VERSION ""

NS_ :

BS_:

BU_: External_Tool CADM LRRF MRRRL MRRRR

BO_ 75 LRRF1_Detection_008_014: 64 LRRF
 SG_ LRRF1_CAN_DET_Near_TARGET_14 : 454|1@0+ (1,0) [0|1] ""  CADM
 SG_ LRRF1_CAN_DET_Near_TARGET_13 : 453|1@0+ (1,0) [0|1] ""  CADM
 SG_ LRRF1_CAN_DET_Near_TARGET_12 : 452|1@0+ (1,0) [0|1] ""  CADM
 SG_ LRRF1_CAN_DET_Near_TARGET_11 : 451|1@0+ (1,0) [0|1] ""  CADM
 SG_ LRRF1_CAN_DET_Near_TARGET_10 : 450|1@0+ (1,0) [0|1] ""  CADM
 SG_ LRRF1_CAN_DET_Near_TARGET_09 : 449|1@0+ (1,0) [0|1] ""  CADM
 SG_ LRRF1_CAN_DET_Near_TARGET_08 : 448|1@0+ (1,0) [0|1] ""  CADM
 SG_ LRRF1_CAN_DET_ELEVATION_08 : 63|7@0+ (0.002748,-0.1745) [-0.1745|0.174496] "rad"  CADM
 SG_ LRRF1_CAN_DET_CONFID_AZIMUTH_08 : 33|2@0+ (1,0) [0|3] ""  CADM
 SG_ LRRF1_CAN_DET_SUPER_RES_TARGET_0 : 56|1@0+ (1,0) [0|1] ""  CADM
 SG_ LRRF1_CAN_DET_CONFID_ELEVATION_0 : 48|1@0+ (1,0) [0|1] ""  CADM
 SG_ LRRF1_CAN_DET_HOST_VEH_CLUTTER_0 : 49|1@0+ (1,0) [0|1] ""  CADM
 SG_ LRRF1_CAN_DET_VALID_LEVEL_08 : 0|1@0+ (1,0) [0|1] ""  CADM
 SG_ LRRF1_CAN_DET_AZIMUTH_08 : 47|14@0+ (0.0003834,-3.1416) [-3.1416|3.1396422] "rad"  CADM
 SG_ LRRF1_CAN_DET_RANGE_08 : 31|14@0+ (0.015625,0) [0|255.984375] "m"  CADM
 SG_ LRRF1_CAN_DET_RANGE_RATE_08 : 15|14@0+ (0.015625,-128) [-128|127.984375] "m/s"  CADM
 SG_ LRRF1_CAN_DET_AMPLITUDE_08 : 7|7@0+ (1,-64) [-64|63] "dBsm"  CADM
 SG_ LRRF1_CAN_SCAN_INDEX_2LSB_08 : 17|2@0+ (1,0) [0|3] ""  CADM
 SG_ LRRF1_Det_CRC_02 : 503|16@0+ (1,0) [0|65535] ""  CADM
 SG_ LRRF1_Det_MC_02 : 491|4@0+ (1,0) [0|15] ""  CADM
 SG_ LRRF1_CAN_SCAN_INDEX_2LSB_14 : 401|2@0+ (1,0) [0|3] ""  CADM
 SG_ LRRF1_CAN_SCAN_INDEX_2LSB_13 : 337|2@0+ (1,0) [0|3] ""  CADM
 SG_ LRRF1_CAN_SCAN_INDEX_2LSB_12 : 273|2@0+ (1,0) [0|3] ""  CADM
 SG_ LRRF1_CAN_SCAN_INDEX_2LSB_11 : 209|2@0+ (1,0) [0|3] ""  CADM
 SG_ LRRF1_CAN_SCAN_INDEX_2LSB_10 : 145|2@0+ (1,0) [0|3] ""  CADM
 SG_ LRRF1_CAN_SCAN_INDEX_2LSB_09 : 81|2@0+ (1,0) [0|3] ""  CADM
 SG_ LRRF1_CAN_DET_RANGE_RATE_14 : 399|14@0+ (0.015625,-128) [-128|127.984375] "m/s"  CADM
 SG_ LRRF1_CAN_DET_RANGE_RATE_13 : 335|14@0+ (0.015625,-128) [-128|127.984375] "m/s"  CADM
 SG_ LRRF1_CAN_DET_RANGE_RATE_12 : 271|14@0+ (0.015625,-128) [-128|127.984375] "m/s"  CADM
 SG_ LRRF1_CAN_DET_RANGE_RATE_11 : 207|14@0+ (0.015625,-128) [-128|127.984375] "m/s"  CADM
 SG_ LRRF1_CAN_DET_RANGE_RATE_10 : 143|14@0+ (0.015625,-128) [-128|127.984375] "m/s"  CADM
 SG_ LRRF1_CAN_DET_RANGE_RATE_09 : 79|14@0+ (0.015625,-128) [-128|127.984375] "m/s"  CADM
 SG_ LRRF1_CAN_DET_RANGE_14 : 415|14@0+ (0.015625,0) [0|255.984375] "m"  CADM
 SG_ LRRF1_CAN_DET_RANGE_13 : 351|14@0+ (0.015625,0) [0|255.984375] "m"  CADM
 SG_ LRRF1_CAN_DET_RANGE_12 : 287|14@0+ (0.015625,0) [0|255.984375] "m"  CADM
 SG_ LRRF1_CAN_DET_RANGE_11 : 223|14@0+ (0.015625,0) [0|255.984375] "m"  CADM
 SG_ LRRF1_CAN_DET_RANGE_10 : 159|14@0+ (0.015625,0) [0|255.984375] "m"  CADM
 SG_ LRRF1_CAN_DET_RANGE_09 : 95|14@0+ (0.015625,0) [0|255.984375] "m"  CADM
 SG_ LRRF1_CAN_DET_SUPER_RES_TAR_0105 : 432|1@0+ (1,0) [0|1] ""  CADM
 SG_ LRRF1_CAN_DET_SUPER_RES_TAR_0106 : 368|1@0+ (1,0) [0|1] ""  CADM
 SG_ LRRF1_CAN_DET_SUPER_RES_TAR_0107 : 304|1@0+ (1,0) [0|1] ""  CADM
 SG_ LRRF1_CAN_DET_SUPER_RES_TAR_0108 : 240|1@0+ (1,0) [0|1] ""  CADM
 SG_ LRRF1_CAN_DET_SUPER_RES_TAR_0109 : 176|1@0+ (1,0) [0|1] ""  CADM
 SG_ LRRF1_CAN_DET_SUPER_RES_TAR_0110 : 112|1@0+ (1,0) [0|1] ""  CADM
 SG_ LRRF1_CAN_DET_HOST_VEH_CLUT_0105 : 433|1@0+ (1,0) [0|1] ""  CADM
 SG_ LRRF1_CAN_DET_HOST_VEH_CLUT_0106 : 369|1@0+ (1,0) [0|1] ""  CADM
 SG_ LRRF1_CAN_DET_HOST_VEH_CLUT_0107 : 305|1@0+ (1,0) [0|1] ""  CADM
 SG_ LRRF1_CAN_DET_HOST_VEH_CLUT_0108 : 241|1@0+ (1,0) [0|1] ""  CADM
 SG_ LRRF1_CAN_DET_HOST_VEH_CLUT_0109 : 177|1@0+ (1,0) [0|1] ""  CADM
 SG_ LRRF1_CAN_DET_HOST_VEH_CLUT_0110 : 113|1@0+ (1,0) [0|1] ""  CADM
 SG_ LRRF1_CAN_DET_ELEVATION_14 : 447|7@0+ (0.002748,-0.1745) [-0.1745|0.174496] "rad"  CADM
 SG_ LRRF1_CAN_DET_ELEVATION_13 : 383|7@0+ (0.002748,-0.1745) [-0.1745|0.174496] "rad"  CADM
 SG_ LRRF1_CAN_DET_ELEVATION_12 : 319|7@0+ (0.002748,-0.1745) [-0.1745|0.174496] "rad"  CADM
 SG_ LRRF1_CAN_DET_ELEVATION_11 : 255|7@0+ (0.002748,-0.1745) [-0.1745|0.174496] "rad"  CADM
 SG_ LRRF1_CAN_DET_ELEVATION_10 : 191|7@0+ (0.002748,-0.1745) [-0.1745|0.174496] "rad"  CADM
 SG_ LRRF1_CAN_DET_ELEVATION_09 : 127|7@0+ (0.002748,-0.1745) [-0.1745|0.174496] "rad"  CADM
 SG_ LRRF1_CAN_DET_CONFID_ELEVAT_0105 : 440|1@0+ (1,0) [0|1] ""  CADM
 SG_ LRRF1_CAN_DET_CONFID_ELEVAT_0106 : 376|1@0+ (1,0) [0|1] ""  CADM
 SG_ LRRF1_CAN_DET_CONFID_ELEVAT_0107 : 312|1@0+ (1,0) [0|1] ""  CADM
 SG_ LRRF1_CAN_DET_CONFID_ELEVAT_0108 : 248|1@0+ (1,0) [0|1] ""  CADM
 SG_ LRRF1_CAN_DET_CONFID_ELEVAT_0109 : 184|1@0+ (1,0) [0|1] ""  CADM
 SG_ LRRF1_CAN_DET_CONFID_ELEVAT_0110 : 120|1@0+ (1,0) [0|1] ""  CADM
 SG_ LRRF1_CAN_DET_CONFID_AZIMUTH_14 : 417|2@0+ (1,0) [0|3] ""  CADM
 SG_ LRRF1_CAN_DET_CONFID_AZIMUTH_13 : 353|2@0+ (1,0) [0|3] ""  CADM
 SG_ LRRF1_CAN_DET_CONFID_AZIMUTH_12 : 289|2@0+ (1,0) [0|3] ""  CADM
 SG_ LRRF1_CAN_DET_CONFID_AZIMUTH_11 : 225|2@0+ (1,0) [0|3] ""  CADM
 SG_ LRRF1_CAN_DET_CONFID_AZIMUTH_10 : 161|2@0+ (1,0) [0|3] ""  CADM
 SG_ LRRF1_CAN_DET_CONFID_AZIMUTH_09 : 97|2@0+ (1,0) [0|3] ""  CADM
 SG_ LRRF1_CAN_DET_AZIMUTH_14 : 431|14@0+ (0.0003834,-3.1416) [-3.1416|3.1396422] "rad"  CADM
 SG_ LRRF1_CAN_DET_AZIMUTH_13 : 367|14@0+ (0.0003834,-3.1416) [-3.1416|3.1396422] "rad"  CADM
 SG_ LRRF1_CAN_DET_AZIMUTH_12 : 303|14@0+ (0.0003834,-3.1416) [-3.1416|3.1396422] "rad"  CADM
 SG_ LRRF1_CAN_DET_AZIMUTH_11 : 239|14@0+ (0.0003834,-3.1416) [-3.1416|3.1396422] "rad"  CADM
 SG_ LRRF1_CAN_DET_AZIMUTH_10 : 175|14@0+ (0.0003834,-3.1416) [-3.1416|3.1396422] "rad"  CADM
 SG_ LRRF1_CAN_DET_AZIMUTH_09 : 111|14@0+ (0.0003834,-3.1416) [-3.1416|3.1396422] "rad"  CADM
 SG_ LRRF1_CAN_DET_AMPLITUDE_14 : 391|7@0+ (1,-64) [-64|63] "dBsm"  CADM
 SG_ LRRF1_CAN_DET_AMPLITUDE_13 : 327|7@0+ (1,-64) [-64|63] "dBsm"  CADM
 SG_ LRRF1_CAN_DET_AMPLITUDE_12 : 263|7@0+ (1,-64) [-64|63] "dBsm"  CADM
 SG_ LRRF1_CAN_DET_AMPLITUDE_11 : 199|7@0+ (1,-64) [-64|63] "dBsm"  CADM
 SG_ LRRF1_CAN_DET_AMPLITUDE_10 : 135|7@0+ (1,-64) [-64|63] "dBsm"  CADM
 SG_ LRRF1_CAN_DET_AMPLITUDE_09 : 71|7@0+ (1,-64) [-64|63] "dBsm"  CADM
 SG_ LRRF1_CAN_DET_VALID_LEVEL_14 : 384|1@0+ (1,0) [0|1] ""  CADM
 SG_ LRRF1_CAN_DET_VALID_LEVEL_13 : 320|1@0+ (1,0) [0|1] ""  CADM
 SG_ LRRF1_CAN_DET_VALID_LEVEL_12 : 256|1@0+ (1,0) [0|1] ""  CADM
 SG_ LRRF1_CAN_DET_VALID_LEVEL_11 : 192|1@0+ (1,0) [0|1] ""  CADM
 SG_ LRRF1_CAN_DET_VALID_LEVEL_10 : 128|1@0+ (1,0) [0|1] ""  CADM
 SG_ LRRF1_CAN_DET_VALID_LEVEL_09 : 64|1@0+ (1,0) [0|1] ""  CADM

BO_ 74 LRRF1_Detection_001_007: 64 LRRF
 SG_ LRRF1_CAN_DET_Near_TARGET_07 : 454|1@0+ (1,0) [0|1] ""  CADM
 SG_ LRRF1_CAN_DET_Near_TARGET_06 : 453|1@0+ (1,0) [0|1] ""  CADM
 SG_ LRRF1_CAN_DET_Near_TARGET_05 : 452|1@0+ (1,0) [0|1] ""  CADM
 SG_ LRRF1_CAN_DET_Near_TARGET_04 : 451|1@0+ (1,0) [0|1] ""  CADM
 SG_ LRRF1_CAN_DET_Near_TARGET_03 : 450|1@0+ (1,0) [0|1] ""  CADM
 SG_ LRRF1_CAN_DET_Near_TARGET_02 : 449|1@0+ (1,0) [0|1] ""  CADM
 SG_ LRRF1_CAN_DET_Near_TARGET_01 : 448|1@0+ (1,0) [0|1] ""  CADM
 SG_ LRRF1_CAN_DET_ELEVATION_01 : 63|7@0+ (0.002748,-0.1745) [-0.1745|0.174496] "rad"  CADM
 SG_ LRRF1_CAN_DET_CONFID_AZIMUTH_01 : 33|2@0+ (1,0) [0|3] ""  CADM
 SG_ LRRF1_CAN_DET_SUPER_RES_TAR_0111 : 48|1@0+ (1,0) [0|1] ""  CADM
 SG_ LRRF1_CAN_DET_CONFID_ELEVAT_0111 : 56|1@0+ (1,0) [0|1] ""  CADM
 SG_ LRRF1_CAN_DET_HOST_VEH_CLUT_0111 : 49|1@0+ (1,0) [0|1] ""  CADM
 SG_ LRRF1_CAN_DET_VALID_LEVEL_01 : 0|1@0+ (1,0) [0|1] ""  CADM
 SG_ LRRF1_CAN_DET_AZIMUTH_01 : 47|14@0+ (0.0003834,-3.1416) [-3.1416|3.1396422] "rad"  CADM
 SG_ LRRF1_CAN_DET_RANGE_01 : 31|14@0+ (0.015625,0) [0|255.984375] "m"  CADM
 SG_ LRRF1_CAN_DET_RANGE_RATE_01 : 15|14@0+ (0.015625,-128) [-128|127.984375] "m/s"  CADM
 SG_ LRRF1_CAN_DET_AMPLITUDE_01 : 7|7@0+ (1,-64) [-64|63] "dBsm"  CADM
 SG_ LRRF1_CAN_SCAN_INDEX_2LSB_01 : 17|2@0+ (1,0) [0|3] ""  CADM
 SG_ LRRF1_Det_CRC_01 : 503|16@0+ (1,0) [0|65535] ""  CADM
 SG_ LRRF1_Det_MC_01 : 491|4@0+ (1,0) [0|15] ""  CADM
 SG_ LRRF1_CAN_SCAN_INDEX_2LSB_07 : 401|2@0+ (1,0) [0|3] ""  CADM
 SG_ LRRF1_CAN_SCAN_INDEX_2LSB_06 : 337|2@0+ (1,0) [0|3] ""  CADM
 SG_ LRRF1_CAN_SCAN_INDEX_2LSB_05 : 273|2@0+ (1,0) [0|3] ""  CADM
 SG_ LRRF1_CAN_SCAN_INDEX_2LSB_04 : 209|2@0+ (1,0) [0|3] ""  CADM
 SG_ LRRF1_CAN_SCAN_INDEX_2LSB_03 : 145|2@0+ (1,0) [0|3] ""  CADM
 SG_ LRRF1_CAN_SCAN_INDEX_2LSB_02 : 81|2@0+ (1,0) [0|3] ""  CADM
 SG_ LRRF1_CAN_DET_RANGE_RATE_07 : 399|14@0+ (0.015625,-128) [-128|127.984375] "m/s"  CADM
 SG_ LRRF1_CAN_DET_RANGE_RATE_06 : 335|14@0+ (0.015625,-128) [-128|127.984375] "m/s"  CADM
 SG_ LRRF1_CAN_DET_RANGE_RATE_05 : 271|14@0+ (0.015625,-128) [-128|127.984375] "m/s"  CADM
 SG_ LRRF1_CAN_DET_RANGE_RATE_04 : 207|14@0+ (0.015625,-128) [-128|127.984375] "m/s"  CADM
 SG_ LRRF1_CAN_DET_RANGE_RATE_03 : 143|14@0+ (0.015625,-128) [-128|127.984375] "m/s"  CADM
 SG_ LRRF1_CAN_DET_RANGE_RATE_02 : 79|14@0+ (0.015625,-128) [-128|127.984375] "m/s"  CADM
 SG_ LRRF1_CAN_DET_RANGE_07 : 415|14@0+ (0.015625,0) [0|255.984375] "m"  CADM
 SG_ LRRF1_CAN_DET_RANGE_06 : 351|14@0+ (0.015625,0) [0|255.984375] "m"  CADM
 SG_ LRRF1_CAN_DET_RANGE_05 : 287|14@0+ (0.015625,0) [0|255.984375] "m"  CADM
 SG_ LRRF1_CAN_DET_RANGE_04 : 223|14@0+ (0.015625,0) [0|255.984375] "m"  CADM
 SG_ LRRF1_CAN_DET_RANGE_03 : 159|14@0+ (0.015625,0) [0|255.984375] "m"  CADM
 SG_ LRRF1_CAN_DET_RANGE_02 : 95|14@0+ (0.015625,0) [0|255.984375] "m"  CADM
 SG_ LRRF1_CAN_DET_SUPER_RES_TAR_0112 : 432|1@0+ (1,0) [0|1] ""  CADM
 SG_ LRRF1_CAN_DET_SUPER_RES_TAR_0113 : 368|1@0+ (1,0) [0|1] ""  CADM
 SG_ LRRF1_CAN_DET_SUPER_RES_TAR_0114 : 304|1@0+ (1,0) [0|1] ""  CADM
 SG_ LRRF1_CAN_DET_SUPER_RES_TAR_0115 : 240|1@0+ (1,0) [0|1] ""  CADM
 SG_ LRRF1_CAN_DET_SUPER_RES_TAR_0116 : 176|1@0+ (1,0) [0|1] ""  CADM
 SG_ LRRF1_CAN_DET_SUPER_RES_TAR_0117 : 112|1@0+ (1,0) [0|1] ""  CADM
 SG_ LRRF1_CAN_DET_HOST_VEH_CLUT_0112 : 433|1@0+ (1,0) [0|1] ""  CADM
 SG_ LRRF1_CAN_DET_HOST_VEH_CLUT_0113 : 369|1@0+ (1,0) [0|1] ""  CADM
 SG_ LRRF1_CAN_DET_HOST_VEH_CLUT_0114 : 305|1@0+ (1,0) [0|1] ""  CADM
 SG_ LRRF1_CAN_DET_HOST_VEH_CLUT_0115 : 241|1@0+ (1,0) [0|1] ""  CADM
 SG_ LRRF1_CAN_DET_HOST_VEH_CLUT_0116 : 177|1@0+ (1,0) [0|1] ""  CADM
 SG_ LRRF1_CAN_DET_HOST_VEH_CLUT_0117 : 113|1@0+ (1,0) [0|1] ""  CADM
 SG_ LRRF1_CAN_DET_ELEVATION_07 : 447|7@0+ (0.002748,-0.1745) [-0.1745|0.174496] "rad"  CADM
 SG_ LRRF1_CAN_DET_ELEVATION_06 : 383|7@0+ (0.002748,-0.1745) [-0.1745|0.174496] "rad"  CADM
 SG_ LRRF1_CAN_DET_ELEVATION_05 : 319|7@0+ (0.002748,-0.1745) [-0.1745|0.174496] "rad"  CADM
 SG_ LRRF1_CAN_DET_ELEVATION_04 : 255|7@0+ (0.002748,-0.1745) [-0.1745|0.174496] "rad"  CADM
 SG_ LRRF1_CAN_DET_ELEVATION_03 : 191|7@0+ (0.002748,-0.1745) [-0.1745|0.174496] "rad"  CADM
 SG_ LRRF1_CAN_DET_ELEVATION_02 : 127|7@0+ (0.002748,-0.1745) [-0.1745|0.174496] "rad"  CADM
 SG_ LRRF1_CAN_DET_CONFID_ELEVAT_0112 : 440|1@0+ (1,0) [0|1] ""  CADM
 SG_ LRRF1_CAN_DET_CONFID_ELEVAT_0113 : 376|1@0+ (1,0) [0|1] ""  CADM
 SG_ LRRF1_CAN_DET_CONFID_ELEVAT_0114 : 312|1@0+ (1,0) [0|1] ""  CADM
 SG_ LRRF1_CAN_DET_CONFID_ELEVAT_0115 : 248|1@0+ (1,0) [0|1] ""  CADM
 SG_ LRRF1_CAN_DET_CONFID_ELEVAT_0116 : 184|1@0+ (1,0) [0|1] ""  CADM
 SG_ LRRF1_CAN_DET_CONFID_ELEVAT_0117 : 120|1@0+ (1,0) [0|1] ""  CADM
 SG_ LRRF1_CAN_DET_CONFID_AZIMUTH_07 : 417|2@0+ (1,0) [0|3] ""  CADM
 SG_ LRRF1_CAN_DET_CONFID_AZIMUTH_06 : 353|2@0+ (1,0) [0|3] ""  CADM
 SG_ LRRF1_CAN_DET_CONFID_AZIMUTH_05 : 289|2@0+ (1,0) [0|3] ""  CADM
 SG_ LRRF1_CAN_DET_CONFID_AZIMUTH_04 : 225|2@0+ (1,0) [0|3] ""  CADM
 SG_ LRRF1_CAN_DET_CONFID_AZIMUTH_03 : 161|2@0+ (1,0) [0|3] ""  CADM
 SG_ LRRF1_CAN_DET_CONFID_AZIMUTH_02 : 97|2@0+ (1,0) [0|3] ""  CADM
 SG_ LRRF1_CAN_DET_AZIMUTH_07 : 431|14@0+ (0.0003834,-3.1416) [-3.1416|3.1396422] "rad"  CADM
 SG_ LRRF1_CAN_DET_AZIMUTH_06 : 367|14@0+ (0.0003834,-3.1416) [-3.1416|3.1396422] "rad"  CADM
 SG_ LRRF1_CAN_DET_AZIMUTH_05 : 303|14@0+ (0.0003834,-3.1416) [-3.1416|3.1396422] "rad"  CADM
 SG_ LRRF1_CAN_DET_AZIMUTH_04 : 239|14@0+ (0.0003834,-3.1416) [-3.1416|3.1396422] "rad"  CADM
 SG_ LRRF1_CAN_DET_AZIMUTH_03 : 175|14@0+ (0.0003834,-3.1416) [-3.1416|3.1396422] "rad"  CADM
 SG_ LRRF1_CAN_DET_AZIMUTH_02 : 111|14@0+ (0.0003834,-3.1416) [-3.1416|3.1396422] "rad"  CADM
 SG_ LRRF1_CAN_DET_AMPLITUDE_07 : 391|7@0+ (1,-64) [-64|63] "dBsm"  CADM
 SG_ LRRF1_CAN_DET_AMPLITUDE_06 : 327|7@0+ (1,-64) [-64|63] "dBsm"  CADM
 SG_ LRRF1_CAN_DET_AMPLITUDE_05 : 263|7@0+ (1,-64) [-64|63] "dBsm"  CADM
 SG_ LRRF1_CAN_DET_AMPLITUDE_04 : 199|7@0+ (1,-64) [-64|63] "dBsm"  CADM
 SG_ LRRF1_CAN_DET_AMPLITUDE_03 : 135|7@0+ (1,-64) [-64|63] "dBsm"  CADM
 SG_ LRRF1_CAN_DET_AMPLITUDE_02 : 71|7@0+ (1,-64) [-64|63] "dBsm"  CADM
 SG_ LRRF1_CAN_DET_VALID_LEVEL_07 : 384|1@0+ (1,0) [0|1] ""  CADM
 SG_ LRRF1_CAN_DET_VALID_LEVEL_06 : 320|1@0+ (1,0) [0|1] ""  CADM
 SG_ LRRF1_CAN_DET_VALID_LEVEL_05 : 256|1@0+ (1,0) [0|1] ""  CADM
 SG_ LRRF1_CAN_DET_VALID_LEVEL_04 : 192|1@0+ (1,0) [0|1] ""  CADM
 SG_ LRRF1_CAN_DET_VALID_LEVEL_03 : 128|1@0+ (1,0) [0|1] ""  CADM
 SG_ LRRF1_CAN_DET_VALID_LEVEL_02 : 64|1@0+ (1,0) [0|1] ""  CADM

BO_ 65 LRRF1_Status_Radar: 16 LRRF
 SG_ LRRF1_System_Operation_Mode_Stat : 87|2@0+ (1,0) [0|3] ""  CADM
 SG_ LRRF1_Status_Radar_CRC : 119|16@0+ (1,0) [0|65535] ""  CADM
 SG_ LRRF1_Status_Radar_MC : 107|4@0+ (1,0) [0|15] ""  CADM
 SG_ LRRF1_CAN_Core2_Cpu_Load : 79|8@0+ (0.5,0) [0|100] "%"  CADM
 SG_ LRRF1_CAN_Core1_Cpu_Load : 71|8@0+ (0.5,0) [0|100] "%"  CADM
 SG_ LRRF1_CAN_Core0_Cpu_Load : 63|8@0+ (0.5,0) [0|100] "%"  CADM
 SG_ LRRF1_CAN_RADAR_CommonModeFailur : 22|2@0+ (1,0) [0|3] "NA"  CADM
 SG_ LRRF1_CAN_BLOCKAGE_COMPLETE : 23|1@0+ (1,0) [0|1] ""  CADM
 SG_ LRRF1_CAN_INTERFERENCE_TYPE : 11|2@0+ (1,0) [0|3] ""  CADM
 SG_ LRRF1_CAN_RECOMMEND_UNCONVERGE : 9|1@0+ (1,0) [0|1] ""  CADM
 SG_ LRRF1_CAN_BLKG_SIDELOBE_FILTER_V : 15|4@0+ (1,0) [0|15] ""  CADM
 SG_ RadarAlignment_FA_SER_Incomplete : 8|1@0+ (1,0) [0|1] ""  CADM
 SG_ RadarBlockageSidelobe_LRRF : 4|1@0+ (1,0) [0|1] ""  CADM
 SG_ LRRF1_CAN_BLOCKAGE_MNR : 5|1@0+ (1,0) [0|1] ""  CADM
 SG_ RadarExternalConditionsNotOK_LRR : 1|1@0+ (1,0) [0|1] ""  CADM
 SG_ RadarAlignment_FA_SER_OutOfRange : 2|1@0+ (1,0) [0|1] ""  CADM
 SG_ RadarAlignment_FA_SER_NotStarted : 0|1@0+ (1,0) [0|1] ""  CADM
 SG_ LRRF1_CAN_RADAR_OVERHEAT_ERROR : 3|1@0+ (1,0) [0|1] ""  CADM
 SG_ RadarSensorNotOperational_LRRF : 6|1@0+ (1,0) [0|1] ""  CADM
 SG_ LRRF1_CAN_XCVR_OPERATIONAL : 7|1@0+ (1,0) [0|1] ""  CADM

BO_ 673 MRR_CADM_TracksChange: 1 CADM
 SG_ MRR_f_Radar_Unreasonable : 7|1@0+ (1,0) [0|1] ""  MRRRL,MRRRR

BO_ 267 MRR_RR_Header_AlignmentState: 16 MRRRR
 SG_ MRR_RR_CAN_VRTCL_ALIGN_UPDATES_N : 87|16@0+ (1,0) [0|65535] ""  CADM,External_Tool
 SG_ MRR_RR_CAN_HRZNTL_ALIGN_UPDATES_ : 71|16@0+ (1,0) [0|65535] ""  CADM,External_Tool
 SG_ MRR_RR_Header_AlignmentState_CRC : 119|16@0+ (1,0) [0|65535] ""  CADM,External_Tool
 SG_ MRR_RR_Header_AlignmentState_MC : 107|4@0+ (1,0) [0|15] ""  CADM,External_Tool
 SG_ MRR_RR_Horizontal_Alignment_Stat : 27|4@0+ (1,0) [0|15] ""  CADM,External_Tool
 SG_ MRR_RR_Vertical_Alignment_Status : 59|4@0+ (1,0) [0|15] ""  CADM,External_Tool
 SG_ MRR_RR_Vertical_Alignment_State : 44|3@0+ (1,0) [0|7] ""  CADM,External_Tool
 SG_ MRR_RR_Horizontal_Alignment_0000 : 12|3@0+ (1,0) [0|7] ""  CADM,External_Tool
 SG_ MRR_RR_Align_Vertical_Ref : 55|10@0+ (0.000170608920038546,-0.0872664625997165) [-0.0872664625997165|0.0872664625997165] "Rad"  CADM,External_Tool
 SG_ MRR_RR_Align_Vertical_QF : 41|2@0+ (1,0) [0|3] ""  CADM,External_Tool
 SG_ MRR_RR_Align_Vertical_Angle : 39|10@0+ (0.000170608920038546,-0.0872664625997165) [-0.0872664625997165|0.0872664625997165] "Rad"  CADM,External_Tool
 SG_ MRR_RR_Align_Horizontal_Angle : 7|10@0+ (0.000341217840077093,-0.174532925199433) [-0.174532925199433|0.174532925199433] "Rad"  CADM,External_Tool
 SG_ MRR_RR_Align_Horizontal_Ref : 23|10@0+ (0.000341217840077093,-0.174532925199433) [-0.174532925199433|0.174532925199433] "Rad"  CADM,External_Tool
 SG_ MRR_RR_Align_Horizontal_QF : 9|2@0+ (1,0) [0|3] ""  CADM,External_Tool

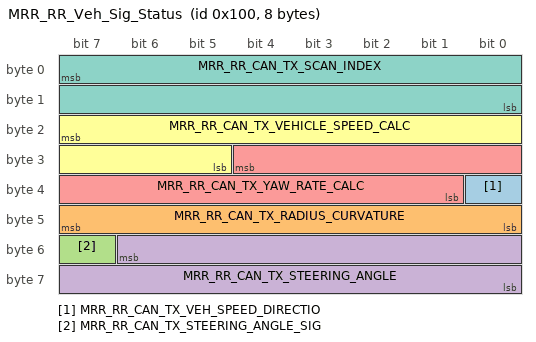
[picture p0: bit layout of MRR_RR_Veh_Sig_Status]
BO_ 256 MRR_RR_Veh_Sig_Status: 8 MRRRR
 SG_ MRR_RR_CAN_TX_VEH_SPEED_DIRECTIO : 32|1@0+ (1,0) [0|1] ""  CADM
 SG_ MRR_RR_CAN_TX_RADIUS_CURVATURE : 47|8@0- (25,0) [-3200|3175] "m"  CADM
 SG_ MRR_RR_CAN_TX_STEERING_ANGLE_SIG : 55|1@0+ (1,0) [0|1] ""  CADM
 SG_ MRR_RR_CAN_TX_STEERING_ANGLE : 54|15@0+ (1,0) [0|32767] "deg"  CADM
 SG_ MRR_RR_CAN_TX_YAW_RATE_CALC : 28|12@0- (0.0625,0) [-128|127.9375] "deg/s"  CADM
 SG_ MRR_RR_CAN_TX_VEHICLE_SPEED_CALC : 23|11@0+ (0.0625,0) [0|127.9375] "m/s"  CADM
 SG_ MRR_RR_CAN_TX_SCAN_INDEX : 7|16@0+ (1,0) [0|65535] ""  CADM

BO_ 260 MRR_RR_Active_Fault_Status: 20 MRRRR
 SG_ MRR_RR_TO_SystemTDBlockage_Flt : 87|1@0+ (1,0) [0|1] ""  CADM
 SG_ MRR_RR_TO_CADMSWVersion_Flt : 95|1@0+ (1,0) [0|1] ""  CADM
 SG_ MRR_RR_TO_RADARCfgParameter_Flt : 94|1@0+ (1,0) [0|1] ""  CADM
 SG_ MRR_RR_TO_SATCADMVIN_Flt : 93|1@0+ (1,0) [0|1] ""  CADM
 SG_ MRR_RR_TO_CADMTracksChange_Flt : 92|1@0+ (1,0) [0|1] ""  CADM
 SG_ MRR_RR_Active_Fault_Status_CRC : 151|16@0+ (1,0) [0|65535] ""  CADM
 SG_ MRR_RR_Active_Fault_Status_MC : 139|4@0+ (1,0) [0|15] ""  CADM
 SG_ MRR_RR_Dolphin_Flt : 71|1@0+ (1,0) [0|1] ""  CADM
 SG_ MRR_RR_RRUCore_Flt : 70|1@0+ (1,0) [0|1] ""  CADM
 SG_ MRR_RR_RRUBIST_Flt : 72|1@0+ (1,0) [0|1] ""  CADM
 SG_ MRR_RR_PINPosition_Flt : 69|1@0+ (1,0) [0|1] ""  CADM
 SG_ MRR_RR_PCANDataRangeChk_Flt : 68|1@0+ (1,0) [0|1] ""  CADM
 SG_ MRR_RR_TO_AngleAdjustmentTable_F : 88|1@0+ (1,0) [0|1] ""  CADM
 SG_ MRR_RR_TO_CADMSgnlActlVal_Flt : 86|1@0+ (1,0) [0|1] ""  CADM
 SG_ MRR_RR_TO_TrigControl_Flt : 85|1@0+ (1,0) [0|1] ""  CADM
 SG_ MRR_RR_TO_VehicleState_Flt : 84|1@0+ (1,0) [0|1] ""  CADM
 SG_ MRR_RR_MC_AngleAdjTable_Flt : 83|1@0+ (1,0) [0|1] ""  CADM
 SG_ MRR_RR_CRC_AngleAdjTable_Flt : 82|1@0+ (1,0) [0|1] ""  CADM
 SG_ MRR_RR_MC_VehicleState_Flt : 81|1@0+ (1,0) [0|1] ""  CADM
 SG_ MRR_RR_CRC_VehicleState_Flt : 80|1@0+ (1,0) [0|1] ""  CADM
 SG_ MRR_RR_MC_TrigControl_Flt : 79|1@0+ (1,0) [0|1] ""  CADM
 SG_ MRR_RR_CRC_TrigControl_Flt : 78|1@0+ (1,0) [0|1] ""  CADM
 SG_ MRR_RR_CRC_RadarCfgParameter_Flt : 75|1@0+ (1,0) [0|1] ""  CADM
 SG_ MRR_RR_MC_CADMSgnlActlVal_Flt : 74|1@0+ (1,0) [0|1] ""  CADM
 SG_ MRR_RR_CRC_CADMSgnlActlVal_Flt : 73|1@0+ (1,0) [0|1] ""  CADM
 SG_ MRR_RR_VINSignalCompare_Flt : 66|1@0+ (1,0) [0|1] ""  CADM
 SG_ MRR_RR_BatteryLow_Flt : 63|1@0+ (1,0) [0|1] ""  CADM
 SG_ MRR_RR_BatteryHigh_Flt : 62|1@0+ (1,0) [0|1] ""  CADM
 SG_ MRR_RR_Core0_To_Core1_IPC_Flt : 60|1@0+ (1,0) [0|1] ""  CADM
 SG_ MRR_RR_Core1_To_Core0_IPC_Flt : 61|1@0+ (1,0) [0|1] ""  CADM
 SG_ MRR_RR_Core1_To_Core2_IPC_Flt : 59|1@0+ (1,0) [0|1] ""  CADM
 SG_ MRR_RR_Core2_To_Core1_IPC_Flt : 58|1@0+ (1,0) [0|1] ""  CADM
 SG_ MRR_RR_Core2_To_Core0_IPC_Flt : 57|1@0+ (1,0) [0|1] ""  CADM
 SG_ MRR_RR_Core2Halted_Flt : 19|1@0+ (1,0) [0|1] ""  CADM
 SG_ MRR_RR_Core1Halted_Flt : 18|1@0+ (1,0) [0|1] ""  CADM
 SG_ MRR_RR_LocalOscPower_Flt : 50|1@0+ (1,0) [0|1] ""  CADM
 SG_ MRR_RR_DSPLoopOverrun_Flt : 54|1@0+ (1,0) [0|1] ""  CADM
 SG_ MRR_RR_TransmitterPower_Flt : 49|1@0+ (1,0) [0|1] ""  CADM
 SG_ MRR_RR_Core0_To_Core2_IPC_Flt : 56|1@0+ (1,0) [0|1] ""  CADM
 SG_ MRR_RR_XCVRDeviceSPI_Flt : 45|1@0+ (1,0) [0|1] ""  CADM
 SG_ MRR_RR_MNRBlockage_Flt : 40|1@0+ (1,0) [0|1] ""  CADM
 SG_ MRR_RR_TransmitterTempHigh_Flt : 38|1@0+ (1,0) [0|1] ""  CADM
 SG_ MRR_RR_AlignRoutineFailed_Flt : 37|1@0+ (1,0) [0|1] ""  CADM
 SG_ MRR_RR_MicroTempHigh_Flt : 35|1@0+ (1,0) [0|1] ""  CADM
 SG_ MRR_RR_HAlignOutofRange_Flt : 33|1@0+ (1,0) [0|1] ""  CADM
 SG_ MRR_RR_v1p1_SupplyOutOfRange_Flt : 30|1@0+ (1,0) [0|1] ""  CADM
 SG_ MRR_RR_v1p25_SupplyOutOfRange_Fl : 29|1@0+ (1,0) [0|1] ""  CADM
 SG_ MRR_RR_v1p8_SupplyOutOfRange_Flt : 28|1@0+ (1,0) [0|1] ""  CADM
 SG_ MRR_RR_v2p3_SupplyOutOfRange_Flt : 27|1@0+ (1,0) [0|1] ""  CADM
 SG_ MRR_RR_v_5_SupplyOutOfRange_Flt : 24|1@0+ (1,0) [0|1] ""  CADM
 SG_ MRR_RR_TransmitterID_Flt : 23|1@0+ (1,0) [0|1] ""  CADM
 SG_ MRR_RR_PCANBusOff_Flt : 16|1@0+ (1,0) [0|1] ""  CADM
 SG_ MRR_RR_InstructionSetCheck_Flt : 13|1@0+ (1,0) [0|1] ""  CADM
 SG_ MRR_RR_StackOverflow_Flt : 12|1@0+ (1,0) [0|1] ""  CADM
 SG_ MRR_RR_Watchdog_Flt : 11|1@0+ (1,0) [0|1] ""  CADM
 SG_ MRR_RR_PLLLock_Flt : 10|1@0+ (1,0) [0|1] ""  CADM
 SG_ MRR_RR_RAMMemoryTest_Flt : 8|1@0+ (1,0) [0|1] ""  CADM
 SG_ MRR_RR_USCValidation_Flt : 7|1@0+ (1,0) [0|1] ""  CADM
 SG_ MRR_RR_SMCChecksum_Flt : 4|1@0+ (1,0) [0|1] ""  CADM
 SG_ MRR_RR_KeepAliveChecksum_Flt : 2|1@0+ (1,0) [0|1] ""  CADM
 SG_ MRR_RR_ApplicationFlashChksum_Fl : 0|1@0+ (1,0) [0|1] ""  CADM

BO_ 259 MRR_RR_Alignment_Status: 12 MRRRR
 SG_ MRR_RR_Alignment_Status_CRC : 87|16@0+ (1,0) [0|65535] ""  CADM
 SG_ MRR_RR_Alignment_Status_MC : 75|4@0+ (1,0) [0|15] ""  CADM
 SG_ MRR_RR_CAN_TX_DRIVING_ENVIRONMEN : 41|2@0+ (1,0) [0|3] ""  CADM
 SG_ MRR_RR_CAN_TX_ROLLING_COUNT_1 : 33|2@0+ (1,0) [0|3] ""  CADM
 SG_ MRR_RR_CAN_TX_Temperature : 63|8@0+ (1,-50) [-50|205] "degC"  CADM
 SG_ MRR_RR_CAN_TX_YAW_RATE_BIAS : 55|8@0- (0.125,0) [-16|15.875] ""  CADM
 SG_ MRR_RR_CAN_TX_VEH_SPD_COMP_FACTO : 47|6@0- (0.001953125,1) [0.9375|1.060546875] ""  CADM
 SG_ MRR_RR_CAN_TX_AUTO_ALIGN_QUA_FAC : 35|2@0+ (1,0) [0|3] ""  CADM
 SG_ MRR_RR_CAN_TX_Alignment_MODE : 39|4@0+ (1,0) [0|15] ""  CADM
 SG_ MRR_RR_CAN_TX_CURRENT_MISALIGN_A : 23|16@0- (0.0009765625,0) [-32|31.9990234375] "Deg"  CADM
 SG_ MRR_RR_CAN_TX_SAVED_MISALIGN_ANG : 7|16@0- (0.0009765625,0) [-32|31.9990234375] "Deg"  CADM

BO_ 257 MRR_RR_HW_Version_Status: 64 MRRRR
 SG_ MRR_RR_Dolphin_Chip_ID_Part2 : 327|64@0+ (1,0) [0|1.84467440737096E+019] ""  CADM,External_Tool
 SG_ MRR_RR_Dolphin_Chip_ID_Part1 : 263|64@0+ (1,0) [0|1.84467440737096E+019] ""  CADM,External_Tool
 SG_ MRR_RR_RRU_Chip_ID_Part4 : 199|64@0+ (1,0) [0|1.84467440737096E+019] ""  CADM,External_Tool
 SG_ MRR_RR_RRU_Chip_ID_Part3 : 135|64@0+ (1,0) [0|1.84467440737096E+019] ""  CADM,External_Tool
 SG_ MRR_RR_RRU_Chip_ID_Part2 : 71|64@0+ (1,0) [0|1.84467440737096E+019] ""  CADM,External_Tool
 SG_ MRR_RR_RRU_Chip_ID_Part1 : 7|64@0+ (1,0) [0|1.84467440737096E+019] ""  CADM,External_Tool
 SG_ MRR_RR_CAN_TX_HW_VERSION : 391|4@0+ (1,0) [0|15] ""  CADM,External_Tool

BO_ 258 MRR_RR_SW_Version_Status: 48 MRRRR
 SG_ MRR_RR_CAN_PCAN_PROTOCOL_PROMOTE : 263|8@0+ (1,0) [0|255] ""  CADM,External_Tool
 SG_ MRR_RR_CAN_TX_SW_VERSION_DSP : 295|24@0+ (1,0) [0|16777215] ""  External_Tool,CADM
 SG_ MRR_RR_CAN_TX_SW_VERSION_ARM : 271|24@0+ (1,0) [0|16777215] ""  External_Tool,CADM
 SG_ MRR_RR_CAN_TX_PCAN_PROTOCOL_MINO : 243|8@0+ (1,0) [0|255] ""  External_Tool,CADM
 SG_ MRR_RR_CAN_TX_PCAN_PROTOCOL_MAJO : 247|4@0+ (1,0) [0|15] ""  External_Tool,CADM
 SG_ MRR_RR_CAN_Dyn_Align_Algorithm_V : 223|8@0+ (1,0) [0|255] ""  External_Tool,CADM
 SG_ MRR_RR_CAN_Dyn_Align_Algori_0000 : 231|8@0+ (1,0) [0|255] ""  External_Tool,CADM
 SG_ MRR_RR_CAN_Dyn_Align_Algori_0001 : 239|8@0+ (1,0) [0|255] ""  External_Tool,CADM
 SG_ MRR_RR_Core_Radar_BB_Version_Fie : 215|8@0+ (1,0) [0|255] ""  CADM
 SG_ MRR_RR_Core_Radar_BB_Version_Pro : 207|8@0+ (1,0) [0|255] ""  CADM
 SG_ MRR_RR_Core_Radar_BB_Version_Min : 199|8@0+ (1,0) [0|255] ""  CADM
 SG_ MRR_RR_Core_Radar_BB_Version_Maj : 191|8@0+ (1,0) [0|255] ""  CADM
 SG_ MRR_RR_CAN_USC_Field : 183|8@0+ (1,0) [0|255] ""  CADM
 SG_ MRR_RR_CAN_USC_Promote : 175|8@0+ (1,0) [0|255] ""  CADM
 SG_ MRR_RR_CAN_USC_Minor : 167|8@0+ (1,0) [0|255] ""  CADM
 SG_ MRR_RR_CAN_USC_Major : 159|8@0+ (1,0) [0|255] ""  CADM
 SG_ MRR_RR_CAN_SMC_Field : 151|8@0+ (1,0) [0|255] ""  CADM
 SG_ MRR_RR_CAN_SMC_Promote : 143|8@0+ (1,0) [0|255] ""  CADM
 SG_ MRR_RR_CAN_SMC_Minor : 135|8@0+ (1,0) [0|255] ""  CADM
 SG_ MRR_RR_CAN_SMC_Major : 127|8@0+ (1,0) [0|255] ""  CADM
 SG_ MRR_RR_CAN_TX_Field : 23|8@0+ (1,0) [0|255] ""  CADM
 SG_ MRR_RR_CAN_TX_Promote : 13|6@0+ (1,0) [0|63] ""  CADM
 SG_ MRR_RR_CAN_TX_Major : 3|6@0+ (1,0) [0|63] ""  CADM
 SG_ MRR_RR_CAN_TX_Hardware : 7|4@0+ (1,0) [0|15] ""  CADM
 SG_ MRR_RR_CAN_TX_SERIAL_NUMBER_SEQU : 35|12@0+ (1,0) [0|4095] ""  CADM
 SG_ MRR_RR_CAN_TX_SERIAL_NUM_JULIAN_ : 38|3@0+ (1,2014) [2014|2021] ""  CADM
 SG_ MRR_RR_CAN_TX_SERIAL_NUM_JU_0000 : 31|9@0+ (1,0) [0|511] ""  CADM
 SG_ MRR_RR_CAN_TX_ARM_THROUGHPUT : 63|5@0+ (3.2258,0) [0|99.9998] ""  CADM
 SG_ MRR_RR_CAN_TX_SYSTEM_STATUS : 58|3@0+ (1,0) [0|7] ""  CADM
 SG_ MRR_RR_CAN_TX_LOOK_TYPE_1 : 50|1@0+ (1,0) [0|1] ""  CADM
 SG_ MRR_RR_CAN_TX_OVERHEAT_ERROR : 51|1@0+ (1,0) [0|1] ""  CADM
 SG_ MRR_RR_CAN_TX_RANGE_PERF_ERROR : 52|1@0+ (1,0) [0|1] ""  CADM
 SG_ MRR_RR_CAN_TX_COMM_ERROR : 53|1@0+ (1,0) [0|1] ""  CADM
 SG_ MRR_RR_CAN_TX_INTERNAL_ERROR : 54|1@0+ (1,0) [0|1] ""  CADM
 SG_ MRR_RR_CAN_TX_XCVR_OPERATIONAL : 55|1@0+ (1,0) [0|1] ""  CADM
 SG_ MRR_RR_CAN_PBL_Field_Revision : 119|8@0+ (1,0) [0|255] ""  CADM
 SG_ MRR_RR_CAN_PBL_Promote_Revision : 111|8@0+ (1,0) [0|255] ""  CADM
 SG_ MRR_RR_CAN_SW_Field_Revision : 87|8@0+ (1,0) [0|255] ""  CADM
 SG_ MRR_RR_CAN_SW_Promote_Revision : 79|8@0+ (1,0) [0|255] ""  CADM
 SG_ MRR_RR_CAN_SW_Field : 95|8@0+ (1,0) [0|255] ""  CADM
 SG_ MRR_RR_CAN_SW_Release_Revision : 71|8@0+ (1,0) [0|255] ""  CADM
 SG_ MRR_RR_CAN_PBL_Release_Revision : 103|8@0+ (1,0) [0|255] ""  CADM

BO_ 261 MRR_RR_Error_Status: 32 MRRRR
 SG_ MRR_RR_RRU_Self_Test_Faults_reas : 239|8@0+ (1,0) [0|255] ""  External_Tool
 SG_ MRR_RR_RRU_Core_Faults_reason3 : 231|8@0+ (1,0) [0|255] ""  External_Tool
 SG_ MRR_RR_RRU_Core_Faults_reason2 : 167|64@0+ (1,0) [0|1.84467440737096E+019] ""  External_Tool
 SG_ MRR_RR_RRU_Core_Faults_reason1 : 103|64@0+ (1,0) [0|1.84467440737096E+019] ""  External_Tool
 SG_ MRR_RR_XBAR_cfg_failure : 255|1@0+ (1,0) [0|1] ""  External_Tool
 SG_ MRR_RR_Stack_OVF_fault_reason : 247|3@0+ (1,0) [0|7] ""  External_Tool
 SG_ MRR_RR_App_flash_checksum_reason : 244|3@0+ (1,0) [0|7] ""  External_Tool
 SG_ MRR_RR_KAM_fault_reason : 241|2@0+ (1,0) [0|3] ""  External_Tool
 SG_ MRR_RR_Rx_Radar_Mount_Msg_Fault : 88|1@0+ (1,0) [0|1] ""  External_Tool
 SG_ MRR_RR_Dolphin_Fault_Detection : 87|8@0+ (1,0) [0|63] ""  External_Tool
 SG_ MRR_RR_RRU_Self_Test_Faults_0000 : 79|8@0+ (1,0) [0|255] ""  External_Tool
 SG_ MRR_RR_RRU_Core_Faults_reason0 : 71|8@0+ (1,0) [0|255] ""  External_Tool
 SG_ MRR_RR_USC_Load_Error : 59|1@0+ (1,0) [0|1] ""  External_Tool
 SG_ MRR_RR_SMC_Load_Error : 58|1@0+ (1,0) [0|1] ""  External_Tool
 SG_ MRR_RR_TX_Temperature_Flt : 57|1@0+ (1,0) [0|1] ""  External_Tool
 SG_ MRR_RR_Dsp_Unit_Cal_Blk_Chcksm_E : 56|1@0+ (1,0) [0|1] ""  External_Tool
 SG_ MRR_RR_Dsp_Unit_Cal_Checksum_Err : 55|1@0+ (1,0) [0|1] ""  External_Tool
 SG_ MRR_RR_Vertical_Misalignment_err : 54|1@0+ (1,0) [0|1] ""  External_Tool
 SG_ MRR_RR_RTN_SPI_Transfer_Error : 53|1@0+ (1,0) [0|1] ""  External_Tool
 SG_ MRR_RR_RRN_SPI_Transfer_Error : 52|1@0+ (1,0) [0|1] ""  External_Tool
 SG_ MRR_RR_Linearizer_SPI_Transfer_E : 51|1@0+ (1,0) [0|1] ""  External_Tool
 SG_ MRR_RR_ADC_SPI_Transfer_Error : 50|1@0+ (1,0) [0|1] ""  External_Tool
 SG_ MRR_RR_Transmitter_ID_Error : 49|1@0+ (1,0) [0|1] ""  External_Tool
 SG_ MRR_RR_Dsp_Loop_Overrun_Error : 48|1@0+ (1,0) [0|1] ""  External_Tool
 SG_ MRR_RR_Saturated_Tuning_Freq_Err : 47|1@0+ (1,0) [0|1] ""  External_Tool
 SG_ MRR_RR_Radar_Data_sync_error : 46|1@0+ (1,0) [0|1] ""  External_Tool
 SG_ MRR_RR_Dsp_Tuning_Sensitivity_Er : 45|1@0+ (1,0) [0|1] ""  External_Tool
 SG_ MRR_RR_Radar_LO_Power_Error : 44|1@0+ (1,0) [0|1] ""  External_Tool
 SG_ MRR_RR_Radar_TX_Power_Error : 43|1@0+ (1,0) [0|1] ""  External_Tool
 SG_ MRR_RR_Timer_Create_Error : 6|1@0+ (1,0) [0|1] ""  External_Tool
 SG_ MRR_RR_Thread_Create_Error : 2|1@0+ (1,0) [0|1] ""  External_Tool
 SG_ MRR_RR_ARM_Calibration_Error : 9|1@0+ (1,0) [0|1] ""  External_Tool
 SG_ MRR_RR_SPI_FEE_Error : 14|1@0+ (1,0) [0|1] ""  External_Tool
 SG_ MRR_RR_SPI_Comm_Error : 13|1@0+ (1,0) [0|1] ""  External_Tool
 SG_ MRR_RR_Socket_Write_Error : 39|1@0+ (1,0) [0|1] ""  External_Tool
 SG_ MRR_RR_Socket_Read_error : 38|1@0+ (1,0) [0|1] ""  External_Tool
 SG_ MRR_RR_Socket_Init_Error : 37|1@0+ (1,0) [0|1] ""  External_Tool
 SG_ MRR_RR_Signal_Wait_Error : 4|1@0+ (1,0) [0|1] ""  External_Tool
 SG_ MRR_RR_Signal_Send_Error : 5|1@0+ (1,0) [0|1] ""  External_Tool
 SG_ MRR_RR_Signal_Create_Error : 3|1@0+ (1,0) [0|1] ""  External_Tool
 SG_ MRR_RR_Shared_Mem_Write_Error : 21|1@0+ (1,0) [0|1] ""  External_Tool
 SG_ MRR_RR_Shared_Mem_Read_Error : 20|1@0+ (1,0) [0|1] ""  External_Tool
 SG_ MRR_RR_Shared_Mem_Config_Error : 19|1@0+ (1,0) [0|1] ""  External_Tool
 SG_ MRR_RR_Share_Mem_Init_Error : 18|1@0+ (1,0) [0|1] ""  External_Tool
 SG_ MRR_RR_RAM_Test_Error : 1|1@0+ (1,0) [0|1] ""  External_Tool
 SG_ MRR_RR_Num_Errors : 63|1@0+ (1,0) [0|1] ""  External_Tool
 SG_ MRR_RR_MMAP_Memory_Error : 40|1@0+ (1,0) [0|1] ""  External_Tool
 SG_ MRR_RR_ISR_Attach_Error : 36|1@0+ (1,0) [0|1] ""  External_Tool
 SG_ MRR_RR_IPC_DRV_Write_Error : 29|1@0+ (1,0) [0|1] ""  External_Tool
 SG_ MRR_RR_IPC_DRV_Trigger_Error : 31|1@0+ (1,0) [0|1] ""  External_Tool
 SG_ MRR_RR_IPC_DRV_Sync_Error : 30|1@0+ (1,0) [0|1] ""  External_Tool
 SG_ MRR_RR_IPC_DRV_Read_Error : 28|1@0+ (1,0) [0|1] ""  External_Tool
 SG_ MRR_RR_IPC_DRV_Init_Error : 27|1@0+ (1,0) [0|1] ""  External_Tool
 SG_ MRR_RR_Interrupt_Enable_Error : 42|1@0+ (1,0) [0|1] ""  External_Tool
 SG_ MRR_RR_HIL_Format_Error : 41|1@0+ (1,0) [0|1] ""  External_Tool
 SG_ MRR_RR_Flash_Filesystem_Error : 7|1@0+ (1,0) [0|1] ""  External_Tool
 SG_ MRR_RR_Error_none : 0|1@0+ (1,0) [0|1] ""  External_Tool
 SG_ MRR_RR_Dsp_Load_Read_Error : 34|1@0+ (1,0) [0|1] ""  External_Tool
 SG_ MRR_RR_Dsp_Load_Open_Error : 33|1@0+ (1,0) [0|1] ""  External_Tool
 SG_ MRR_RR_Dsp_Load_Address_Error : 35|1@0+ (1,0) [0|1] ""  External_Tool
 SG_ MRR_RR_Dsp_ISP_Write_Error : 17|1@0+ (1,0) [0|1] ""  External_Tool
 SG_ MRR_RR_Dsp_IPC_Read_Error : 16|1@0+ (1,0) [0|1] ""  External_Tool
 SG_ MRR_RR_Dsp_IPC_Init : 15|1@0+ (1,0) [0|1] ""  External_Tool
 SG_ MRR_RR_Dsp_Init_Error : 32|1@0+ (1,0) [0|1] ""  External_Tool
 SG_ MRR_RR_Dsp_DRV_Start_Error : 26|1@0+ (1,0) [0|1] ""  External_Tool
 SG_ MRR_RR_Dsp_DRV_Load_Error : 25|1@0+ (1,0) [0|1] ""  External_Tool
 SG_ MRR_RR_Dsp_DRV_Init_Error : 22|1@0+ (1,0) [0|1] ""  External_Tool
 SG_ MRR_RR_Dsp_DRV_Init2_error : 24|1@0+ (1,0) [0|1] ""  External_Tool
 SG_ MRR_RR_Dsp_DRV_Init1_error : 23|1@0+ (1,0) [0|1] ""  External_Tool
 SG_ MRR_RR_CAN_XMT_Error : 10|1@0+ (1,0) [0|1] ""  External_Tool
 SG_ MRR_RR_CAN_RCV_Error : 11|1@0+ (1,0) [0|1] ""  External_Tool
 SG_ MRR_RR_CAN_Hardware_Error : 12|1@0+ (1,0) [0|1] ""  External_Tool
 SG_ MRR_RR_Always_True : 62|1@0+ (1,0) [0|1] ""  External_Tool

BO_ 264 MRR_RR_Header_SensorCoverage: 12 MRRRR
 SG_ MRR_RR_Radar_Spec_Status_CRC : 87|16@0+ (1,0) [0|65535] ""  CADM,External_Tool
 SG_ MRR_RR_Radar_Spec_Status_MC : 75|4@0+ (1,0) [0|15] ""  CADM,External_Tool
 SG_ MRR_CAN_RadarWaveform_RR : 79|3@0+ (1,0) [0|7] ""  External_Tool,CADM
 SG_ MRR_RR_CAN_RANGE_COVERAGE : 7|14@0+ (0.015625,0) [0|255.984375] "m"  External_Tool,CADM
 SG_ MRR_RR_CAN_DOPPLER_COVERAGE : 23|14@0+ (0.015625,0) [0|255.984375] "m/s"  External_Tool,CADM
 SG_ MRR_RR_CAN_FOV_HOR : 39|8@0+ (1,0) [0|255] "deg"  External_Tool,CADM
 SG_ MRR_RR_CAN_FOV_VER : 47|8@0+ (1,0) [0|255] "deg"  External_Tool,CADM

BO_ 269 MRR_RR_Status_Temp_Volt: 12 MRRRR
 SG_ MRR_RR_CAN_Dolphin_AFC : 95|8@0+ (1,-50) [-50|205] "C"  CADM,External_Tool
 SG_ MRR_RR_CAN_Dolphin_Tx3 : 87|8@0+ (1,-50) [-50|205] "C"  CADM,External_Tool
 SG_ MRR_RR_CAN_Dolphin_Tx2 : 79|8@0+ (1,-50) [-50|205] "C"  CADM,External_Tool
 SG_ MRR_RR_CAN_1_8_V : 71|8@0+ (0.08,0) [0|20.4] "V"  External_Tool
 SG_ MRR_RR_CAN_BATT_VOLTS : 63|8@0+ (0.08,0) [0|20.4] "V"  External_Tool
 SG_ MRR_RR_CAN_1_25_V : 55|8@0+ (0.08,0) [0|20.4] "V"  External_Tool
 SG_ MRR_RR_CAN_5_V : 47|8@0+ (0.08,0) [0|20.4] "V"  External_Tool
 SG_ MRR_RR_CAN_1_1_V : 31|8@0+ (0.08,0) [0|20.4] "V"  External_Tool
 SG_ MRR_RR_CAN_2_3_V : 15|8@0+ (0.08,0) [0|20.4] "V"  External_Tool
 SG_ MRR_RR_CAN_Dolphin_Tx1 : 39|8@0+ (1,-50) [-50|205] "C"  CADM,External_Tool
 SG_ MRR_RR_CAN_RRU_Temp1 : 7|8@0+ (1,-50) [-50|205] "C"  CADM,External_Tool

BO_ 1536 MRR_RR_Detection_001_007: 64 MRRRR
 SG_ MRR_RR_CAN_DET_MID_TARGET_007 : 462|1@0+ (1,0) [0|1] ""  CADM
 SG_ MRR_RR_CAN_DET_MID_TARGET_006 : 461|1@0+ (1,0) [0|1] ""  CADM
 SG_ MRR_RR_CAN_DET_MID_TARGET_005 : 460|1@0+ (1,0) [0|1] ""  CADM
 SG_ MRR_RR_CAN_DET_MID_TARGET_004 : 459|1@0+ (1,0) [0|1] ""  CADM
 SG_ MRR_RR_CAN_DET_MID_TARGET_003 : 458|1@0+ (1,0) [0|1] ""  CADM
 SG_ MRR_RR_CAN_DET_MID_TARGET_002 : 457|1@0+ (1,0) [0|1] ""  CADM
 SG_ MRR_RR_CAN_DET_MID_TARGET_001 : 456|1@0+ (1,0) [0|1] ""  CADM
 SG_ MRR_RR_CAN_DET_Near_TARGET_007 : 454|1@0+ (1,0) [0|1] ""  CADM
 SG_ MRR_RR_CAN_DET_Near_TARGET_006 : 453|1@0+ (1,0) [0|1] ""  CADM
 SG_ MRR_RR_CAN_DET_Near_TARGET_005 : 452|1@0+ (1,0) [0|1] ""  CADM
 SG_ MRR_RR_CAN_DET_Near_TARGET_004 : 451|1@0+ (1,0) [0|1] ""  CADM
 SG_ MRR_RR_CAN_DET_Near_TARGET_003 : 450|1@0+ (1,0) [0|1] ""  CADM
 SG_ MRR_RR_CAN_DET_Near_TARGET_002 : 449|1@0+ (1,0) [0|1] ""  CADM
 SG_ MRR_RR_CAN_DET_Near_TARGET_001 : 448|1@0+ (1,0) [0|1] ""  CADM
 SG_ MRR_RR_DET_MC_001 : 491|4@0+ (1,0) [0|15] ""  CADM
 SG_ MRR_RR_DET_CRC_001 : 503|16@0+ (1,0) [0|65535] ""  CADM
 SG_ MRR_RR_CAN_DET_ELEVATION_007 : 447|7@0+ (0.002748,-0.1745) [-0.1745|0.174496] "rad"  CADM
 SG_ MRR_RR_CAN_DET_SUPER_RES_TARGET_ : 440|1@0+ (1,0) [0|1] ""  CADM
 SG_ MRR_RR_CAN_DET_AZIMUTH_007 : 431|14@0+ (0.0003834,-3.1416) [-3.1416|3.1396422] "rad"  CADM
 SG_ MRR_RR_CAN_DET_CONFID_ELEVATION_ : 433|1@0+ (1,0) [0|1] ""  CADM
 SG_ MRR_RR_CAN_DET_HOST_VEH_CLUTTER_ : 432|1@0+ (1,0) [0|1] ""  CADM
 SG_ MRR_RR_CAN_DET_RANGE_007 : 415|14@0+ (0.015625,0) [0|255.984375] "m"  CADM
 SG_ MRR_RR_CAN_DET_CONFID_AZIMUTH_00 : 417|2@0+ (1,0) [0|3] ""  CADM
 SG_ MRR_RR_CAN_DET_RANGE_RATE_007 : 399|14@0+ (0.015625,-128) [-128|127.984375] "m/s"  CADM
 SG_ MRR_RR_CAN_SCAN_INDEX_2LSB_007 : 401|2@0+ (1,0) [0|3] ""  CADM
 SG_ MRR_RR_CAN_DET_AMPLITUDE_007 : 391|7@0+ (1,-64) [-64|63] "dBsm"  CADM
 SG_ MRR_RR_CAN_DET_VALID_LEVEL_007 : 384|1@0+ (1,0) [0|1] ""  CADM
 SG_ MRR_RR_CAN_DET_ELEVATION_006 : 383|7@0+ (0.002748,-0.1745) [-0.1745|0.174496] "rad"  CADM
 SG_ MRR_RR_CAN_DET_SUPER_RES_TA_0000 : 376|1@0+ (1,0) [0|1] ""  CADM
 SG_ MRR_RR_CAN_DET_AZIMUTH_006 : 367|14@0+ (0.0003834,-3.1416) [-3.1416|3.1396422] "rad"  CADM
 SG_ MRR_RR_CAN_DET_CONFID_ELEVA_0000 : 369|1@0+ (1,0) [0|1] ""  CADM
 SG_ MRR_RR_CAN_DET_HOST_VEH_CLU_0000 : 368|1@0+ (1,0) [0|1] ""  CADM
 SG_ MRR_RR_CAN_DET_RANGE_006 : 351|14@0+ (0.015625,0) [0|255.984375] "m"  CADM
 SG_ MRR_RR_CAN_DET_CONFID_AZIMU_0000 : 353|2@0+ (1,0) [0|3] ""  CADM
 SG_ MRR_RR_CAN_DET_RANGE_RATE_006 : 335|14@0+ (0.015625,-128) [-128|127.984375] "m/s"  CADM
 SG_ MRR_RR_CAN_SCAN_INDEX_2LSB_006 : 337|2@0+ (1,0) [0|3] ""  CADM
 SG_ MRR_RR_CAN_DET_AMPLITUDE_006 : 327|7@0+ (1,-64) [-64|63] "dBsm"  CADM
 SG_ MRR_RR_CAN_DET_VALID_LEVEL_006 : 320|1@0+ (1,0) [0|1] ""  CADM
 SG_ MRR_RR_CAN_DET_ELEVATION_005 : 319|7@0+ (0.002748,-0.1745) [-0.1745|0.174496] "rad"  CADM
 SG_ MRR_RR_CAN_DET_SUPER_RES_TA_0001 : 312|1@0+ (1,0) [0|1] ""  CADM
 SG_ MRR_RR_CAN_DET_AZIMUTH_005 : 303|14@0+ (0.0003834,-3.1416) [-3.1416|3.1396422] "rad"  CADM
 SG_ MRR_RR_CAN_DET_CONFID_ELEVA_0001 : 305|1@0+ (1,0) [0|1] ""  CADM
 SG_ MRR_RR_CAN_DET_HOST_VEH_CLU_0001 : 304|1@0+ (1,0) [0|1] ""  CADM
 SG_ MRR_RR_CAN_DET_RANGE_005 : 287|14@0+ (0.015625,0) [0|255.984375] "m"  CADM
 SG_ MRR_RR_CAN_DET_CONFID_AZIMU_0001 : 289|2@0+ (1,0) [0|3] ""  CADM
 SG_ MRR_RR_CAN_DET_RANGE_RATE_005 : 271|14@0+ (0.015625,-128) [-128|127.984375] "m/s"  CADM
 SG_ MRR_RR_CAN_SCAN_INDEX_2LSB_005 : 273|2@0+ (1,0) [0|3] ""  CADM
 SG_ MRR_RR_CAN_DET_AMPLITUDE_005 : 263|7@0+ (1,-64) [-64|63] "dBsm"  CADM
 SG_ MRR_RR_CAN_DET_VALID_LEVEL_005 : 256|1@0+ (1,0) [0|1] ""  CADM
 SG_ MRR_RR_CAN_DET_ELEVATION_004 : 255|7@0+ (0.002748,-0.1745) [-0.1745|0.174496] "rad"  CADM
 SG_ MRR_RR_CAN_DET_SUPER_RES_TA_0002 : 248|1@0+ (1,0) [0|1] ""  CADM
 SG_ MRR_RR_CAN_DET_AZIMUTH_004 : 239|14@0+ (0.0003834,-3.1416) [-3.1416|3.1396422] "rad"  CADM
 SG_ MRR_RR_CAN_DET_CONFID_ELEVA_0002 : 241|1@0+ (1,0) [0|1] ""  CADM
 SG_ MRR_RR_CAN_DET_HOST_VEH_CLU_0002 : 240|1@0+ (1,0) [0|1] ""  CADM
 SG_ MRR_RR_CAN_DET_RANGE_004 : 223|14@0+ (0.015625,0) [0|255.984375] "m"  CADM
 SG_ MRR_RR_CAN_DET_CONFID_AZIMU_0002 : 225|2@0+ (1,0) [0|3] ""  CADM
 SG_ MRR_RR_CAN_DET_RANGE_RATE_004 : 207|14@0+ (0.015625,-128) [-128|127.984375] "m/s"  CADM
 SG_ MRR_RR_CAN_SCAN_INDEX_2LSB_004 : 209|2@0+ (1,0) [0|3] ""  CADM
 SG_ MRR_RR_CAN_DET_AMPLITUDE_004 : 199|7@0+ (1,-64) [-64|63] "dBsm"  CADM
 SG_ MRR_RR_CAN_DET_VALID_LEVEL_004 : 192|1@0+ (1,0) [0|1] ""  CADM
 SG_ MRR_RR_CAN_DET_ELEVATION_003 : 191|7@0+ (0.002748,-0.1745) [-0.1745|0.174496] "rad"  CADM
 SG_ MRR_RR_CAN_DET_SUPER_RES_TA_0003 : 184|1@0+ (1,0) [0|1] ""  CADM
 SG_ MRR_RR_CAN_DET_AZIMUTH_003 : 175|14@0+ (0.0003834,-3.1416) [-3.1416|3.1396422] "rad"  CADM
 SG_ MRR_RR_CAN_DET_CONFID_ELEVA_0003 : 177|1@0+ (1,0) [0|1] ""  CADM
 SG_ MRR_RR_CAN_DET_HOST_VEH_CLU_0003 : 176|1@0+ (1,0) [0|1] ""  CADM
 SG_ MRR_RR_CAN_DET_RANGE_003 : 159|14@0+ (0.015625,0) [0|255.984375] "m"  CADM
 SG_ MRR_RR_CAN_DET_CONFID_AZIMU_0003 : 161|2@0+ (1,0) [0|3] ""  CADM
 SG_ MRR_RR_CAN_DET_RANGE_RATE_003 : 143|14@0+ (0.015625,-128) [-128|127.984375] "m/s"  CADM
 SG_ MRR_RR_CAN_SCAN_INDEX_2LSB_003 : 145|2@0+ (1,0) [0|3] ""  CADM
 SG_ MRR_RR_CAN_DET_AMPLITUDE_003 : 135|7@0+ (1,-64) [-64|63] "dBsm"  CADM
 SG_ MRR_RR_CAN_DET_VALID_LEVEL_003 : 128|1@0+ (1,0) [0|1] ""  CADM
 SG_ MRR_RR_CAN_DET_ELEVATION_002 : 127|7@0+ (0.002748,-0.1745) [-0.1745|0.174496] "rad"  CADM
 SG_ MRR_RR_CAN_DET_SUPER_RES_TA_0004 : 120|1@0+ (1,0) [0|1] ""  CADM
 SG_ MRR_RR_CAN_DET_AZIMUTH_002 : 111|14@0+ (0.0003834,-3.1416) [-3.1416|3.1396422] "rad"  CADM
 SG_ MRR_RR_CAN_DET_CONFID_ELEVA_0004 : 113|1@0+ (1,0) [0|1] ""  CADM
 SG_ MRR_RR_CAN_DET_HOST_VEH_CLU_0004 : 112|1@0+ (1,0) [0|1] ""  CADM
 SG_ MRR_RR_CAN_DET_RANGE_002 : 95|14@0+ (0.015625,0) [0|255.984375] "m"  CADM
 SG_ MRR_RR_CAN_DET_CONFID_AZIMU_0004 : 97|2@0+ (1,0) [0|3] ""  CADM
 SG_ MRR_RR_CAN_DET_RANGE_RATE_002 : 79|14@0+ (0.015625,-128) [-128|127.984375] "m/s"  CADM
 SG_ MRR_RR_CAN_SCAN_INDEX_2LSB_002 : 81|2@0+ (1,0) [0|3] ""  CADM
 SG_ MRR_RR_CAN_DET_AMPLITUDE_002 : 71|7@0+ (1,-64) [-64|63] "dBsm"  CADM
 SG_ MRR_RR_CAN_DET_VALID_LEVEL_002 : 64|1@0+ (1,0) [0|1] ""  CADM
 SG_ MRR_RR_CAN_DET_ELEVATION_001 : 63|7@0+ (0.002748,-0.1745) [-0.1745|0.174496] "rad"  CADM
 SG_ MRR_RR_CAN_DET_CONFID_AZIMU_0005 : 33|2@0+ (1,0) [0|3] ""  CADM
 SG_ MRR_RR_CAN_DET_SUPER_RES_TA_0005 : 56|1@0+ (1,0) [0|1] ""  CADM
 SG_ MRR_RR_CAN_DET_CONFID_ELEVA_0005 : 49|1@0+ (1,0) [0|1] ""  CADM
 SG_ MRR_RR_CAN_DET_HOST_VEH_CLU_0005 : 48|1@0+ (1,0) [0|1] ""  CADM
 SG_ MRR_RR_CAN_DET_VALID_LEVEL_001 : 0|1@0+ (1,0) [0|1] ""  CADM
 SG_ MRR_RR_CAN_DET_AZIMUTH_001 : 47|14@0+ (0.0003834,-3.1416) [-3.1416|3.1396422] "rad"  CADM
 SG_ MRR_RR_CAN_DET_RANGE_001 : 31|14@0+ (0.015625,0) [0|255.984375] "m"  CADM
 SG_ MRR_RR_CAN_DET_RANGE_RATE_001 : 15|14@0+ (0.015625,-128) [-128|127.984375] "m/s"  CADM
 SG_ MRR_RR_CAN_DET_AMPLITUDE_001 : 7|7@0+ (1,-64) [-64|63] "dBsm"  CADM
 SG_ MRR_RR_CAN_SCAN_INDEX_2LSB_001 : 17|2@0+ (1,0) [0|3] ""  CADM

BO_ 1537 MRR_RR_Detection_008_014: 64 MRRRR
 SG_ MRR_RR_CAN_DET_MID_TARGET_014 : 462|1@0+ (1,0) [0|1] ""  CADM
 SG_ MRR_RR_CAN_DET_MID_TARGET_013 : 461|1@0+ (1,0) [0|1] ""  CADM
 SG_ MRR_RR_CAN_DET_MID_TARGET_012 : 460|1@0+ (1,0) [0|1] ""  CADM
 SG_ MRR_RR_CAN_DET_MID_TARGET_011 : 459|1@0+ (1,0) [0|1] ""  CADM
 SG_ MRR_RR_CAN_DET_MID_TARGET_010 : 458|1@0+ (1,0) [0|1] ""  CADM
 SG_ MRR_RR_CAN_DET_MID_TARGET_009 : 457|1@0+ (1,0) [0|1] ""  CADM
 SG_ MRR_RR_CAN_DET_MID_TARGET_008 : 456|1@0+ (1,0) [0|1] ""  CADM
 SG_ MRR_RR_CAN_DET_Near_TARGET_008 : 448|1@0+ (1,0) [0|1] ""  CADM
 SG_ MRR_RR_CAN_DET_Near_TARGET_009 : 449|1@0+ (1,0) [0|1] ""  CADM
 SG_ MRR_RR_CAN_DET_Near_TARGET_010 : 450|1@0+ (1,0) [0|1] ""  CADM
 SG_ MRR_RR_CAN_DET_Near_TARGET_011 : 451|1@0+ (1,0) [0|1] ""  CADM
 SG_ MRR_RR_CAN_DET_Near_TARGET_012 : 452|1@0+ (1,0) [0|1] ""  CADM
 SG_ MRR_RR_CAN_DET_Near_TARGET_013 : 453|1@0+ (1,0) [0|1] ""  CADM
 SG_ MRR_RR_CAN_DET_Near_TARGET_014 : 454|1@0+ (1,0) [0|1] ""  CADM
 SG_ MRR_RR_CAN_DET_ELEVATION_008 : 63|7@0+ (0.002748,-0.1745) [-0.1745|0.174496] "rad"  CADM
 SG_ MRR_RR_CAN_DET_CONFID_AZIMU_0006 : 33|2@0+ (1,0) [0|3] ""  CADM
 SG_ MRR_RR_CAN_DET_SUPER_RES_TA_0006 : 56|1@0+ (1,0) [0|1] ""  CADM
 SG_ MRR_RR_CAN_DET_CONFID_ELEVA_0006 : 49|1@0+ (1,0) [0|1] ""  CADM
 SG_ MRR_RR_CAN_DET_HOST_VEH_CLU_0006 : 48|1@0+ (1,0) [0|1] ""  CADM
 SG_ MRR_RR_CAN_DET_VALID_LEVEL_008 : 0|1@0+ (1,0) [0|1] ""  CADM
 SG_ MRR_RR_CAN_DET_AZIMUTH_008 : 47|14@0+ (0.0003834,-3.1416) [-3.1416|3.1396422] "rad"  CADM
 SG_ MRR_RR_CAN_DET_RANGE_008 : 31|14@0+ (0.015625,0) [0|255.984375] "m"  CADM
 SG_ MRR_RR_CAN_DET_RANGE_RATE_008 : 15|14@0+ (0.015625,-128) [-128|127.984375] "m/s"  CADM
 SG_ MRR_RR_CAN_DET_AMPLITUDE_008 : 7|7@0+ (1,-64) [-64|63] "dBsm"  CADM
 SG_ MRR_RR_CAN_SCAN_INDEX_2LSB_008 : 17|2@0+ (1,0) [0|3] ""  CADM
 SG_ MRR_RR_DET_MC_002 : 491|4@0+ (1,0) [0|15] ""  CADM
 SG_ MRR_RR_DET_CRC_002 : 503|16@0+ (1,0) [0|65535] ""  CADM
 SG_ MRR_RR_CAN_DET_ELEVATION_014 : 447|7@0+ (0.002748,-0.1745) [-0.1745|0.174496] "rad"  CADM
 SG_ MRR_RR_CAN_DET_SUPER_RES_TA_0007 : 440|1@0+ (1,0) [0|1] ""  CADM
 SG_ MRR_RR_CAN_DET_AZIMUTH_014 : 431|14@0+ (0.0003834,-3.1416) [-3.1416|3.1396422] "rad"  CADM
 SG_ MRR_RR_CAN_DET_CONFID_ELEVA_0007 : 433|1@0+ (1,0) [0|1] ""  CADM
 SG_ MRR_RR_CAN_DET_HOST_VEH_CLU_0007 : 432|1@0+ (1,0) [0|1] ""  CADM
 SG_ MRR_RR_CAN_DET_RANGE_014 : 415|14@0+ (0.015625,0) [0|255.984375] "m"  CADM
 SG_ MRR_RR_CAN_DET_CONFID_AZIMUTH_01 : 417|2@0+ (1,0) [0|3] ""  CADM
 SG_ MRR_RR_CAN_DET_RANGE_RATE_014 : 399|14@0+ (0.015625,-128) [-128|127.984375] "m/s"  CADM
 SG_ MRR_RR_CAN_SCAN_INDEX_2LSB_014 : 401|2@0+ (1,0) [0|3] ""  CADM
 SG_ MRR_RR_CAN_DET_AMPLITUDE_014 : 391|7@0+ (1,-64) [-64|63] "dBsm"  CADM
 SG_ MRR_RR_CAN_DET_VALID_LEVEL_014 : 384|1@0+ (1,0) [0|1] ""  CADM
 SG_ MRR_RR_CAN_DET_ELEVATION_013 : 383|7@0+ (0.002748,-0.1745) [-0.1745|0.174496] "rad"  CADM
 SG_ MRR_RR_CAN_DET_SUPER_RES_TA_0008 : 376|1@0+ (1,0) [0|1] ""  CADM
 SG_ MRR_RR_CAN_DET_AZIMUTH_013 : 367|14@0+ (0.0003834,-3.1416) [-3.1416|3.1396422] "rad"  CADM
 SG_ MRR_RR_CAN_DET_CONFID_ELEVA_0008 : 369|1@0+ (1,0) [0|1] ""  CADM
 SG_ MRR_RR_CAN_DET_HOST_VEH_CLU_0008 : 368|1@0+ (1,0) [0|1] ""  CADM
 SG_ MRR_RR_CAN_DET_RANGE_013 : 351|14@0+ (0.015625,0) [0|255.984375] "m"  CADM
 SG_ MRR_RR_CAN_DET_CONFID_AZIMU_0007 : 353|2@0+ (1,0) [0|3] ""  CADM
 SG_ MRR_RR_CAN_DET_RANGE_RATE_013 : 335|14@0+ (0.015625,-128) [-128|127.984375] "m/s"  CADM
 SG_ MRR_RR_CAN_SCAN_INDEX_2LSB_013 : 337|2@0+ (1,0) [0|3] ""  CADM
 SG_ MRR_RR_CAN_DET_AMPLITUDE_013 : 327|7@0+ (1,-64) [-64|63] "dBsm"  CADM
 SG_ MRR_RR_CAN_DET_VALID_LEVEL_013 : 320|1@0+ (1,0) [0|1] ""  CADM
 SG_ MRR_RR_CAN_DET_ELEVATION_012 : 319|7@0+ (0.002748,-0.1745) [-0.1745|0.174496] "rad"  CADM
 SG_ MRR_RR_CAN_DET_SUPER_RES_TA_0009 : 312|1@0+ (1,0) [0|1] ""  CADM
 SG_ MRR_RR_CAN_DET_AZIMUTH_012 : 303|14@0+ (0.0003834,-3.1416) [-3.1416|3.1396422] "rad"  CADM
 SG_ MRR_RR_CAN_DET_CONFID_ELEVA_0009 : 305|1@0+ (1,0) [0|1] ""  CADM
 SG_ MRR_RR_CAN_DET_HOST_VEH_CLU_0009 : 304|1@0+ (1,0) [0|1] ""  CADM
 SG_ MRR_RR_CAN_DET_RANGE_012 : 287|14@0+ (0.015625,0) [0|255.984375] "m"  CADM
 SG_ MRR_RR_CAN_DET_CONFID_AZIMU_0008 : 289|2@0+ (1,0) [0|3] ""  CADM
 SG_ MRR_RR_CAN_DET_RANGE_RATE_012 : 271|14@0+ (0.015625,-128) [-128|127.984375] "m/s"  CADM
 SG_ MRR_RR_CAN_SCAN_INDEX_2LSB_012 : 273|2@0+ (1,0) [0|3] ""  CADM
 SG_ MRR_RR_CAN_DET_AMPLITUDE_012 : 263|7@0+ (1,-64) [-64|63] "dBsm"  CADM
 SG_ MRR_RR_CAN_DET_VALID_LEVEL_012 : 256|1@0+ (1,0) [0|1] ""  CADM
 SG_ MRR_RR_CAN_DET_ELEVATION_011 : 255|7@0+ (0.002748,-0.1745) [-0.1745|0.174496] "rad"  CADM
 SG_ MRR_RR_CAN_DET_SUPER_RES_TA_0010 : 248|1@0+ (1,0) [0|1] ""  CADM
 SG_ MRR_RR_CAN_DET_AZIMUTH_011 : 239|14@0+ (0.0003834,-3.1416) [-3.1416|3.1396422] "rad"  CADM
 SG_ MRR_RR_CAN_DET_CONFID_ELEVA_0010 : 241|1@0+ (1,0) [0|1] ""  CADM
 SG_ MRR_RR_CAN_DET_HOST_VEH_CLU_0010 : 240|1@0+ (1,0) [0|1] ""  CADM
 SG_ MRR_RR_CAN_DET_RANGE_011 : 223|14@0+ (0.015625,0) [0|255.984375] "m"  CADM
 SG_ MRR_RR_CAN_DET_CONFID_AZIMU_0009 : 225|2@0+ (1,0) [0|3] ""  CADM
 SG_ MRR_RR_CAN_DET_RANGE_RATE_011 : 207|14@0+ (0.015625,-128) [-128|127.984375] "m/s"  CADM
 SG_ MRR_RR_CAN_SCAN_INDEX_2LSB_011 : 209|2@0+ (1,0) [0|3] ""  CADM
 SG_ MRR_RR_CAN_DET_AMPLITUDE_011 : 199|7@0+ (1,-64) [-64|63] "dBsm"  CADM
 SG_ MRR_RR_CAN_DET_VALID_LEVEL_011 : 192|1@0+ (1,0) [0|1] ""  CADM
 SG_ MRR_RR_CAN_DET_ELEVATION_010 : 191|7@0+ (0.002748,-0.1745) [-0.1745|0.174496] "rad"  CADM
 SG_ MRR_RR_CAN_DET_SUPER_RES_TA_0011 : 184|1@0+ (1,0) [0|1] ""  CADM
 SG_ MRR_RR_CAN_DET_AZIMUTH_010 : 175|14@0+ (0.0003834,-3.1416) [-3.1416|3.1396422] "rad"  CADM
 SG_ MRR_RR_CAN_DET_CONFID_ELEVA_0011 : 177|1@0+ (1,0) [0|1] ""  CADM
 SG_ MRR_RR_CAN_DET_HOST_VEH_CLU_0011 : 176|1@0+ (1,0) [0|1] ""  CADM
 SG_ MRR_RR_CAN_DET_RANGE_010 : 159|14@0+ (0.015625,0) [0|255.984375] "m"  CADM
 SG_ MRR_RR_CAN_DET_CONFID_AZIMU_0010 : 161|2@0+ (1,0) [0|3] ""  CADM
 SG_ MRR_RR_CAN_DET_RANGE_RATE_010 : 143|14@0+ (0.015625,-128) [-128|127.984375] "m/s"  CADM
 SG_ MRR_RR_CAN_SCAN_INDEX_2LSB_010 : 145|2@0+ (1,0) [0|3] ""  CADM
 SG_ MRR_RR_CAN_DET_AMPLITUDE_010 : 135|7@0+ (1,-64) [-64|63] "dBsm"  CADM
 SG_ MRR_RR_CAN_DET_VALID_LEVEL_010 : 128|1@0+ (1,0) [0|1] ""  CADM
 SG_ MRR_RR_CAN_DET_ELEVATION_009 : 127|7@0+ (0.002748,-0.1745) [-0.1745|0.174496] "rad"  CADM
 SG_ MRR_RR_CAN_DET_SUPER_RES_TA_0012 : 120|1@0+ (1,0) [0|1] ""  CADM
 SG_ MRR_RR_CAN_DET_AZIMUTH_009 : 111|14@0+ (0.0003834,-3.1416) [-3.1416|3.1396422] "rad"  CADM
 SG_ MRR_RR_CAN_DET_CONFID_ELEVA_0012 : 113|1@0+ (1,0) [0|1] ""  CADM
 SG_ MRR_RR_CAN_DET_HOST_VEH_CLU_0012 : 112|1@0+ (1,0) [0|1] ""  CADM
 SG_ MRR_RR_CAN_DET_RANGE_009 : 95|14@0+ (0.015625,0) [0|255.984375] "m"  CADM
 SG_ MRR_RR_CAN_DET_CONFID_AZIMU_0011 : 97|2@0+ (1,0) [0|3] ""  CADM
 SG_ MRR_RR_CAN_DET_RANGE_RATE_009 : 79|14@0+ (0.015625,-128) [-128|127.984375] "m/s"  CADM
 SG_ MRR_RR_CAN_SCAN_INDEX_2LSB_009 : 81|2@0+ (1,0) [0|3] ""  CADM
 SG_ MRR_RR_CAN_DET_AMPLITUDE_009 : 71|7@0+ (1,-64) [-64|63] "dBsm"  CADM
 SG_ MRR_RR_CAN_DET_VALID_LEVEL_009 : 64|1@0+ (1,0) [0|1] ""  CADM

BO_ 1538 MRR_RR_Detection_015_021: 64 MRRRR
 SG_ MRR_RR_CAN_DET_MID_TARGET_021 : 462|1@0+ (1,0) [0|1] ""  CADM
 SG_ MRR_RR_CAN_DET_MID_TARGET_020 : 461|1@0+ (1,0) [0|1] ""  CADM
 SG_ MRR_RR_CAN_DET_MID_TARGET_019 : 460|1@0+ (1,0) [0|1] ""  CADM
 SG_ MRR_RR_CAN_DET_MID_TARGET_018 : 459|1@0+ (1,0) [0|1] ""  CADM
 SG_ MRR_RR_CAN_DET_MID_TARGET_017 : 458|1@0+ (1,0) [0|1] ""  CADM
 SG_ MRR_RR_CAN_DET_MID_TARGET_016 : 457|1@0+ (1,0) [0|1] ""  CADM
 SG_ MRR_RR_CAN_DET_MID_TARGET_015 : 456|1@0+ (1,0) [0|1] ""  CADM
 SG_ MRR_RR_CAN_DET_Near_TARGET_015 : 448|1@0+ (1,0) [0|1] ""  CADM
 SG_ MRR_RR_CAN_DET_Near_TARGET_016 : 449|1@0+ (1,0) [0|1] ""  CADM
 SG_ MRR_RR_CAN_DET_Near_TARGET_017 : 450|1@0+ (1,0) [0|1] ""  CADM
 SG_ MRR_RR_CAN_DET_Near_TARGET_018 : 451|1@0+ (1,0) [0|1] ""  CADM
 SG_ MRR_RR_CAN_DET_Near_TARGET_019 : 452|1@0+ (1,0) [0|1] ""  CADM
 SG_ MRR_RR_CAN_DET_Near_TARGET_020 : 453|1@0+ (1,0) [0|1] ""  CADM
 SG_ MRR_RR_CAN_DET_Near_TARGET_021 : 454|1@0+ (1,0) [0|1] ""  CADM
 SG_ MRR_RR_CAN_DET_ELEVATION_015 : 63|7@0+ (0.002748,-0.1745) [-0.1745|0.174496] "rad"  CADM
 SG_ MRR_RR_CAN_DET_CONFID_AZIMU_0012 : 33|2@0+ (1,0) [0|3] ""  CADM
 SG_ MRR_RR_CAN_DET_SUPER_RES_TA_0013 : 56|1@0+ (1,0) [0|1] ""  CADM
 SG_ MRR_RR_CAN_DET_CONFID_ELEVA_0013 : 49|1@0+ (1,0) [0|1] ""  CADM
 SG_ MRR_RR_CAN_DET_HOST_VEH_CLU_0013 : 48|1@0+ (1,0) [0|1] ""  CADM
 SG_ MRR_RR_CAN_DET_VALID_LEVEL_015 : 0|1@0+ (1,0) [0|1] ""  CADM
 SG_ MRR_RR_CAN_DET_AZIMUTH_015 : 47|14@0+ (0.0003834,-3.1416) [-3.1416|3.1396422] "rad"  CADM
 SG_ MRR_RR_CAN_DET_RANGE_015 : 31|14@0+ (0.015625,0) [0|255.984375] "m"  CADM
 SG_ MRR_RR_CAN_DET_RANGE_RATE_015 : 15|14@0+ (0.015625,-128) [-128|127.984375] "m/s"  CADM
 SG_ MRR_RR_CAN_DET_AMPLITUDE_015 : 7|7@0+ (1,-64) [-64|63] "dBsm"  CADM
 SG_ MRR_RR_CAN_SCAN_INDEX_2LSB_015 : 17|2@0+ (1,0) [0|3] ""  CADM
 SG_ MRR_RR_DET_MC_003 : 491|4@0+ (1,0) [0|15] ""  CADM
 SG_ MRR_RR_DET_CRC_003 : 503|16@0+ (1,0) [0|65535] ""  CADM
 SG_ MRR_RR_CAN_DET_ELEVATION_021 : 447|7@0+ (0.002748,-0.1745) [-0.1745|0.174496] "rad"  CADM
 SG_ MRR_RR_CAN_DET_SUPER_RES_TA_0014 : 440|1@0+ (1,0) [0|1] ""  CADM
 SG_ MRR_RR_CAN_DET_AZIMUTH_021 : 431|14@0+ (0.0003834,-3.1416) [-3.1416|3.1396422] "rad"  CADM
 SG_ MRR_RR_CAN_DET_CONFID_ELEVA_0014 : 433|1@0+ (1,0) [0|1] ""  CADM
 SG_ MRR_RR_CAN_DET_HOST_VEH_CLU_0014 : 432|1@0+ (1,0) [0|1] ""  CADM
 SG_ MRR_RR_CAN_DET_RANGE_021 : 415|14@0+ (0.015625,0) [0|255.984375] "m"  CADM
 SG_ MRR_RR_CAN_DET_CONFID_AZIMUTH_02 : 417|2@0+ (1,0) [0|3] ""  CADM
 SG_ MRR_RR_CAN_DET_RANGE_RATE_021 : 399|14@0+ (0.015625,-128) [-128|127.984375] "m/s"  CADM
 SG_ MRR_RR_CAN_SCAN_INDEX_2LSB_021 : 401|2@0+ (1,0) [0|3] ""  CADM
 SG_ MRR_RR_CAN_DET_AMPLITUDE_021 : 391|7@0+ (1,-64) [-64|63] "dBsm"  CADM
 SG_ MRR_RR_CAN_DET_VALID_LEVEL_021 : 384|1@0+ (1,0) [0|1] ""  CADM
 SG_ MRR_RR_CAN_DET_ELEVATION_020 : 383|7@0+ (0.002748,-0.1745) [-0.1745|0.174496] "rad"  CADM
 SG_ MRR_RR_CAN_DET_SUPER_RES_TA_0015 : 376|1@0+ (1,0) [0|1] ""  CADM
 SG_ MRR_RR_CAN_DET_AZIMUTH_020 : 367|14@0+ (0.0003834,-3.1416) [-3.1416|3.1396422] "rad"  CADM
 SG_ MRR_RR_CAN_DET_CONFID_ELEVA_0015 : 369|1@0+ (1,0) [0|1] ""  CADM
 SG_ MRR_RR_CAN_DET_HOST_VEH_CLU_0015 : 368|1@0+ (1,0) [0|1] ""  CADM
 SG_ MRR_RR_CAN_DET_RANGE_020 : 351|14@0+ (0.015625,0) [0|255.984375] "m"  CADM
 SG_ MRR_RR_CAN_DET_CONFID_AZIMU_0013 : 353|2@0+ (1,0) [0|3] ""  CADM
 SG_ MRR_RR_CAN_DET_RANGE_RATE_020 : 335|14@0+ (0.015625,-128) [-128|127.984375] "m/s"  CADM
 SG_ MRR_RR_CAN_SCAN_INDEX_2LSB_020 : 337|2@0+ (1,0) [0|3] ""  CADM
 SG_ MRR_RR_CAN_DET_AMPLITUDE_020 : 327|7@0+ (1,-64) [-64|63] "dBsm"  CADM
 SG_ MRR_RR_CAN_DET_VALID_LEVEL_020 : 320|1@0+ (1,0) [0|1] ""  CADM
 SG_ MRR_RR_CAN_DET_ELEVATION_019 : 319|7@0+ (0.002748,-0.1745) [-0.1745|0.174496] "rad"  CADM
 SG_ MRR_RR_CAN_DET_SUPER_RES_TA_0016 : 312|1@0+ (1,0) [0|1] ""  CADM
 SG_ MRR_RR_CAN_DET_AZIMUTH_019 : 303|14@0+ (0.0003834,-3.1416) [-3.1416|3.1396422] "rad"  CADM
 SG_ MRR_RR_CAN_DET_CONFID_ELEVA_0016 : 305|1@0+ (1,0) [0|1] ""  CADM
 SG_ MRR_RR_CAN_DET_HOST_VEH_CLU_0016 : 304|1@0+ (1,0) [0|1] ""  CADM
 SG_ MRR_RR_CAN_DET_RANGE_019 : 287|14@0+ (0.015625,0) [0|255.984375] "m"  CADM
 SG_ MRR_RR_CAN_DET_CONFID_AZIMU_0014 : 289|2@0+ (1,0) [0|3] ""  CADM
 SG_ MRR_RR_CAN_DET_RANGE_RATE_019 : 271|14@0+ (0.015625,-128) [-128|127.984375] "m/s"  CADM
 SG_ MRR_RR_CAN_SCAN_INDEX_2LSB_019 : 273|2@0+ (1,0) [0|3] ""  CADM
 SG_ MRR_RR_CAN_DET_AMPLITUDE_019 : 263|7@0+ (1,-64) [-64|63] "dBsm"  CADM
 SG_ MRR_RR_CAN_DET_VALID_LEVEL_019 : 256|1@0+ (1,0) [0|1] ""  CADM
 SG_ MRR_RR_CAN_DET_ELEVATION_018 : 255|7@0+ (0.002748,-0.1745) [-0.1745|0.174496] "rad"  CADM
 SG_ MRR_RR_CAN_DET_SUPER_RES_TA_0017 : 248|1@0+ (1,0) [0|1] ""  CADM
 SG_ MRR_RR_CAN_DET_AZIMUTH_018 : 239|14@0+ (0.0003834,-3.1416) [-3.1416|3.1396422] "rad"  CADM
 SG_ MRR_RR_CAN_DET_CONFID_ELEVA_0017 : 241|1@0+ (1,0) [0|1] ""  CADM
 SG_ MRR_RR_CAN_DET_HOST_VEH_CLU_0017 : 240|1@0+ (1,0) [0|1] ""  CADM
 SG_ MRR_RR_CAN_DET_RANGE_018 : 223|14@0+ (0.015625,0) [0|255.984375] "m"  CADM
 SG_ MRR_RR_CAN_DET_CONFID_AZIMU_0015 : 225|2@0+ (1,0) [0|3] ""  CADM
 SG_ MRR_RR_CAN_DET_RANGE_RATE_018 : 207|14@0+ (0.015625,-128) [-128|127.984375] "m/s"  CADM
 SG_ MRR_RR_CAN_SCAN_INDEX_2LSB_018 : 209|2@0+ (1,0) [0|3] ""  CADM
 SG_ MRR_RR_CAN_DET_AMPLITUDE_018 : 199|7@0+ (1,-64) [-64|63] "dBsm"  CADM
 SG_ MRR_RR_CAN_DET_VALID_LEVEL_018 : 192|1@0+ (1,0) [0|1] ""  CADM
 SG_ MRR_RR_CAN_DET_ELEVATION_017 : 191|7@0+ (0.002748,-0.1745) [-0.1745|0.174496] "rad"  CADM
 SG_ MRR_RR_CAN_DET_SUPER_RES_TA_0018 : 184|1@0+ (1,0) [0|1] ""  CADM
 SG_ MRR_RR_CAN_DET_AZIMUTH_017 : 175|14@0+ (0.0003834,-3.1416) [-3.1416|3.1396422] "rad"  CADM
 SG_ MRR_RR_CAN_DET_CONFID_ELEVA_0018 : 177|1@0+ (1,0) [0|1] ""  CADM
 SG_ MRR_RR_CAN_DET_HOST_VEH_CLU_0018 : 176|1@0+ (1,0) [0|1] ""  CADM
 SG_ MRR_RR_CAN_DET_RANGE_017 : 159|14@0+ (0.015625,0) [0|255.984375] "m"  CADM
 SG_ MRR_RR_CAN_DET_CONFID_AZIMU_0016 : 161|2@0+ (1,0) [0|3] ""  CADM
 SG_ MRR_RR_CAN_DET_RANGE_RATE_017 : 143|14@0+ (0.015625,-128) [-128|127.984375] "m/s"  CADM
 SG_ MRR_RR_CAN_SCAN_INDEX_2LSB_017 : 145|2@0+ (1,0) [0|3] ""  CADM
 SG_ MRR_RR_CAN_DET_AMPLITUDE_017 : 135|7@0+ (1,-64) [-64|63] "dBsm"  CADM
 SG_ MRR_RR_CAN_DET_VALID_LEVEL_017 : 128|1@0+ (1,0) [0|1] ""  CADM
 SG_ MRR_RR_CAN_DET_ELEVATION_016 : 127|7@0+ (0.002748,-0.1745) [-0.1745|0.174496] "rad"  CADM
 SG_ MRR_RR_CAN_DET_SUPER_RES_TA_0019 : 120|1@0+ (1,0) [0|1] ""  CADM
 SG_ MRR_RR_CAN_DET_AZIMUTH_016 : 111|14@0+ (0.0003834,-3.1416) [-3.1416|3.1396422] "rad"  CADM
 SG_ MRR_RR_CAN_DET_CONFID_ELEVA_0019 : 113|1@0+ (1,0) [0|1] ""  CADM
 SG_ MRR_RR_CAN_DET_HOST_VEH_CLU_0019 : 112|1@0+ (1,0) [0|1] ""  CADM
 SG_ MRR_RR_CAN_DET_RANGE_016 : 95|14@0+ (0.015625,0) [0|255.984375] "m"  CADM
 SG_ MRR_RR_CAN_DET_CONFID_AZIMU_0017 : 97|2@0+ (1,0) [0|3] ""  CADM
 SG_ MRR_RR_CAN_DET_RANGE_RATE_016 : 79|14@0+ (0.015625,-128) [-128|127.984375] "m/s"  CADM
 SG_ MRR_RR_CAN_SCAN_INDEX_2LSB_016 : 81|2@0+ (1,0) [0|3] ""  CADM
 SG_ MRR_RR_CAN_DET_AMPLITUDE_016 : 71|7@0+ (1,-64) [-64|63] "dBsm"  CADM
 SG_ MRR_RR_CAN_DET_VALID_LEVEL_016 : 64|1@0+ (1,0) [0|1] ""  CADM

BA_DEF_ SG_  "NWM_WakeupAllowed" ENUM  "0 No","1 Yes";
BA_DEF_ BO_  "GenMsgTimeoutTime" INT 0 2500;
BA_DEF_ BO_  "WakeupMessage" ENUM  "0 No","1 Yes";
BA_DEF_ SG_  "SignalDescription" STRING ;
BA_DEF_ SG_  "GenSigTimeoutTime_ABS_ESC" INT 0 100000;
BA_DEF_ SG_  "UsedOnPgmDBC" ENUM  "No","Yes";
BA_DEF_ BO_  "VFrameFormat" ENUM  "StandardCAN","ExtendedCAN","reserved","reserved","reserved","reserved","reserved","reserved","reserved","reserved","reserved","reserved","reserved","reserved","StandardCAN_FD","ExtendedCAN_FD";
BA_DEF_ BO_  "DiagConnection" INT 0 65535;
BA_DEF_ BO_  "CanTpBs" INT 0 255;
BA_DEF_ BO_  "EventRateOfChange" INT 10 10000;
BA_DEF_ BO_  "DiagState" ENUM  "No","Yes";
BA_DEF_ BO_  "DiagRequest" ENUM  "No","Yes";
BA_DEF_ BO_  "DiagResponse" ENUM  "No","Yes";
BA_DEF_ SG_  "GenSigCycleTime" INT 0 0;
BA_DEF_ SG_  "GenSigMarked" STRING ;
BA_DEF_ SG_  "GenSigVtName" STRING ;
BA_DEF_ SG_  "GenSigVtEn" STRING ;
BA_DEF_ SG_  "GenSigCmt" STRING ;
BA_DEF_ SG_  "GenSigSendType" ENUM  "Cyclic","OnWrite","vector_leerstring","OnChange","vector_leerstring","IfActive","vector_leerstring","NoSigSendType";
BA_DEF_ SG_  "GenSigInactiveValue" INT 0 100000;
BA_DEF_ SG_  "GenSigMissingSourceValue" INT 0 1000000000;
BA_DEF_ SG_  "GenSigStartValue" INT 0 1000000000;
BA_DEF_ BO_  "GenMsgILSupport" ENUM  "No","Yes";
BA_DEF_ BO_  "GenMsgSendType" ENUM  "FixedPeriodic","Event","EnabledPeriodic","NotUsed","NotUsed","EventPeriodic","NotUsed","NotUsed","NoMsgSendType";
BA_DEF_ BO_  "GenMsgCycleTime" INT 0 100000;
BA_DEF_ BO_  "GenMsgDelayTime" INT 0 10000;
BA_DEF_ BO_  "GenMsgNrOfRepetition" INT 0 100;
BA_DEF_ BO_  "GenMsgStartDelayTime" INT 0 10000;
BA_DEF_ BO_  "NetworkInitialization" ENUM  "No","Yes";
BA_DEF_ SG_  "SystemSignalLongSymbol" STRING ;
BA_DEF_DEF_  "NWM_WakeupAllowed" "0 No";
BA_DEF_DEF_  "GenMsgTimeoutTime" 2500;
BA_DEF_DEF_  "WakeupMessage" "0 No";
BA_DEF_DEF_  "SignalDescription" "";
BA_DEF_DEF_  "GenSigTimeoutTime_ABS_ESC" 0;
BA_DEF_DEF_  "UsedOnPgmDBC" "Yes";
BA_DEF_DEF_  "VFrameFormat" "StandardCAN_FD";
BA_DEF_DEF_  "DiagConnection" 0;
BA_DEF_DEF_  "CanTpBs" 255;
BA_DEF_DEF_  "EventRateOfChange" 10000;
BA_DEF_DEF_  "DiagState" "No";
BA_DEF_DEF_  "DiagRequest" "No";
BA_DEF_DEF_  "DiagResponse" "No";
BA_DEF_DEF_  "GenSigCycleTime" 0;
BA_DEF_DEF_  "GenSigMarked" "";
BA_DEF_DEF_  "GenSigVtName" "";
BA_DEF_DEF_  "GenSigVtEn" "";
BA_DEF_DEF_  "GenSigCmt" "";
BA_DEF_DEF_  "GenSigSendType" "NoSigSendType";
BA_DEF_DEF_  "GenSigInactiveValue" 0;
BA_DEF_DEF_  "GenSigMissingSourceValue" 0;
BA_DEF_DEF_  "GenSigStartValue" 0;
BA_DEF_DEF_  "GenMsgILSupport" "Yes";
BA_DEF_DEF_  "GenMsgSendType" "NoMsgSendType";
BA_DEF_DEF_  "GenMsgCycleTime" 0;
BA_DEF_DEF_  "GenMsgDelayTime" 0;
BA_DEF_DEF_  "GenMsgNrOfRepetition" 0;
BA_DEF_DEF_  "GenMsgStartDelayTime" 0;
BA_DEF_DEF_  "NetworkInitialization" "No";
BA_DEF_DEF_  "SystemSignalLongSymbol" "";
BA_ "GenMsgTimeoutTime" BO_ 75 0;
BA_ "GenMsgDelayTime" BO_ 75 20;
BA_ "GenMsgSendType" BO_ 75 1;
BA_ "GenMsgTimeoutTime" BO_ 74 0;
BA_ "GenMsgDelayTime" BO_ 74 20;
BA_ "GenMsgSendType" BO_ 74 1;
BA_ "GenMsgTimeoutTime" BO_ 65 0;
BA_ "GenMsgSendType" BO_ 65 1;
BA_ "GenMsgTimeoutTime" BO_ 673 0;
BA_ "GenMsgSendType" BO_ 673 0;
BA_ "GenMsgCycleTime" BO_ 673 1000;
BA_ "NetworkInitialization" BO_ 673 1;
BA_ "GenMsgTimeoutTime" BO_ 267 0;
BA_ "GenMsgSendType" BO_ 267 1;
BA_ "GenMsgTimeoutTime" BO_ 256 0;
BA_ "GenMsgSendType" BO_ 256 1;
BA_ "GenMsgTimeoutTime" BO_ 260 0;
BA_ "GenMsgCycleTime" BO_ 260 20;
BA_ "GenMsgSendType" BO_ 260 0;
BA_ "GenMsgTimeoutTime" BO_ 259 0;
BA_ "GenMsgSendType" BO_ 259 0;
BA_ "GenMsgCycleTime" BO_ 259 50;
BA_ "GenMsgTimeoutTime" BO_ 257 0;
BA_ "GenMsgSendType" BO_ 257 0;
BA_ "GenMsgCycleTime" BO_ 257 1000;
BA_ "GenMsgTimeoutTime" BO_ 258 0;
BA_ "GenMsgSendType" BO_ 258 0;
BA_ "GenMsgCycleTime" BO_ 258 1000;
BA_ "GenMsgCycleTime" BO_ 261 20;
BA_ "GenMsgSendType" BO_ 261 0;
BA_ "GenMsgTimeoutTime" BO_ 261 0;
BA_ "GenMsgTimeoutTime" BO_ 264 0;
BA_ "GenMsgSendType" BO_ 264 1;
BA_ "GenMsgTimeoutTime" BO_ 269 0;
BA_ "GenMsgCycleTime" BO_ 269 100;
BA_ "GenMsgSendType" BO_ 269 0;
BA_ "GenMsgTimeoutTime" BO_ 1536 0;
BA_ "GenMsgSendType" BO_ 1536 1;
BA_ "GenMsgTimeoutTime" BO_ 1537 0;
BA_ "GenMsgSendType" BO_ 1537 1;
BA_ "GenMsgTimeoutTime" BO_ 1538 0;
BA_ "GenMsgSendType" BO_ 1538 1;
BA_ "GenSigSendType" SG_ 75 LRRF1_CAN_DET_Near_TARGET_14 1;
BA_ "SignalDescription" SG_ 75 LRRF1_CAN_DET_Near_TARGET_14 "Near_Target_Discrimination";
BA_ "SignalDescription" SG_ 75 LRRF1_CAN_DET_Near_TARGET_13 "Near_Target_Discrimination";
BA_ "SignalDescription" SG_ 75 LRRF1_CAN_DET_Near_TARGET_12 "Near_Target_Discrimination";
BA_ "SignalDescription" SG_ 75 LRRF1_CAN_DET_Near_TARGET_11 "Near_Target_Discrimination";
BA_ "SignalDescription" SG_ 75 LRRF1_CAN_DET_Near_TARGET_10 "Near_Target_Discrimination";
BA_ "SignalDescription" SG_ 75 LRRF1_CAN_DET_Near_TARGET_09 "Near_Target_Discrimination";
BA_ "SignalDescription" SG_ 75 LRRF1_CAN_DET_Near_TARGET_08 "Near_Target_Discrimination";
BA_ "GenSigStartValue" SG_ 75 LRRF1_CAN_DET_ELEVATION_08 63.8646288209607;
BA_ "SignalDescription" SG_ 75 LRRF1_CAN_DET_ELEVATION_08 "Detected object elevation position 08";
BA_ "GenSigVtEn" SG_ 75 LRRF1_CAN_DET_CONFID_AZIMUTH_08 "TRUE";
BA_ "SignalDescription" SG_ 75 LRRF1_CAN_DET_CONFID_AZIMUTH_08 "Signal to noise level 08";
BA_ "SignalDescription" SG_ 75 LRRF1_CAN_DET_SUPER_RES_TARGET_0 "Super resolution target 08";
BA_ "SystemSignalLongSymbol" SG_ 75 LRRF1_CAN_DET_SUPER_RES_TARGET_0 "LRRF1_CAN_DET_SUPER_RES_TARGET_08";
BA_ "SignalDescription" SG_ 75 LRRF1_CAN_DET_CONFID_ELEVATION_0 "Elevation Angle Confidence 08";
BA_ "SystemSignalLongSymbol" SG_ 75 LRRF1_CAN_DET_CONFID_ELEVATION_0 "LRRF1_CAN_DET_CONFID_ELEVATION_08";
BA_ "SignalDescription" SG_ 75 LRRF1_CAN_DET_HOST_VEH_CLUTTER_0 "Host vehicle clutter 08";
BA_ "SystemSignalLongSymbol" SG_ 75 LRRF1_CAN_DET_HOST_VEH_CLUTTER_0 "LRRF1_CAN_DET_HOST_VEH_CLUTTER_08";
BA_ "SignalDescription" SG_ 75 LRRF1_CAN_DET_VALID_LEVEL_08 "Detected object valid level 08";
BA_ "GenSigStartValue" SG_ 75 LRRF1_CAN_DET_AZIMUTH_08 8194.05320813772;
BA_ "SignalDescription" SG_ 75 LRRF1_CAN_DET_AZIMUTH_08 "Detected object azimuth position 08";
BA_ "SignalDescription" SG_ 75 LRRF1_CAN_DET_RANGE_08 "Detected object range 08";
BA_ "GenSigStartValue" SG_ 75 LRRF1_CAN_DET_RANGE_RATE_08 8192;
BA_ "SignalDescription" SG_ 75 LRRF1_CAN_DET_RANGE_RATE_08 "Detected object range rate 08";
BA_ "SignalDescription" SG_ 75 LRRF1_CAN_DET_AMPLITUDE_08 "Detected object amplitude 08";
BA_ "SignalDescription" SG_ 75 LRRF1_CAN_SCAN_INDEX_2LSB_08 "The two LSB of scan index 08";
BA_ "SignalDescription" SG_ 75 LRRF1_Det_CRC_02 "Cyclic Redundancy Check for Detection Message Number 2";
BA_ "SignalDescription" SG_ 75 LRRF1_Det_MC_02 "Message Count for Detection Message Number 2";
BA_ "SignalDescription" SG_ 75 LRRF1_CAN_SCAN_INDEX_2LSB_14 "The two LSB of scan index 14";
BA_ "SignalDescription" SG_ 75 LRRF1_CAN_SCAN_INDEX_2LSB_13 "The two LSB of scan index 13";
BA_ "SignalDescription" SG_ 75 LRRF1_CAN_SCAN_INDEX_2LSB_12 "The two LSB of scan index 12";
BA_ "SignalDescription" SG_ 75 LRRF1_CAN_SCAN_INDEX_2LSB_11 "The two LSB of scan index 11";
BA_ "SignalDescription" SG_ 75 LRRF1_CAN_SCAN_INDEX_2LSB_10 "The two LSB of scan index 10";
BA_ "SignalDescription" SG_ 75 LRRF1_CAN_SCAN_INDEX_2LSB_09 "The two LSB of scan index 09";
BA_ "GenSigStartValue" SG_ 75 LRRF1_CAN_DET_RANGE_RATE_14 8192;
BA_ "SignalDescription" SG_ 75 LRRF1_CAN_DET_RANGE_RATE_14 "Detected object range rate 14";
BA_ "GenSigStartValue" SG_ 75 LRRF1_CAN_DET_RANGE_RATE_13 8192;
BA_ "SignalDescription" SG_ 75 LRRF1_CAN_DET_RANGE_RATE_13 "Detected object range rate 13";
BA_ "GenSigStartValue" SG_ 75 LRRF1_CAN_DET_RANGE_RATE_12 8192;
BA_ "SignalDescription" SG_ 75 LRRF1_CAN_DET_RANGE_RATE_12 "Detected object range rate 12";
BA_ "GenSigStartValue" SG_ 75 LRRF1_CAN_DET_RANGE_RATE_11 8192;
BA_ "SignalDescription" SG_ 75 LRRF1_CAN_DET_RANGE_RATE_11 "Detected object range rate 11";
BA_ "GenSigStartValue" SG_ 75 LRRF1_CAN_DET_RANGE_RATE_10 8192;
BA_ "SignalDescription" SG_ 75 LRRF1_CAN_DET_RANGE_RATE_10 "Detected object range rate 10";
BA_ "GenSigStartValue" SG_ 75 LRRF1_CAN_DET_RANGE_RATE_09 8192;
BA_ "SignalDescription" SG_ 75 LRRF1_CAN_DET_RANGE_RATE_09 "Detected object range rate 09";
BA_ "SignalDescription" SG_ 75 LRRF1_CAN_DET_RANGE_14 "Detected object range 14";
BA_ "SignalDescription" SG_ 75 LRRF1_CAN_DET_RANGE_13 "Detected object range 13";
BA_ "SignalDescription" SG_ 75 LRRF1_CAN_DET_RANGE_12 "Detected object range 12";
BA_ "SignalDescription" SG_ 75 LRRF1_CAN_DET_RANGE_11 "Detected object range 11";
BA_ "SignalDescription" SG_ 75 LRRF1_CAN_DET_RANGE_10 "Detected object range 10";
BA_ "SignalDescription" SG_ 75 LRRF1_CAN_DET_RANGE_09 "Detected object range 09";
BA_ "SignalDescription" SG_ 75 LRRF1_CAN_DET_SUPER_RES_TAR_0105 "Super resolution target 14";
BA_ "SystemSignalLongSymbol" SG_ 75 LRRF1_CAN_DET_SUPER_RES_TAR_0105 "LRRF1_CAN_DET_SUPER_RES_TARGET_14";
BA_ "SignalDescription" SG_ 75 LRRF1_CAN_DET_SUPER_RES_TAR_0106 "Super resolution target 13";
BA_ "SystemSignalLongSymbol" SG_ 75 LRRF1_CAN_DET_SUPER_RES_TAR_0106 "LRRF1_CAN_DET_SUPER_RES_TARGET_13";
BA_ "SignalDescription" SG_ 75 LRRF1_CAN_DET_SUPER_RES_TAR_0107 "Super resolution target 12";
BA_ "SystemSignalLongSymbol" SG_ 75 LRRF1_CAN_DET_SUPER_RES_TAR_0107 "LRRF1_CAN_DET_SUPER_RES_TARGET_12";
BA_ "SignalDescription" SG_ 75 LRRF1_CAN_DET_SUPER_RES_TAR_0108 "Super resolution target 11";
BA_ "SystemSignalLongSymbol" SG_ 75 LRRF1_CAN_DET_SUPER_RES_TAR_0108 "LRRF1_CAN_DET_SUPER_RES_TARGET_11";
BA_ "SignalDescription" SG_ 75 LRRF1_CAN_DET_SUPER_RES_TAR_0109 "Super resolution target 10";
BA_ "SystemSignalLongSymbol" SG_ 75 LRRF1_CAN_DET_SUPER_RES_TAR_0109 "LRRF1_CAN_DET_SUPER_RES_TARGET_10";
BA_ "SignalDescription" SG_ 75 LRRF1_CAN_DET_SUPER_RES_TAR_0110 "Super resolution target 09";
BA_ "SystemSignalLongSymbol" SG_ 75 LRRF1_CAN_DET_SUPER_RES_TAR_0110 "LRRF1_CAN_DET_SUPER_RES_TARGET_09";
BA_ "SignalDescription" SG_ 75 LRRF1_CAN_DET_HOST_VEH_CLUT_0105 "Host vehicle clutter 14";
BA_ "SystemSignalLongSymbol" SG_ 75 LRRF1_CAN_DET_HOST_VEH_CLUT_0105 "LRRF1_CAN_DET_HOST_VEH_CLUTTER_14";
BA_ "SignalDescription" SG_ 75 LRRF1_CAN_DET_HOST_VEH_CLUT_0106 "Host vehicle clutter 13";
BA_ "SystemSignalLongSymbol" SG_ 75 LRRF1_CAN_DET_HOST_VEH_CLUT_0106 "LRRF1_CAN_DET_HOST_VEH_CLUTTER_13";
BA_ "SignalDescription" SG_ 75 LRRF1_CAN_DET_HOST_VEH_CLUT_0107 "Host vehicle clutter 12";
BA_ "SystemSignalLongSymbol" SG_ 75 LRRF1_CAN_DET_HOST_VEH_CLUT_0107 "LRRF1_CAN_DET_HOST_VEH_CLUTTER_12";
BA_ "SignalDescription" SG_ 75 LRRF1_CAN_DET_HOST_VEH_CLUT_0108 "Host vehicle clutter 11";
BA_ "SystemSignalLongSymbol" SG_ 75 LRRF1_CAN_DET_HOST_VEH_CLUT_0108 "LRRF1_CAN_DET_HOST_VEH_CLUTTER_11";
BA_ "SignalDescription" SG_ 75 LRRF1_CAN_DET_HOST_VEH_CLUT_0109 "Host vehicle clutter 10";
BA_ "SystemSignalLongSymbol" SG_ 75 LRRF1_CAN_DET_HOST_VEH_CLUT_0109 "LRRF1_CAN_DET_HOST_VEH_CLUTTER_10";
BA_ "SignalDescription" SG_ 75 LRRF1_CAN_DET_HOST_VEH_CLUT_0110 "Host vehicle clutter 09";
BA_ "SystemSignalLongSymbol" SG_ 75 LRRF1_CAN_DET_HOST_VEH_CLUT_0110 "LRRF1_CAN_DET_HOST_VEH_CLUTTER_09";
BA_ "GenSigStartValue" SG_ 75 LRRF1_CAN_DET_ELEVATION_14 63.8646288209607;
BA_ "SignalDescription" SG_ 75 LRRF1_CAN_DET_ELEVATION_14 "Detected object elevation position 14";
BA_ "GenSigStartValue" SG_ 75 LRRF1_CAN_DET_ELEVATION_13 63.8646288209607;
BA_ "SignalDescription" SG_ 75 LRRF1_CAN_DET_ELEVATION_13 "Detected object elevation position 13";
BA_ "GenSigStartValue" SG_ 75 LRRF1_CAN_DET_ELEVATION_12 63.8646288209607;
BA_ "SignalDescription" SG_ 75 LRRF1_CAN_DET_ELEVATION_12 "Detected object elevation position 12";
BA_ "GenSigStartValue" SG_ 75 LRRF1_CAN_DET_ELEVATION_11 63.8646288209607;
BA_ "SignalDescription" SG_ 75 LRRF1_CAN_DET_ELEVATION_11 "Detected object elevation position 11";
BA_ "GenSigStartValue" SG_ 75 LRRF1_CAN_DET_ELEVATION_10 63.8646288209607;
BA_ "SignalDescription" SG_ 75 LRRF1_CAN_DET_ELEVATION_10 "Detected object elevation position 10";
BA_ "GenSigStartValue" SG_ 75 LRRF1_CAN_DET_ELEVATION_09 63.8646288209607;
BA_ "SignalDescription" SG_ 75 LRRF1_CAN_DET_ELEVATION_09 "Detected object elevation position 09";
BA_ "SignalDescription" SG_ 75 LRRF1_CAN_DET_CONFID_ELEVAT_0105 "Elevation Angle Confidence 14";
BA_ "SystemSignalLongSymbol" SG_ 75 LRRF1_CAN_DET_CONFID_ELEVAT_0105 "LRRF1_CAN_DET_CONFID_ELEVATION_14";
BA_ "SignalDescription" SG_ 75 LRRF1_CAN_DET_CONFID_ELEVAT_0106 "Elevation Angle Confidence 13";
BA_ "SystemSignalLongSymbol" SG_ 75 LRRF1_CAN_DET_CONFID_ELEVAT_0106 "LRRF1_CAN_DET_CONFID_ELEVATION_13";
BA_ "SignalDescription" SG_ 75 LRRF1_CAN_DET_CONFID_ELEVAT_0107 "Elevation Angle Confidence 12";
BA_ "SystemSignalLongSymbol" SG_ 75 LRRF1_CAN_DET_CONFID_ELEVAT_0107 "LRRF1_CAN_DET_CONFID_ELEVATION_12";
BA_ "SignalDescription" SG_ 75 LRRF1_CAN_DET_CONFID_ELEVAT_0108 "Elevation Angle Confidence 11";
BA_ "SystemSignalLongSymbol" SG_ 75 LRRF1_CAN_DET_CONFID_ELEVAT_0108 "LRRF1_CAN_DET_CONFID_ELEVATION_11";
BA_ "SignalDescription" SG_ 75 LRRF1_CAN_DET_CONFID_ELEVAT_0109 "Elevation Angle Confidence 10";
BA_ "SystemSignalLongSymbol" SG_ 75 LRRF1_CAN_DET_CONFID_ELEVAT_0109 "LRRF1_CAN_DET_CONFID_ELEVATION_10";
BA_ "SignalDescription" SG_ 75 LRRF1_CAN_DET_CONFID_ELEVAT_0110 "Elevation Angle Confidence 09";
BA_ "SystemSignalLongSymbol" SG_ 75 LRRF1_CAN_DET_CONFID_ELEVAT_0110 "LRRF1_CAN_DET_CONFID_ELEVATION_09";
BA_ "GenSigVtEn" SG_ 75 LRRF1_CAN_DET_CONFID_AZIMUTH_14 "TRUE";
BA_ "SignalDescription" SG_ 75 LRRF1_CAN_DET_CONFID_AZIMUTH_14 "Signal to noise level 14";
BA_ "GenSigVtEn" SG_ 75 LRRF1_CAN_DET_CONFID_AZIMUTH_13 "TRUE";
BA_ "SignalDescription" SG_ 75 LRRF1_CAN_DET_CONFID_AZIMUTH_13 "Signal to noise level 13";
BA_ "GenSigVtEn" SG_ 75 LRRF1_CAN_DET_CONFID_AZIMUTH_12 "TRUE";
BA_ "SignalDescription" SG_ 75 LRRF1_CAN_DET_CONFID_AZIMUTH_12 "Signal to noise level 12";
BA_ "GenSigVtEn" SG_ 75 LRRF1_CAN_DET_CONFID_AZIMUTH_11 "TRUE";
BA_ "SignalDescription" SG_ 75 LRRF1_CAN_DET_CONFID_AZIMUTH_11 "Signal to noise level 11";
BA_ "GenSigVtEn" SG_ 75 LRRF1_CAN_DET_CONFID_AZIMUTH_10 "TRUE";
BA_ "SignalDescription" SG_ 75 LRRF1_CAN_DET_CONFID_AZIMUTH_10 "Signal to noise level 10";
BA_ "GenSigVtEn" SG_ 75 LRRF1_CAN_DET_CONFID_AZIMUTH_09 "TRUE";
BA_ "SignalDescription" SG_ 75 LRRF1_CAN_DET_CONFID_AZIMUTH_09 "Signal to noise level 09";
BA_ "GenSigStartValue" SG_ 75 LRRF1_CAN_DET_AZIMUTH_14 8194.05320813772;
BA_ "SignalDescription" SG_ 75 LRRF1_CAN_DET_AZIMUTH_14 "Detected object azimuth position 14";
BA_ "GenSigStartValue" SG_ 75 LRRF1_CAN_DET_AZIMUTH_13 8194.05320813772;
BA_ "SignalDescription" SG_ 75 LRRF1_CAN_DET_AZIMUTH_13 "Detected object azimuth position 13";
BA_ "GenSigStartValue" SG_ 75 LRRF1_CAN_DET_AZIMUTH_12 8194.05320813772;
BA_ "SignalDescription" SG_ 75 LRRF1_CAN_DET_AZIMUTH_12 "Detected object azimuth position 12";
BA_ "GenSigStartValue" SG_ 75 LRRF1_CAN_DET_AZIMUTH_11 8194.05320813772;
BA_ "SignalDescription" SG_ 75 LRRF1_CAN_DET_AZIMUTH_11 "Detected object azimuth position 11";
BA_ "GenSigStartValue" SG_ 75 LRRF1_CAN_DET_AZIMUTH_10 8194.05320813772;
BA_ "SignalDescription" SG_ 75 LRRF1_CAN_DET_AZIMUTH_10 "Detected object azimuth position 10";
BA_ "GenSigStartValue" SG_ 75 LRRF1_CAN_DET_AZIMUTH_09 8194.05320813772;
BA_ "SignalDescription" SG_ 75 LRRF1_CAN_DET_AZIMUTH_09 "Detected object azimuth position 09";
BA_ "SignalDescription" SG_ 75 LRRF1_CAN_DET_AMPLITUDE_14 "Detected object amplitude 14";
BA_ "SignalDescription" SG_ 75 LRRF1_CAN_DET_AMPLITUDE_13 "Detected object amplitude 13";
BA_ "SignalDescription" SG_ 75 LRRF1_CAN_DET_AMPLITUDE_12 "Detected object amplitude 12";
BA_ "SignalDescription" SG_ 75 LRRF1_CAN_DET_AMPLITUDE_11 "Detected object amplitude 11";
BA_ "SignalDescription" SG_ 75 LRRF1_CAN_DET_AMPLITUDE_10 "Detected object amplitude 10";
BA_ "SignalDescription" SG_ 75 LRRF1_CAN_DET_AMPLITUDE_09 "Detected object amplitude 09";
BA_ "SignalDescription" SG_ 75 LRRF1_CAN_DET_VALID_LEVEL_14 "Detected object valid level 14";
BA_ "SignalDescription" SG_ 75 LRRF1_CAN_DET_VALID_LEVEL_13 "Detected object valid level 13";
BA_ "SignalDescription" SG_ 75 LRRF1_CAN_DET_VALID_LEVEL_12 "Detected object valid level 12";
BA_ "SignalDescription" SG_ 75 LRRF1_CAN_DET_VALID_LEVEL_11 "Detected object valid level 11";
BA_ "SignalDescription" SG_ 75 LRRF1_CAN_DET_VALID_LEVEL_10 "Detected object valid level 10";
BA_ "SignalDescription" SG_ 75 LRRF1_CAN_DET_VALID_LEVEL_09 "Detected object valid level 09";
BA_ "SignalDescription" SG_ 74 LRRF1_CAN_DET_Near_TARGET_07 "Near_Target_Discrimination";
BA_ "GenSigSendType" SG_ 74 LRRF1_CAN_DET_Near_TARGET_07 1;
BA_ "SignalDescription" SG_ 74 LRRF1_CAN_DET_Near_TARGET_06 "Near_Target_Discrimination";
BA_ "SignalDescription" SG_ 74 LRRF1_CAN_DET_Near_TARGET_05 "Near_Target_Discrimination";
BA_ "SignalDescription" SG_ 74 LRRF1_CAN_DET_Near_TARGET_04 "Near_Target_Discrimination";
BA_ "SignalDescription" SG_ 74 LRRF1_CAN_DET_Near_TARGET_03 "Near_Target_Discrimination";
BA_ "SignalDescription" SG_ 74 LRRF1_CAN_DET_Near_TARGET_02 "Near_Target_Discrimination";
BA_ "SignalDescription" SG_ 74 LRRF1_CAN_DET_Near_TARGET_01 "Near_Target_Discrimination";
BA_ "GenSigStartValue" SG_ 74 LRRF1_CAN_DET_ELEVATION_01 63.8646288209607;
BA_ "SignalDescription" SG_ 74 LRRF1_CAN_DET_ELEVATION_01 "Detected object elevation position 01";
BA_ "GenSigVtEn" SG_ 74 LRRF1_CAN_DET_CONFID_AZIMUTH_01 "TRUE";
BA_ "SignalDescription" SG_ 74 LRRF1_CAN_DET_CONFID_AZIMUTH_01 "Signal to noise level 01";
BA_ "SignalDescription" SG_ 74 LRRF1_CAN_DET_SUPER_RES_TAR_0111 "Super resolution target 01";
BA_ "SystemSignalLongSymbol" SG_ 74 LRRF1_CAN_DET_SUPER_RES_TAR_0111 "LRRF1_CAN_DET_SUPER_RES_TARGET_01";
BA_ "SignalDescription" SG_ 74 LRRF1_CAN_DET_CONFID_ELEVAT_0111 "Elevation Angle Confidence 01";
BA_ "SystemSignalLongSymbol" SG_ 74 LRRF1_CAN_DET_CONFID_ELEVAT_0111 "LRRF1_CAN_DET_CONFID_ELEVATION_01";
BA_ "SignalDescription" SG_ 74 LRRF1_CAN_DET_HOST_VEH_CLUT_0111 "Host vehicle clutter 01";
BA_ "SystemSignalLongSymbol" SG_ 74 LRRF1_CAN_DET_HOST_VEH_CLUT_0111 "LRRF1_CAN_DET_HOST_VEH_CLUTTER_01";
BA_ "SignalDescription" SG_ 74 LRRF1_CAN_DET_VALID_LEVEL_01 "Detected object valid level 01";
BA_ "GenSigStartValue" SG_ 74 LRRF1_CAN_DET_AZIMUTH_01 8194.05320813772;
BA_ "SignalDescription" SG_ 74 LRRF1_CAN_DET_AZIMUTH_01 "Detected object azimuth position 01";
BA_ "SignalDescription" SG_ 74 LRRF1_CAN_DET_RANGE_01 "Detected object range 01";
BA_ "GenSigStartValue" SG_ 74 LRRF1_CAN_DET_RANGE_RATE_01 8192;
BA_ "SignalDescription" SG_ 74 LRRF1_CAN_DET_RANGE_RATE_01 "Detected object range rate 01";
BA_ "SignalDescription" SG_ 74 LRRF1_CAN_DET_AMPLITUDE_01 "Detected object amplitude 01";
BA_ "SignalDescription" SG_ 74 LRRF1_CAN_SCAN_INDEX_2LSB_01 "The two LSB of scan index 01";
BA_ "SignalDescription" SG_ 74 LRRF1_Det_CRC_01 "Cyclic Redundancy Check for Detection Message Number 1";
BA_ "SignalDescription" SG_ 74 LRRF1_Det_MC_01 "Message Count for Detection Message Number 1";
BA_ "SignalDescription" SG_ 74 LRRF1_CAN_SCAN_INDEX_2LSB_07 "The two LSB of scan index 07";
BA_ "SignalDescription" SG_ 74 LRRF1_CAN_SCAN_INDEX_2LSB_06 "The two LSB of scan index 06";
BA_ "SignalDescription" SG_ 74 LRRF1_CAN_SCAN_INDEX_2LSB_05 "The two LSB of scan index 05";
BA_ "SignalDescription" SG_ 74 LRRF1_CAN_SCAN_INDEX_2LSB_04 "The two LSB of scan index 04";
BA_ "SignalDescription" SG_ 74 LRRF1_CAN_SCAN_INDEX_2LSB_03 "The two LSB of scan index 03";
BA_ "SignalDescription" SG_ 74 LRRF1_CAN_SCAN_INDEX_2LSB_02 "The two LSB of scan index 02";
BA_ "GenSigStartValue" SG_ 74 LRRF1_CAN_DET_RANGE_RATE_07 8192;
BA_ "SignalDescription" SG_ 74 LRRF1_CAN_DET_RANGE_RATE_07 "Detected object range rate 07";
BA_ "GenSigStartValue" SG_ 74 LRRF1_CAN_DET_RANGE_RATE_06 8192;
BA_ "SignalDescription" SG_ 74 LRRF1_CAN_DET_RANGE_RATE_06 "Detected object range rate 06";
BA_ "GenSigStartValue" SG_ 74 LRRF1_CAN_DET_RANGE_RATE_05 8192;
BA_ "SignalDescription" SG_ 74 LRRF1_CAN_DET_RANGE_RATE_05 "Detected object range rate 05";
BA_ "GenSigStartValue" SG_ 74 LRRF1_CAN_DET_RANGE_RATE_04 8192;
BA_ "SignalDescription" SG_ 74 LRRF1_CAN_DET_RANGE_RATE_04 "Detected object range rate 04";
BA_ "GenSigStartValue" SG_ 74 LRRF1_CAN_DET_RANGE_RATE_03 8192;
BA_ "SignalDescription" SG_ 74 LRRF1_CAN_DET_RANGE_RATE_03 "Detected object range rate 03";
BA_ "GenSigStartValue" SG_ 74 LRRF1_CAN_DET_RANGE_RATE_02 8192;
BA_ "SignalDescription" SG_ 74 LRRF1_CAN_DET_RANGE_RATE_02 "Detected object range rate 02";
BA_ "SignalDescription" SG_ 74 LRRF1_CAN_DET_RANGE_07 "Detected object range 07";
BA_ "SignalDescription" SG_ 74 LRRF1_CAN_DET_RANGE_06 "Detected object range 06";
BA_ "SignalDescription" SG_ 74 LRRF1_CAN_DET_RANGE_05 "Detected object range 05";
BA_ "SignalDescription" SG_ 74 LRRF1_CAN_DET_RANGE_04 "Detected object range 04";
BA_ "SignalDescription" SG_ 74 LRRF1_CAN_DET_RANGE_03 "Detected object range 03";
BA_ "SignalDescription" SG_ 74 LRRF1_CAN_DET_RANGE_02 "Detected object range 02";
BA_ "SignalDescription" SG_ 74 LRRF1_CAN_DET_SUPER_RES_TAR_0112 "Super resolution target 07";
BA_ "SystemSignalLongSymbol" SG_ 74 LRRF1_CAN_DET_SUPER_RES_TAR_0112 "LRRF1_CAN_DET_SUPER_RES_TARGET_07";
BA_ "SignalDescription" SG_ 74 LRRF1_CAN_DET_SUPER_RES_TAR_0113 "Super resolution target 06";
BA_ "SystemSignalLongSymbol" SG_ 74 LRRF1_CAN_DET_SUPER_RES_TAR_0113 "LRRF1_CAN_DET_SUPER_RES_TARGET_06";
BA_ "SignalDescription" SG_ 74 LRRF1_CAN_DET_SUPER_RES_TAR_0114 "Super resolution target 05";
BA_ "SystemSignalLongSymbol" SG_ 74 LRRF1_CAN_DET_SUPER_RES_TAR_0114 "LRRF1_CAN_DET_SUPER_RES_TARGET_05";
BA_ "SignalDescription" SG_ 74 LRRF1_CAN_DET_SUPER_RES_TAR_0115 "Super resolution target 04";
BA_ "SystemSignalLongSymbol" SG_ 74 LRRF1_CAN_DET_SUPER_RES_TAR_0115 "LRRF1_CAN_DET_SUPER_RES_TARGET_04";
BA_ "SignalDescription" SG_ 74 LRRF1_CAN_DET_SUPER_RES_TAR_0116 "Super resolution target 03";
BA_ "SystemSignalLongSymbol" SG_ 74 LRRF1_CAN_DET_SUPER_RES_TAR_0116 "LRRF1_CAN_DET_SUPER_RES_TARGET_03";
BA_ "SignalDescription" SG_ 74 LRRF1_CAN_DET_SUPER_RES_TAR_0117 "Super resolution target 02";
BA_ "SystemSignalLongSymbol" SG_ 74 LRRF1_CAN_DET_SUPER_RES_TAR_0117 "LRRF1_CAN_DET_SUPER_RES_TARGET_02";
BA_ "SignalDescription" SG_ 74 LRRF1_CAN_DET_HOST_VEH_CLUT_0112 "Host vehicle clutter 07";
BA_ "SystemSignalLongSymbol" SG_ 74 LRRF1_CAN_DET_HOST_VEH_CLUT_0112 "LRRF1_CAN_DET_HOST_VEH_CLUTTER_07";
BA_ "SignalDescription" SG_ 74 LRRF1_CAN_DET_HOST_VEH_CLUT_0113 "Host vehicle clutter 06";
BA_ "SystemSignalLongSymbol" SG_ 74 LRRF1_CAN_DET_HOST_VEH_CLUT_0113 "LRRF1_CAN_DET_HOST_VEH_CLUTTER_06";
BA_ "SignalDescription" SG_ 74 LRRF1_CAN_DET_HOST_VEH_CLUT_0114 "Host vehicle clutter 05";
BA_ "SystemSignalLongSymbol" SG_ 74 LRRF1_CAN_DET_HOST_VEH_CLUT_0114 "LRRF1_CAN_DET_HOST_VEH_CLUTTER_05";
BA_ "SignalDescription" SG_ 74 LRRF1_CAN_DET_HOST_VEH_CLUT_0115 "Host vehicle clutter 04";
BA_ "SystemSignalLongSymbol" SG_ 74 LRRF1_CAN_DET_HOST_VEH_CLUT_0115 "LRRF1_CAN_DET_HOST_VEH_CLUTTER_04";
BA_ "SignalDescription" SG_ 74 LRRF1_CAN_DET_HOST_VEH_CLUT_0116 "Host vehicle clutter 03";
BA_ "SystemSignalLongSymbol" SG_ 74 LRRF1_CAN_DET_HOST_VEH_CLUT_0116 "LRRF1_CAN_DET_HOST_VEH_CLUTTER_03";
BA_ "SignalDescription" SG_ 74 LRRF1_CAN_DET_HOST_VEH_CLUT_0117 "Host vehicle clutter 02";
BA_ "SystemSignalLongSymbol" SG_ 74 LRRF1_CAN_DET_HOST_VEH_CLUT_0117 "LRRF1_CAN_DET_HOST_VEH_CLUTTER_02";
BA_ "GenSigStartValue" SG_ 74 LRRF1_CAN_DET_ELEVATION_07 63.8646288209607;
BA_ "SignalDescription" SG_ 74 LRRF1_CAN_DET_ELEVATION_07 "Detected object elevation position 07";
BA_ "SignalDescription" SG_ 74 LRRF1_CAN_DET_ELEVATION_06 "Detected object elevation position 06";
BA_ "GenSigStartValue" SG_ 74 LRRF1_CAN_DET_ELEVATION_06 63.8646288209607;
BA_ "SignalDescription" SG_ 74 LRRF1_CAN_DET_ELEVATION_05 "Detected object elevation position 05";
BA_ "GenSigStartValue" SG_ 74 LRRF1_CAN_DET_ELEVATION_05 63.8646288209607;
BA_ "GenSigStartValue" SG_ 74 LRRF1_CAN_DET_ELEVATION_04 63.8646288209607;
BA_ "SignalDescription" SG_ 74 LRRF1_CAN_DET_ELEVATION_04 "Detected object elevation position 04";
BA_ "SignalDescription" SG_ 74 LRRF1_CAN_DET_ELEVATION_03 "Detected object elevation position 03";
BA_ "GenSigStartValue" SG_ 74 LRRF1_CAN_DET_ELEVATION_03 63.8646288209607;
BA_ "SignalDescription" SG_ 74 LRRF1_CAN_DET_ELEVATION_02 "Detected object elevation position 02";
BA_ "GenSigStartValue" SG_ 74 LRRF1_CAN_DET_ELEVATION_02 63.8646288209607;
BA_ "SignalDescription" SG_ 74 LRRF1_CAN_DET_CONFID_ELEVAT_0112 "Elevation Angle Confidence 07";
BA_ "SystemSignalLongSymbol" SG_ 74 LRRF1_CAN_DET_CONFID_ELEVAT_0112 "LRRF1_CAN_DET_CONFID_ELEVATION_07";
BA_ "SignalDescription" SG_ 74 LRRF1_CAN_DET_CONFID_ELEVAT_0113 "Elevation Angle Confidence 06";
BA_ "SystemSignalLongSymbol" SG_ 74 LRRF1_CAN_DET_CONFID_ELEVAT_0113 "LRRF1_CAN_DET_CONFID_ELEVATION_06";
BA_ "SignalDescription" SG_ 74 LRRF1_CAN_DET_CONFID_ELEVAT_0114 "Elevation Angle Confidence 05";
BA_ "SystemSignalLongSymbol" SG_ 74 LRRF1_CAN_DET_CONFID_ELEVAT_0114 "LRRF1_CAN_DET_CONFID_ELEVATION_05";
BA_ "SignalDescription" SG_ 74 LRRF1_CAN_DET_CONFID_ELEVAT_0115 "Elevation Angle Confidence 04";
BA_ "SystemSignalLongSymbol" SG_ 74 LRRF1_CAN_DET_CONFID_ELEVAT_0115 "LRRF1_CAN_DET_CONFID_ELEVATION_04";
BA_ "SignalDescription" SG_ 74 LRRF1_CAN_DET_CONFID_ELEVAT_0116 "Elevation Angle Confidence 03";
BA_ "SystemSignalLongSymbol" SG_ 74 LRRF1_CAN_DET_CONFID_ELEVAT_0116 "LRRF1_CAN_DET_CONFID_ELEVATION_03";
BA_ "SignalDescription" SG_ 74 LRRF1_CAN_DET_CONFID_ELEVAT_0117 "Elevation Angle Confidence 02";
BA_ "SystemSignalLongSymbol" SG_ 74 LRRF1_CAN_DET_CONFID_ELEVAT_0117 "LRRF1_CAN_DET_CONFID_ELEVATION_02";
BA_ "GenSigVtEn" SG_ 74 LRRF1_CAN_DET_CONFID_AZIMUTH_07 "TRUE";
BA_ "SignalDescription" SG_ 74 LRRF1_CAN_DET_CONFID_AZIMUTH_07 "Signal to noise level 07";
BA_ "GenSigVtEn" SG_ 74 LRRF1_CAN_DET_CONFID_AZIMUTH_06 "TRUE";
BA_ "SignalDescription" SG_ 74 LRRF1_CAN_DET_CONFID_AZIMUTH_06 "Signal to noise level 06";
BA_ "GenSigVtEn" SG_ 74 LRRF1_CAN_DET_CONFID_AZIMUTH_05 "TRUE";
BA_ "SignalDescription" SG_ 74 LRRF1_CAN_DET_CONFID_AZIMUTH_05 "Signal to noise level 05";
BA_ "SignalDescription" SG_ 74 LRRF1_CAN_DET_CONFID_AZIMUTH_04 "Signal to noise level 04";
BA_ "GenSigVtEn" SG_ 74 LRRF1_CAN_DET_CONFID_AZIMUTH_03 "TRUE";
BA_ "SignalDescription" SG_ 74 LRRF1_CAN_DET_CONFID_AZIMUTH_03 "Signal to noise level 03";
BA_ "GenSigVtEn" SG_ 74 LRRF1_CAN_DET_CONFID_AZIMUTH_02 "TRUE";
BA_ "SignalDescription" SG_ 74 LRRF1_CAN_DET_CONFID_AZIMUTH_02 "Signal to noise level 02";
BA_ "GenSigStartValue" SG_ 74 LRRF1_CAN_DET_AZIMUTH_07 8194.05320813772;
BA_ "SignalDescription" SG_ 74 LRRF1_CAN_DET_AZIMUTH_07 "Detected object azimuth position 07";
BA_ "GenSigStartValue" SG_ 74 LRRF1_CAN_DET_AZIMUTH_06 8194.05320813772;
BA_ "SignalDescription" SG_ 74 LRRF1_CAN_DET_AZIMUTH_06 "Detected object azimuth position 06";
BA_ "GenSigStartValue" SG_ 74 LRRF1_CAN_DET_AZIMUTH_05 8194.05320813772;
BA_ "SignalDescription" SG_ 74 LRRF1_CAN_DET_AZIMUTH_05 "Detected object azimuth position 05";
BA_ "GenSigStartValue" SG_ 74 LRRF1_CAN_DET_AZIMUTH_04 8194.05320813772;
BA_ "SignalDescription" SG_ 74 LRRF1_CAN_DET_AZIMUTH_04 "Detected object azimuth position 04";
BA_ "GenSigStartValue" SG_ 74 LRRF1_CAN_DET_AZIMUTH_03 8194.05320813772;
BA_ "SignalDescription" SG_ 74 LRRF1_CAN_DET_AZIMUTH_03 "Detected object azimuth position 03";
BA_ "GenSigStartValue" SG_ 74 LRRF1_CAN_DET_AZIMUTH_02 8194.05320813772;
BA_ "SignalDescription" SG_ 74 LRRF1_CAN_DET_AZIMUTH_02 "Detected object azimuth position 02";
BA_ "SignalDescription" SG_ 74 LRRF1_CAN_DET_AMPLITUDE_07 "Detected object amplitude 07";
BA_ "SignalDescription" SG_ 74 LRRF1_CAN_DET_AMPLITUDE_06 "Detected object amplitude 06";
BA_ "SignalDescription" SG_ 74 LRRF1_CAN_DET_AMPLITUDE_05 "Detected object amplitude 05";
BA_ "SignalDescription" SG_ 74 LRRF1_CAN_DET_AMPLITUDE_04 "Detected object amplitude 04";
BA_ "SignalDescription" SG_ 74 LRRF1_CAN_DET_AMPLITUDE_03 "Detected object amplitude 03";
BA_ "SignalDescription" SG_ 74 LRRF1_CAN_DET_AMPLITUDE_02 "Detected object amplitude 02";
BA_ "SignalDescription" SG_ 74 LRRF1_CAN_DET_VALID_LEVEL_07 "Detected object valid level 07";
BA_ "SignalDescription" SG_ 74 LRRF1_CAN_DET_VALID_LEVEL_06 "Detected object valid level 06";
BA_ "SignalDescription" SG_ 74 LRRF1_CAN_DET_VALID_LEVEL_05 "Detected object valid level 05";
BA_ "SignalDescription" SG_ 74 LRRF1_CAN_DET_VALID_LEVEL_04 "Detected object valid level 04";
BA_ "SignalDescription" SG_ 74 LRRF1_CAN_DET_VALID_LEVEL_03 "Detected object valid level 03";
BA_ "SignalDescription" SG_ 74 LRRF1_CAN_DET_VALID_LEVEL_02 "Detected object valid level 02";
BA_ "GenSigSendType" SG_ 65 LRRF1_System_Operation_Mode_Stat 1;
BA_ "SystemSignalLongSymbol" SG_ 65 LRRF1_System_Operation_Mode_Stat "LRRF1_System_Operation_Mode_Status";
BA_ "SystemSignalLongSymbol" SG_ 65 LRRF1_CAN_RADAR_CommonModeFailur "LRRF1_CAN_RADAR_CommonModeFailure";
BA_ "SystemSignalLongSymbol" SG_ 65 LRRF1_CAN_BLKG_SIDELOBE_FILTER_V "LRRF1_CAN_BLKG_SIDELOBE_FILTER_VAL";
BA_ "GenSigStartValue" SG_ 65 RadarAlignment_FA_SER_Incomplete 1;
BA_ "GenSigVtEn" SG_ 65 RadarAlignment_FA_SER_Incomplete "TRUE";
BA_ "SignalDescription" SG_ 65 RadarAlignment_FA_SER_Incomplete "Indication that the alignment routine has not been completed";
BA_ "SystemSignalLongSymbol" SG_ 65 RadarAlignment_FA_SER_Incomplete "RadarAlignment_FA_SER_Incomplete_LRRF";
BA_ "GenSigVtEn" SG_ 65 RadarBlockageSidelobe_LRRF "TRUE";
BA_ "SignalDescription" SG_ 65 RadarBlockageSidelobe_LRRF "Blockage error indication";
BA_ "GenSigVtEn" SG_ 65 RadarExternalConditionsNotOK_LRR "TRUE";
BA_ "SignalDescription" SG_ 65 RadarExternalConditionsNotOK_LRR "Set to TRUE when the LRRF1 is not working properly because of too high temperature or insufficient power in the LRRF1";
BA_ "SystemSignalLongSymbol" SG_ 65 RadarExternalConditionsNotOK_LRR "RadarExternalConditionsNotOK_LRRF";
BA_ "GenSigVtEn" SG_ 65 RadarAlignment_FA_SER_OutOfRange "TRUE";
BA_ "SignalDescription" SG_ 65 RadarAlignment_FA_SER_OutOfRange "Set to TRUE when the radar sensor cannot be aligned without mechanical adjustment of the sensor";
BA_ "SystemSignalLongSymbol" SG_ 65 RadarAlignment_FA_SER_OutOfRange "RadarAlignment_FA_SER_OutOfRange_LRRF";
BA_ "GenSigStartValue" SG_ 65 RadarAlignment_FA_SER_NotStarted 1;
BA_ "GenSigVtEn" SG_ 65 RadarAlignment_FA_SER_NotStarted "TRUE";
BA_ "SignalDescription" SG_ 65 RadarAlignment_FA_SER_NotStarted "Set to TRUE as long as the radar sensor alignment has not started";
BA_ "SystemSignalLongSymbol" SG_ 65 RadarAlignment_FA_SER_NotStarted "RadarAlignment_FA_SER_NotStarted_LRRF";
BA_ "GenSigVtEn" SG_ 65 RadarSensorNotOperational_LRRF "TRUE";
BA_ "SignalDescription" SG_ 65 RadarSensorNotOperational_LRRF "Set to TRUE when the radar system is not operational";
BA_ "GenSigSendType" SG_ 673 MRR_f_Radar_Unreasonable 0;
BA_ "GenSigCycleTime" SG_ 673 MRR_f_Radar_Unreasonable 1000;
BA_ "GenSigCmt" SG_ 267 MRR_RR_CAN_VRTCL_ALIGN_UPDATES_N "Number of alignment updates done.";
BA_ "GenSigSendType" SG_ 267 MRR_RR_CAN_VRTCL_ALIGN_UPDATES_N 1;
BA_ "SystemSignalLongSymbol" SG_ 267 MRR_RR_CAN_VRTCL_ALIGN_UPDATES_N "MRR_RR_CAN_VRTCL_ALIGN_UPDATES_Nbr";
BA_ "GenSigCmt" SG_ 267 MRR_RR_CAN_HRZNTL_ALIGN_UPDATES_ "Number of alignment updates done.";
BA_ "SystemSignalLongSymbol" SG_ 267 MRR_RR_CAN_HRZNTL_ALIGN_UPDATES_ "MRR_RR_CAN_HRZNTL_ALIGN_UPDATES_Nbr";
BA_ "SystemSignalLongSymbol" SG_ 267 MRR_RR_Horizontal_Alignment_Stat "MRR_RR_Horizontal_Alignment_Status";
BA_ "GenSigSendType" SG_ 267 MRR_RR_Vertical_Alignment_State 1;
BA_ "SystemSignalLongSymbol" SG_ 267 MRR_RR_Horizontal_Alignment_0000 "MRR_RR_Horizontal_Alignment_State";
BA_ "GenSigStartValue" SG_ 267 MRR_RR_Align_Vertical_Ref 511.500000000001;
BA_ "GenSigStartValue" SG_ 267 MRR_RR_Align_Vertical_Angle 511.500000000001;
BA_ "GenSigStartValue" SG_ 267 MRR_RR_Align_Horizontal_Angle 511.5;
BA_ "GenSigStartValue" SG_ 267 MRR_RR_Align_Horizontal_Ref 511.5;
BA_ "SystemSignalLongSymbol" SG_ 256 MRR_RR_CAN_TX_VEH_SPEED_DIRECTIO "MRR_RR_CAN_TX_VEH_SPEED_DIRECTION";
BA_ "SystemSignalLongSymbol" SG_ 256 MRR_RR_CAN_TX_STEERING_ANGLE_SIG "MRR_RR_CAN_TX_STEERING_ANGLE_SIGN";
BA_ "GenSigSendType" SG_ 256 MRR_RR_CAN_TX_STEERING_ANGLE 1;
BA_ "GenSigCycleTime" SG_ 260 MRR_RR_TO_SystemTDBlockage_Flt 20;
BA_ "GenSigSendType" SG_ 260 MRR_RR_TO_SystemTDBlockage_Flt 0;
BA_ "GenSigCycleTime" SG_ 260 MRR_RR_TO_CADMSWVersion_Flt 20;
BA_ "GenSigSendType" SG_ 260 MRR_RR_TO_CADMSWVersion_Flt 0;
BA_ "GenSigCycleTime" SG_ 260 MRR_RR_TO_RADARCfgParameter_Flt 20;
BA_ "GenSigSendType" SG_ 260 MRR_RR_TO_RADARCfgParameter_Flt 0;
BA_ "GenSigCycleTime" SG_ 260 MRR_RR_TO_SATCADMVIN_Flt 20;
BA_ "GenSigSendType" SG_ 260 MRR_RR_TO_SATCADMVIN_Flt 0;
BA_ "GenSigCycleTime" SG_ 260 MRR_RR_TO_CADMTracksChange_Flt 20;
BA_ "GenSigSendType" SG_ 260 MRR_RR_TO_CADMTracksChange_Flt 0;
BA_ "GenSigCycleTime" SG_ 260 MRR_RR_Active_Fault_Status_CRC 20;
BA_ "GenSigSendType" SG_ 260 MRR_RR_Active_Fault_Status_CRC 0;
BA_ "GenSigCycleTime" SG_ 260 MRR_RR_Active_Fault_Status_MC 20;
BA_ "GenSigSendType" SG_ 260 MRR_RR_Active_Fault_Status_MC 0;
BA_ "GenSigCycleTime" SG_ 260 MRR_RR_Dolphin_Flt 20;
BA_ "GenSigSendType" SG_ 260 MRR_RR_Dolphin_Flt 0;
BA_ "GenSigCycleTime" SG_ 260 MRR_RR_RRUCore_Flt 20;
BA_ "GenSigSendType" SG_ 260 MRR_RR_RRUCore_Flt 0;
BA_ "GenSigCycleTime" SG_ 260 MRR_RR_RRUBIST_Flt 20;
BA_ "GenSigSendType" SG_ 260 MRR_RR_RRUBIST_Flt 0;
BA_ "GenSigCycleTime" SG_ 260 MRR_RR_PINPosition_Flt 20;
BA_ "GenSigSendType" SG_ 260 MRR_RR_PINPosition_Flt 0;
BA_ "GenSigCycleTime" SG_ 260 MRR_RR_PCANDataRangeChk_Flt 20;
BA_ "GenSigSendType" SG_ 260 MRR_RR_PCANDataRangeChk_Flt 0;
BA_ "GenSigSendType" SG_ 260 MRR_RR_TO_AngleAdjustmentTable_F 0;
BA_ "GenSigCycleTime" SG_ 260 MRR_RR_TO_AngleAdjustmentTable_F 20;
BA_ "SystemSignalLongSymbol" SG_ 260 MRR_RR_TO_AngleAdjustmentTable_F "MRR_RR_TO_AngleAdjustmentTable_Flt";
BA_ "GenSigSendType" SG_ 260 MRR_RR_TO_CADMSgnlActlVal_Flt 0;
BA_ "GenSigCycleTime" SG_ 260 MRR_RR_TO_CADMSgnlActlVal_Flt 20;
BA_ "GenSigSendType" SG_ 260 MRR_RR_TO_TrigControl_Flt 0;
BA_ "GenSigCycleTime" SG_ 260 MRR_RR_TO_TrigControl_Flt 20;
BA_ "GenSigSendType" SG_ 260 MRR_RR_TO_VehicleState_Flt 0;
BA_ "GenSigCycleTime" SG_ 260 MRR_RR_TO_VehicleState_Flt 20;
BA_ "GenSigSendType" SG_ 260 MRR_RR_MC_AngleAdjTable_Flt 0;
BA_ "GenSigCycleTime" SG_ 260 MRR_RR_MC_AngleAdjTable_Flt 20;
BA_ "GenSigSendType" SG_ 260 MRR_RR_CRC_AngleAdjTable_Flt 0;
BA_ "GenSigCycleTime" SG_ 260 MRR_RR_CRC_AngleAdjTable_Flt 20;
BA_ "GenSigSendType" SG_ 260 MRR_RR_MC_VehicleState_Flt 0;
BA_ "GenSigCycleTime" SG_ 260 MRR_RR_MC_VehicleState_Flt 20;
BA_ "GenSigSendType" SG_ 260 MRR_RR_CRC_VehicleState_Flt 0;
BA_ "GenSigCycleTime" SG_ 260 MRR_RR_CRC_VehicleState_Flt 20;
BA_ "GenSigSendType" SG_ 260 MRR_RR_MC_TrigControl_Flt 0;
BA_ "GenSigCycleTime" SG_ 260 MRR_RR_MC_TrigControl_Flt 20;
BA_ "GenSigSendType" SG_ 260 MRR_RR_CRC_TrigControl_Flt 0;
BA_ "GenSigCycleTime" SG_ 260 MRR_RR_CRC_TrigControl_Flt 20;
BA_ "GenSigSendType" SG_ 260 MRR_RR_CRC_RadarCfgParameter_Flt 0;
BA_ "GenSigCycleTime" SG_ 260 MRR_RR_CRC_RadarCfgParameter_Flt 20;
BA_ "GenSigSendType" SG_ 260 MRR_RR_MC_CADMSgnlActlVal_Flt 0;
BA_ "GenSigCycleTime" SG_ 260 MRR_RR_MC_CADMSgnlActlVal_Flt 20;
BA_ "GenSigSendType" SG_ 260 MRR_RR_CRC_CADMSgnlActlVal_Flt 0;
BA_ "GenSigCycleTime" SG_ 260 MRR_RR_CRC_CADMSgnlActlVal_Flt 20;
BA_ "GenSigSendType" SG_ 260 MRR_RR_VINSignalCompare_Flt 0;
BA_ "GenSigCycleTime" SG_ 260 MRR_RR_VINSignalCompare_Flt 20;
BA_ "GenSigSendType" SG_ 260 MRR_RR_BatteryLow_Flt 0;
BA_ "GenSigCycleTime" SG_ 260 MRR_RR_BatteryLow_Flt 20;
BA_ "GenSigSendType" SG_ 260 MRR_RR_BatteryHigh_Flt 0;
BA_ "GenSigCycleTime" SG_ 260 MRR_RR_BatteryHigh_Flt 20;
BA_ "GenSigSendType" SG_ 260 MRR_RR_Core0_To_Core1_IPC_Flt 0;
BA_ "GenSigCycleTime" SG_ 260 MRR_RR_Core0_To_Core1_IPC_Flt 20;
BA_ "GenSigCycleTime" SG_ 260 MRR_RR_Core1_To_Core0_IPC_Flt 20;
BA_ "GenSigSendType" SG_ 260 MRR_RR_Core1_To_Core0_IPC_Flt 0;
BA_ "GenSigCycleTime" SG_ 260 MRR_RR_Core1_To_Core2_IPC_Flt 20;
BA_ "GenSigSendType" SG_ 260 MRR_RR_Core1_To_Core2_IPC_Flt 0;
BA_ "GenSigCycleTime" SG_ 260 MRR_RR_Core2_To_Core1_IPC_Flt 20;
BA_ "GenSigSendType" SG_ 260 MRR_RR_Core2_To_Core1_IPC_Flt 0;
BA_ "GenSigCycleTime" SG_ 260 MRR_RR_Core2_To_Core0_IPC_Flt 20;
BA_ "GenSigSendType" SG_ 260 MRR_RR_Core2_To_Core0_IPC_Flt 0;
BA_ "GenSigCycleTime" SG_ 260 MRR_RR_Core2Halted_Flt 20;
BA_ "GenSigSendType" SG_ 260 MRR_RR_Core2Halted_Flt 0;
BA_ "GenSigCycleTime" SG_ 260 MRR_RR_Core1Halted_Flt 20;
BA_ "GenSigSendType" SG_ 260 MRR_RR_Core1Halted_Flt 0;
BA_ "GenSigCycleTime" SG_ 260 MRR_RR_LocalOscPower_Flt 20;
BA_ "GenSigSendType" SG_ 260 MRR_RR_LocalOscPower_Flt 0;
BA_ "GenSigCycleTime" SG_ 260 MRR_RR_DSPLoopOverrun_Flt 20;
BA_ "GenSigSendType" SG_ 260 MRR_RR_DSPLoopOverrun_Flt 0;
BA_ "GenSigCycleTime" SG_ 260 MRR_RR_TransmitterPower_Flt 20;
BA_ "GenSigSendType" SG_ 260 MRR_RR_TransmitterPower_Flt 0;
BA_ "GenSigCycleTime" SG_ 260 MRR_RR_Core0_To_Core2_IPC_Flt 20;
BA_ "GenSigSendType" SG_ 260 MRR_RR_Core0_To_Core2_IPC_Flt 0;
BA_ "GenSigCycleTime" SG_ 260 MRR_RR_XCVRDeviceSPI_Flt 20;
BA_ "GenSigSendType" SG_ 260 MRR_RR_XCVRDeviceSPI_Flt 0;
BA_ "GenSigCycleTime" SG_ 260 MRR_RR_MNRBlockage_Flt 20;
BA_ "GenSigSendType" SG_ 260 MRR_RR_MNRBlockage_Flt 0;
BA_ "GenSigCycleTime" SG_ 260 MRR_RR_TransmitterTempHigh_Flt 20;
BA_ "GenSigSendType" SG_ 260 MRR_RR_TransmitterTempHigh_Flt 0;
BA_ "GenSigCycleTime" SG_ 260 MRR_RR_AlignRoutineFailed_Flt 20;
BA_ "GenSigSendType" SG_ 260 MRR_RR_AlignRoutineFailed_Flt 0;
BA_ "GenSigCycleTime" SG_ 260 MRR_RR_MicroTempHigh_Flt 20;
BA_ "GenSigSendType" SG_ 260 MRR_RR_MicroTempHigh_Flt 0;
BA_ "GenSigCycleTime" SG_ 260 MRR_RR_HAlignOutofRange_Flt 20;
BA_ "GenSigSendType" SG_ 260 MRR_RR_HAlignOutofRange_Flt 0;
BA_ "GenSigCycleTime" SG_ 260 MRR_RR_v1p1_SupplyOutOfRange_Flt 20;
BA_ "GenSigSendType" SG_ 260 MRR_RR_v1p1_SupplyOutOfRange_Flt 0;
BA_ "GenSigCycleTime" SG_ 260 MRR_RR_v1p25_SupplyOutOfRange_Fl 20;
BA_ "GenSigSendType" SG_ 260 MRR_RR_v1p25_SupplyOutOfRange_Fl 0;
BA_ "SystemSignalLongSymbol" SG_ 260 MRR_RR_v1p25_SupplyOutOfRange_Fl "MRR_RR_v1p25_SupplyOutOfRange_Flt";
BA_ "GenSigCycleTime" SG_ 260 MRR_RR_v1p8_SupplyOutOfRange_Flt 20;
BA_ "GenSigSendType" SG_ 260 MRR_RR_v1p8_SupplyOutOfRange_Flt 0;
BA_ "GenSigCycleTime" SG_ 260 MRR_RR_v2p3_SupplyOutOfRange_Flt 20;
BA_ "GenSigSendType" SG_ 260 MRR_RR_v2p3_SupplyOutOfRange_Flt 0;
BA_ "GenSigCycleTime" SG_ 260 MRR_RR_v_5_SupplyOutOfRange_Flt 20;
BA_ "GenSigSendType" SG_ 260 MRR_RR_v_5_SupplyOutOfRange_Flt 0;
BA_ "GenSigCycleTime" SG_ 260 MRR_RR_TransmitterID_Flt 20;
BA_ "GenSigSendType" SG_ 260 MRR_RR_TransmitterID_Flt 0;
BA_ "GenSigCycleTime" SG_ 260 MRR_RR_PCANBusOff_Flt 20;
BA_ "GenSigSendType" SG_ 260 MRR_RR_PCANBusOff_Flt 0;
BA_ "GenSigCycleTime" SG_ 260 MRR_RR_InstructionSetCheck_Flt 20;
BA_ "GenSigSendType" SG_ 260 MRR_RR_InstructionSetCheck_Flt 0;
BA_ "GenSigCycleTime" SG_ 260 MRR_RR_StackOverflow_Flt 20;
BA_ "GenSigSendType" SG_ 260 MRR_RR_StackOverflow_Flt 0;
BA_ "GenSigCycleTime" SG_ 260 MRR_RR_Watchdog_Flt 20;
BA_ "GenSigSendType" SG_ 260 MRR_RR_Watchdog_Flt 0;
BA_ "GenSigCycleTime" SG_ 260 MRR_RR_PLLLock_Flt 20;
BA_ "GenSigSendType" SG_ 260 MRR_RR_PLLLock_Flt 0;
BA_ "GenSigCycleTime" SG_ 260 MRR_RR_RAMMemoryTest_Flt 20;
BA_ "GenSigSendType" SG_ 260 MRR_RR_RAMMemoryTest_Flt 0;
BA_ "GenSigVtEn" SG_ 260 MRR_RR_USCValidation_Flt "*";
BA_ "GenSigCycleTime" SG_ 260 MRR_RR_USCValidation_Flt 20;
BA_ "GenSigSendType" SG_ 260 MRR_RR_USCValidation_Flt 0;
BA_ "GenSigCycleTime" SG_ 260 MRR_RR_SMCChecksum_Flt 20;
BA_ "GenSigSendType" SG_ 260 MRR_RR_SMCChecksum_Flt 0;
BA_ "GenSigCycleTime" SG_ 260 MRR_RR_KeepAliveChecksum_Flt 20;
BA_ "GenSigSendType" SG_ 260 MRR_RR_KeepAliveChecksum_Flt 0;
BA_ "GenSigCycleTime" SG_ 260 MRR_RR_ApplicationFlashChksum_Fl 20;
BA_ "GenSigSendType" SG_ 260 MRR_RR_ApplicationFlashChksum_Fl 0;
BA_ "SystemSignalLongSymbol" SG_ 260 MRR_RR_ApplicationFlashChksum_Fl "MRR_RR_ApplicationFlashChksum_Flt";
BA_ "GenSigSendType" SG_ 259 MRR_RR_Alignment_Status_CRC 0;
BA_ "GenSigCycleTime" SG_ 259 MRR_RR_Alignment_Status_CRC 50;
BA_ "GenSigSendType" SG_ 259 MRR_RR_Alignment_Status_MC 0;
BA_ "GenSigCycleTime" SG_ 259 MRR_RR_Alignment_Status_MC 50;
BA_ "GenSigCycleTime" SG_ 259 MRR_RR_CAN_TX_DRIVING_ENVIRONMEN 50;
BA_ "GenSigSendType" SG_ 259 MRR_RR_CAN_TX_DRIVING_ENVIRONMEN 0;
BA_ "SystemSignalLongSymbol" SG_ 259 MRR_RR_CAN_TX_DRIVING_ENVIRONMEN "MRR_RR_CAN_TX_DRIVING_ENVIRONMENT";
BA_ "GenSigCycleTime" SG_ 259 MRR_RR_CAN_TX_ROLLING_COUNT_1 50;
BA_ "GenSigSendType" SG_ 259 MRR_RR_CAN_TX_ROLLING_COUNT_1 0;
BA_ "GenSigSendType" SG_ 259 MRR_RR_CAN_TX_Temperature 0;
BA_ "GenSigCycleTime" SG_ 259 MRR_RR_CAN_TX_Temperature 50;
BA_ "GenSigCycleTime" SG_ 259 MRR_RR_CAN_TX_YAW_RATE_BIAS 50;
BA_ "GenSigSendType" SG_ 259 MRR_RR_CAN_TX_YAW_RATE_BIAS 0;
BA_ "GenSigCycleTime" SG_ 259 MRR_RR_CAN_TX_VEH_SPD_COMP_FACTO 50;
BA_ "GenSigSendType" SG_ 259 MRR_RR_CAN_TX_VEH_SPD_COMP_FACTO 0;
BA_ "SystemSignalLongSymbol" SG_ 259 MRR_RR_CAN_TX_VEH_SPD_COMP_FACTO "MRR_RR_CAN_TX_VEH_SPD_COMP_FACTOR";
BA_ "GenSigCycleTime" SG_ 259 MRR_RR_CAN_TX_AUTO_ALIGN_QUA_FAC 50;
BA_ "GenSigSendType" SG_ 259 MRR_RR_CAN_TX_AUTO_ALIGN_QUA_FAC 0;
BA_ "SystemSignalLongSymbol" SG_ 259 MRR_RR_CAN_TX_AUTO_ALIGN_QUA_FAC "MRR_RR_CAN_TX_AUTO_ALIGN_QUA_FACTOR";
BA_ "GenSigCycleTime" SG_ 259 MRR_RR_CAN_TX_Alignment_MODE 50;
BA_ "GenSigSendType" SG_ 259 MRR_RR_CAN_TX_Alignment_MODE 0;
BA_ "GenSigCycleTime" SG_ 259 MRR_RR_CAN_TX_CURRENT_MISALIGN_A 50;
BA_ "GenSigSendType" SG_ 259 MRR_RR_CAN_TX_CURRENT_MISALIGN_A 0;
BA_ "SystemSignalLongSymbol" SG_ 259 MRR_RR_CAN_TX_CURRENT_MISALIGN_A "MRR_RR_CAN_TX_CURRENT_MISALIGN_ANGLE";
BA_ "GenSigCycleTime" SG_ 259 MRR_RR_CAN_TX_SAVED_MISALIGN_ANG 50;
BA_ "GenSigSendType" SG_ 259 MRR_RR_CAN_TX_SAVED_MISALIGN_ANG 0;
BA_ "SystemSignalLongSymbol" SG_ 259 MRR_RR_CAN_TX_SAVED_MISALIGN_ANG "MRR_RR_CAN_TX_SAVED_MISALIGN_ANGLE";
BA_ "GenSigSendType" SG_ 257 MRR_RR_Dolphin_Chip_ID_Part2 0;
BA_ "GenSigCycleTime" SG_ 257 MRR_RR_Dolphin_Chip_ID_Part2 1000;
BA_ "GenSigCycleTime" SG_ 257 MRR_RR_Dolphin_Chip_ID_Part1 1000;
BA_ "GenSigSendType" SG_ 257 MRR_RR_Dolphin_Chip_ID_Part1 0;
BA_ "GenSigCycleTime" SG_ 257 MRR_RR_RRU_Chip_ID_Part4 1000;
BA_ "GenSigSendType" SG_ 257 MRR_RR_RRU_Chip_ID_Part4 0;
BA_ "GenSigCycleTime" SG_ 257 MRR_RR_RRU_Chip_ID_Part3 1000;
BA_ "GenSigSendType" SG_ 257 MRR_RR_RRU_Chip_ID_Part3 0;
BA_ "GenSigCycleTime" SG_ 257 MRR_RR_RRU_Chip_ID_Part2 1000;
BA_ "GenSigSendType" SG_ 257 MRR_RR_RRU_Chip_ID_Part2 0;
BA_ "GenSigCycleTime" SG_ 257 MRR_RR_RRU_Chip_ID_Part1 1000;
BA_ "GenSigSendType" SG_ 257 MRR_RR_RRU_Chip_ID_Part1 0;
BA_ "GenSigCycleTime" SG_ 257 MRR_RR_CAN_TX_HW_VERSION 1000;
BA_ "GenSigSendType" SG_ 257 MRR_RR_CAN_TX_HW_VERSION 0;
BA_ "GenSigCycleTime" SG_ 258 MRR_RR_CAN_PCAN_PROTOCOL_PROMOTE 1000;
BA_ "GenSigSendType" SG_ 258 MRR_RR_CAN_PCAN_PROTOCOL_PROMOTE 0;
BA_ "GenSigSendType" SG_ 258 MRR_RR_CAN_TX_SW_VERSION_DSP 0;
BA_ "GenSigCycleTime" SG_ 258 MRR_RR_CAN_TX_SW_VERSION_DSP 1000;
BA_ "GenSigCycleTime" SG_ 258 MRR_RR_CAN_TX_SW_VERSION_ARM 1000;
BA_ "GenSigSendType" SG_ 258 MRR_RR_CAN_TX_SW_VERSION_ARM 0;
BA_ "GenSigCycleTime" SG_ 258 MRR_RR_CAN_TX_PCAN_PROTOCOL_MINO 1000;
BA_ "GenSigSendType" SG_ 258 MRR_RR_CAN_TX_PCAN_PROTOCOL_MINO 0;
BA_ "SystemSignalLongSymbol" SG_ 258 MRR_RR_CAN_TX_PCAN_PROTOCOL_MINO "MRR_RR_CAN_TX_PCAN_PROTOCOL_MINOR";
BA_ "GenSigCycleTime" SG_ 258 MRR_RR_CAN_TX_PCAN_PROTOCOL_MAJO 1000;
BA_ "GenSigSendType" SG_ 258 MRR_RR_CAN_TX_PCAN_PROTOCOL_MAJO 0;
BA_ "SystemSignalLongSymbol" SG_ 258 MRR_RR_CAN_TX_PCAN_PROTOCOL_MAJO "MRR_RR_CAN_TX_PCAN_PROTOCOL_MAJOR";
BA_ "GenSigCycleTime" SG_ 258 MRR_RR_CAN_Dyn_Align_Algorithm_V 1000;
BA_ "GenSigSendType" SG_ 258 MRR_RR_CAN_Dyn_Align_Algorithm_V 0;
BA_ "SystemSignalLongSymbol" SG_ 258 MRR_RR_CAN_Dyn_Align_Algorithm_V "MRR_RR_CAN_Dyn_Align_Algorithm_Version_Major";
BA_ "GenSigCycleTime" SG_ 258 MRR_RR_CAN_Dyn_Align_Algori_0000 1000;
BA_ "GenSigSendType" SG_ 258 MRR_RR_CAN_Dyn_Align_Algori_0000 0;
BA_ "SystemSignalLongSymbol" SG_ 258 MRR_RR_CAN_Dyn_Align_Algori_0000 "MRR_RR_CAN_Dyn_Align_Algorithm_Version_Minor";
BA_ "GenSigCycleTime" SG_ 258 MRR_RR_CAN_Dyn_Align_Algori_0001 1000;
BA_ "GenSigSendType" SG_ 258 MRR_RR_CAN_Dyn_Align_Algori_0001 0;
BA_ "SystemSignalLongSymbol" SG_ 258 MRR_RR_CAN_Dyn_Align_Algori_0001 "MRR_RR_CAN_Dyn_Align_Algorithm_Version_Promote";
BA_ "GenSigCycleTime" SG_ 258 MRR_RR_Core_Radar_BB_Version_Fie 1000;
BA_ "GenSigSendType" SG_ 258 MRR_RR_Core_Radar_BB_Version_Fie 0;
BA_ "SystemSignalLongSymbol" SG_ 258 MRR_RR_Core_Radar_BB_Version_Fie "MRR_RR_Core_Radar_BB_Version_Field";
BA_ "GenSigCycleTime" SG_ 258 MRR_RR_Core_Radar_BB_Version_Pro 1000;
BA_ "GenSigSendType" SG_ 258 MRR_RR_Core_Radar_BB_Version_Pro 0;
BA_ "SystemSignalLongSymbol" SG_ 258 MRR_RR_Core_Radar_BB_Version_Pro "MRR_RR_Core_Radar_BB_Version_Promote";
BA_ "GenSigCycleTime" SG_ 258 MRR_RR_Core_Radar_BB_Version_Min 1000;
BA_ "GenSigSendType" SG_ 258 MRR_RR_Core_Radar_BB_Version_Min 0;
BA_ "SystemSignalLongSymbol" SG_ 258 MRR_RR_Core_Radar_BB_Version_Min "MRR_RR_Core_Radar_BB_Version_Minor";
BA_ "GenSigCycleTime" SG_ 258 MRR_RR_Core_Radar_BB_Version_Maj 1000;
BA_ "GenSigSendType" SG_ 258 MRR_RR_Core_Radar_BB_Version_Maj 0;
BA_ "SystemSignalLongSymbol" SG_ 258 MRR_RR_Core_Radar_BB_Version_Maj "MRR_RR_Core_Radar_BB_Version_Major";
BA_ "GenSigCycleTime" SG_ 258 MRR_RR_CAN_USC_Field 1000;
BA_ "GenSigSendType" SG_ 258 MRR_RR_CAN_USC_Field 0;
BA_ "GenSigCycleTime" SG_ 258 MRR_RR_CAN_USC_Promote 1000;
BA_ "GenSigSendType" SG_ 258 MRR_RR_CAN_USC_Promote 0;
BA_ "GenSigCycleTime" SG_ 258 MRR_RR_CAN_USC_Minor 1000;
BA_ "GenSigSendType" SG_ 258 MRR_RR_CAN_USC_Minor 0;
BA_ "GenSigCycleTime" SG_ 258 MRR_RR_CAN_USC_Major 1000;
BA_ "GenSigSendType" SG_ 258 MRR_RR_CAN_USC_Major 0;
BA_ "GenSigCycleTime" SG_ 258 MRR_RR_CAN_SMC_Field 1000;
BA_ "GenSigSendType" SG_ 258 MRR_RR_CAN_SMC_Field 0;
BA_ "GenSigCycleTime" SG_ 258 MRR_RR_CAN_SMC_Promote 1000;
BA_ "GenSigSendType" SG_ 258 MRR_RR_CAN_SMC_Promote 0;
BA_ "GenSigCycleTime" SG_ 258 MRR_RR_CAN_SMC_Minor 1000;
BA_ "GenSigSendType" SG_ 258 MRR_RR_CAN_SMC_Minor 0;
BA_ "GenSigCycleTime" SG_ 258 MRR_RR_CAN_SMC_Major 1000;
BA_ "GenSigSendType" SG_ 258 MRR_RR_CAN_SMC_Major 0;
BA_ "GenSigSendType" SG_ 258 MRR_RR_CAN_TX_Field 0;
BA_ "GenSigCycleTime" SG_ 258 MRR_RR_CAN_TX_Field 1000;
BA_ "GenSigSendType" SG_ 258 MRR_RR_CAN_TX_Promote 0;
BA_ "GenSigCycleTime" SG_ 258 MRR_RR_CAN_TX_Promote 1000;
BA_ "GenSigSendType" SG_ 258 MRR_RR_CAN_TX_Major 0;
BA_ "GenSigCycleTime" SG_ 258 MRR_RR_CAN_TX_Major 1000;
BA_ "GenSigSendType" SG_ 258 MRR_RR_CAN_TX_Hardware 0;
BA_ "GenSigCycleTime" SG_ 258 MRR_RR_CAN_TX_Hardware 1000;
BA_ "GenSigSendType" SG_ 258 MRR_RR_CAN_TX_SERIAL_NUMBER_SEQU 0;
BA_ "GenSigCycleTime" SG_ 258 MRR_RR_CAN_TX_SERIAL_NUMBER_SEQU 1000;
BA_ "SystemSignalLongSymbol" SG_ 258 MRR_RR_CAN_TX_SERIAL_NUMBER_SEQU "MRR_RR_CAN_TX_SERIAL_NUMBER_SEQUENCE";
BA_ "GenSigSendType" SG_ 258 MRR_RR_CAN_TX_SERIAL_NUM_JULIAN_ 0;
BA_ "GenSigCycleTime" SG_ 258 MRR_RR_CAN_TX_SERIAL_NUM_JULIAN_ 1000;
BA_ "SystemSignalLongSymbol" SG_ 258 MRR_RR_CAN_TX_SERIAL_NUM_JULIAN_ "MRR_RR_CAN_TX_SERIAL_NUM_JULIAN_YEAR";
BA_ "GenSigSendType" SG_ 258 MRR_RR_CAN_TX_SERIAL_NUM_JU_0000 0;
BA_ "GenSigCycleTime" SG_ 258 MRR_RR_CAN_TX_SERIAL_NUM_JU_0000 1000;
BA_ "SystemSignalLongSymbol" SG_ 258 MRR_RR_CAN_TX_SERIAL_NUM_JU_0000 "MRR_RR_CAN_TX_SERIAL_NUM_JULIAN_DAY";
BA_ "GenSigSendType" SG_ 258 MRR_RR_CAN_TX_ARM_THROUGHPUT 0;
BA_ "GenSigCycleTime" SG_ 258 MRR_RR_CAN_TX_ARM_THROUGHPUT 1000;
BA_ "GenSigMarked" SG_ 258 MRR_RR_CAN_TX_ARM_THROUGHPUT "*";
BA_ "GenSigSendType" SG_ 258 MRR_RR_CAN_TX_SYSTEM_STATUS 0;
BA_ "GenSigCycleTime" SG_ 258 MRR_RR_CAN_TX_SYSTEM_STATUS 1000;
BA_ "GenSigSendType" SG_ 258 MRR_RR_CAN_TX_LOOK_TYPE_1 0;
BA_ "GenSigCycleTime" SG_ 258 MRR_RR_CAN_TX_LOOK_TYPE_1 1000;
BA_ "GenSigSendType" SG_ 258 MRR_RR_CAN_TX_OVERHEAT_ERROR 0;
BA_ "GenSigCycleTime" SG_ 258 MRR_RR_CAN_TX_OVERHEAT_ERROR 1000;
BA_ "GenSigSendType" SG_ 258 MRR_RR_CAN_TX_RANGE_PERF_ERROR 0;
BA_ "GenSigCycleTime" SG_ 258 MRR_RR_CAN_TX_RANGE_PERF_ERROR 1000;
BA_ "GenSigSendType" SG_ 258 MRR_RR_CAN_TX_COMM_ERROR 0;
BA_ "GenSigCycleTime" SG_ 258 MRR_RR_CAN_TX_COMM_ERROR 1000;
BA_ "GenSigSendType" SG_ 258 MRR_RR_CAN_TX_INTERNAL_ERROR 0;
BA_ "GenSigCycleTime" SG_ 258 MRR_RR_CAN_TX_INTERNAL_ERROR 1000;
BA_ "GenSigSendType" SG_ 258 MRR_RR_CAN_TX_XCVR_OPERATIONAL 0;
BA_ "GenSigCycleTime" SG_ 258 MRR_RR_CAN_TX_XCVR_OPERATIONAL 1000;
BA_ "GenSigCycleTime" SG_ 258 MRR_RR_CAN_PBL_Field_Revision 1000;
BA_ "GenSigSendType" SG_ 258 MRR_RR_CAN_PBL_Field_Revision 0;
BA_ "GenSigSendType" SG_ 258 MRR_RR_CAN_PBL_Promote_Revision 0;
BA_ "GenSigCycleTime" SG_ 258 MRR_RR_CAN_PBL_Promote_Revision 1000;
BA_ "GenSigSendType" SG_ 258 MRR_RR_CAN_SW_Field_Revision 0;
BA_ "GenSigCycleTime" SG_ 258 MRR_RR_CAN_SW_Field_Revision 1000;
BA_ "GenSigSendType" SG_ 258 MRR_RR_CAN_SW_Promote_Revision 0;
BA_ "GenSigCycleTime" SG_ 258 MRR_RR_CAN_SW_Promote_Revision 1000;
BA_ "GenSigSendType" SG_ 258 MRR_RR_CAN_SW_Field 0;
BA_ "GenSigCycleTime" SG_ 258 MRR_RR_CAN_SW_Field 1000;
BA_ "GenSigSendType" SG_ 258 MRR_RR_CAN_SW_Release_Revision 0;
BA_ "GenSigCycleTime" SG_ 258 MRR_RR_CAN_SW_Release_Revision 1000;
BA_ "GenSigSendType" SG_ 258 MRR_RR_CAN_PBL_Release_Revision 0;
BA_ "GenSigCycleTime" SG_ 258 MRR_RR_CAN_PBL_Release_Revision 1000;
BA_ "GenSigCycleTime" SG_ 261 MRR_RR_RRU_Self_Test_Faults_reas 20;
BA_ "GenSigSendType" SG_ 261 MRR_RR_RRU_Self_Test_Faults_reas 0;
BA_ "SystemSignalLongSymbol" SG_ 261 MRR_RR_RRU_Self_Test_Faults_reas "MRR_RR_RRU_Self_Test_Faults_reason1";
BA_ "GenSigCycleTime" SG_ 261 MRR_RR_RRU_Core_Faults_reason3 20;
BA_ "GenSigSendType" SG_ 261 MRR_RR_RRU_Core_Faults_reason3 0;
BA_ "GenSigCycleTime" SG_ 261 MRR_RR_RRU_Core_Faults_reason2 20;
BA_ "GenSigSendType" SG_ 261 MRR_RR_RRU_Core_Faults_reason2 0;
BA_ "GenSigCycleTime" SG_ 261 MRR_RR_RRU_Core_Faults_reason1 20;
BA_ "GenSigSendType" SG_ 261 MRR_RR_RRU_Core_Faults_reason1 0;
BA_ "GenSigCycleTime" SG_ 261 MRR_RR_XBAR_cfg_failure 20;
BA_ "GenSigSendType" SG_ 261 MRR_RR_XBAR_cfg_failure 0;
BA_ "GenSigCycleTime" SG_ 261 MRR_RR_Stack_OVF_fault_reason 20;
BA_ "GenSigSendType" SG_ 261 MRR_RR_Stack_OVF_fault_reason 0;
BA_ "GenSigCycleTime" SG_ 261 MRR_RR_App_flash_checksum_reason 20;
BA_ "GenSigSendType" SG_ 261 MRR_RR_App_flash_checksum_reason 0;
BA_ "GenSigCycleTime" SG_ 261 MRR_RR_KAM_fault_reason 20;
BA_ "GenSigSendType" SG_ 261 MRR_RR_KAM_fault_reason 0;
BA_ "GenSigCycleTime" SG_ 261 MRR_RR_Rx_Radar_Mount_Msg_Fault 20;
BA_ "GenSigSendType" SG_ 261 MRR_RR_Rx_Radar_Mount_Msg_Fault 0;
BA_ "GenSigSendType" SG_ 261 MRR_RR_Dolphin_Fault_Detection 0;
BA_ "GenSigCycleTime" SG_ 261 MRR_RR_Dolphin_Fault_Detection 20;
BA_ "GenSigSendType" SG_ 261 MRR_RR_RRU_Self_Test_Faults_0000 0;
BA_ "GenSigCycleTime" SG_ 261 MRR_RR_RRU_Self_Test_Faults_0000 20;
BA_ "SystemSignalLongSymbol" SG_ 261 MRR_RR_RRU_Self_Test_Faults_0000 "MRR_RR_RRU_Self_Test_Faults_reason0";
BA_ "GenSigSendType" SG_ 261 MRR_RR_RRU_Core_Faults_reason0 0;
BA_ "GenSigCycleTime" SG_ 261 MRR_RR_RRU_Core_Faults_reason0 20;
BA_ "GenSigSendType" SG_ 261 MRR_RR_USC_Load_Error 0;
BA_ "GenSigCycleTime" SG_ 261 MRR_RR_USC_Load_Error 20;
BA_ "GenSigSendType" SG_ 261 MRR_RR_SMC_Load_Error 0;
BA_ "GenSigCycleTime" SG_ 261 MRR_RR_SMC_Load_Error 20;
BA_ "GenSigSendType" SG_ 261 MRR_RR_TX_Temperature_Flt 0;
BA_ "GenSigCycleTime" SG_ 261 MRR_RR_TX_Temperature_Flt 20;
BA_ "GenSigSendType" SG_ 261 MRR_RR_Dsp_Unit_Cal_Blk_Chcksm_E 0;
BA_ "GenSigCycleTime" SG_ 261 MRR_RR_Dsp_Unit_Cal_Blk_Chcksm_E 20;
BA_ "SystemSignalLongSymbol" SG_ 261 MRR_RR_Dsp_Unit_Cal_Blk_Chcksm_E "MRR_RR_Dsp_Unit_Cal_Blk_Chcksm_Error";
BA_ "GenSigSendType" SG_ 261 MRR_RR_Dsp_Unit_Cal_Checksum_Err 0;
BA_ "GenSigCycleTime" SG_ 261 MRR_RR_Dsp_Unit_Cal_Checksum_Err 20;
BA_ "SystemSignalLongSymbol" SG_ 261 MRR_RR_Dsp_Unit_Cal_Checksum_Err "MRR_RR_Dsp_Unit_Cal_Checksum_Error";
BA_ "GenSigSendType" SG_ 261 MRR_RR_Vertical_Misalignment_err 0;
BA_ "GenSigCycleTime" SG_ 261 MRR_RR_Vertical_Misalignment_err 20;
BA_ "SystemSignalLongSymbol" SG_ 261 MRR_RR_Vertical_Misalignment_err "MRR_RR_Vertical_Misalignment_error";
BA_ "GenSigSendType" SG_ 261 MRR_RR_RTN_SPI_Transfer_Error 0;
BA_ "GenSigCycleTime" SG_ 261 MRR_RR_RTN_SPI_Transfer_Error 20;
BA_ "GenSigSendType" SG_ 261 MRR_RR_RRN_SPI_Transfer_Error 0;
BA_ "GenSigCycleTime" SG_ 261 MRR_RR_RRN_SPI_Transfer_Error 20;
BA_ "GenSigSendType" SG_ 261 MRR_RR_Linearizer_SPI_Transfer_E 0;
BA_ "GenSigCycleTime" SG_ 261 MRR_RR_Linearizer_SPI_Transfer_E 20;
BA_ "SystemSignalLongSymbol" SG_ 261 MRR_RR_Linearizer_SPI_Transfer_E "MRR_RR_Linearizer_SPI_Transfer_Error";
BA_ "GenSigSendType" SG_ 261 MRR_RR_ADC_SPI_Transfer_Error 0;
BA_ "GenSigCycleTime" SG_ 261 MRR_RR_ADC_SPI_Transfer_Error 20;
BA_ "GenSigSendType" SG_ 261 MRR_RR_Transmitter_ID_Error 0;
BA_ "GenSigCycleTime" SG_ 261 MRR_RR_Transmitter_ID_Error 20;
BA_ "GenSigSendType" SG_ 261 MRR_RR_Dsp_Loop_Overrun_Error 0;
BA_ "GenSigCycleTime" SG_ 261 MRR_RR_Dsp_Loop_Overrun_Error 20;
BA_ "GenSigSendType" SG_ 261 MRR_RR_Saturated_Tuning_Freq_Err 0;
BA_ "GenSigCycleTime" SG_ 261 MRR_RR_Saturated_Tuning_Freq_Err 20;
BA_ "SystemSignalLongSymbol" SG_ 261 MRR_RR_Saturated_Tuning_Freq_Err "MRR_RR_Saturated_Tuning_Freq_Error";
BA_ "GenSigSendType" SG_ 261 MRR_RR_Radar_Data_sync_error 0;
BA_ "GenSigCycleTime" SG_ 261 MRR_RR_Radar_Data_sync_error 20;
BA_ "GenSigSendType" SG_ 261 MRR_RR_Dsp_Tuning_Sensitivity_Er 0;
BA_ "GenSigCycleTime" SG_ 261 MRR_RR_Dsp_Tuning_Sensitivity_Er 20;
BA_ "SystemSignalLongSymbol" SG_ 261 MRR_RR_Dsp_Tuning_Sensitivity_Er "MRR_RR_Dsp_Tuning_Sensitivity_Error";
BA_ "GenSigSendType" SG_ 261 MRR_RR_Radar_LO_Power_Error 0;
BA_ "GenSigCycleTime" SG_ 261 MRR_RR_Radar_LO_Power_Error 20;
BA_ "GenSigSendType" SG_ 261 MRR_RR_Radar_TX_Power_Error 0;
BA_ "GenSigCycleTime" SG_ 261 MRR_RR_Radar_TX_Power_Error 20;
BA_ "GenSigSendType" SG_ 261 MRR_RR_Timer_Create_Error 0;
BA_ "GenSigCycleTime" SG_ 261 MRR_RR_Timer_Create_Error 20;
BA_ "GenSigSendType" SG_ 261 MRR_RR_Thread_Create_Error 0;
BA_ "GenSigCycleTime" SG_ 261 MRR_RR_Thread_Create_Error 20;
BA_ "GenSigSendType" SG_ 261 MRR_RR_ARM_Calibration_Error 0;
BA_ "GenSigCycleTime" SG_ 261 MRR_RR_ARM_Calibration_Error 20;
BA_ "GenSigSendType" SG_ 261 MRR_RR_SPI_FEE_Error 0;
BA_ "GenSigCycleTime" SG_ 261 MRR_RR_SPI_FEE_Error 20;
BA_ "GenSigSendType" SG_ 261 MRR_RR_SPI_Comm_Error 0;
BA_ "GenSigCycleTime" SG_ 261 MRR_RR_SPI_Comm_Error 20;
BA_ "GenSigSendType" SG_ 261 MRR_RR_Socket_Write_Error 0;
BA_ "GenSigCycleTime" SG_ 261 MRR_RR_Socket_Write_Error 20;
BA_ "GenSigSendType" SG_ 261 MRR_RR_Socket_Read_error 0;
BA_ "GenSigCycleTime" SG_ 261 MRR_RR_Socket_Read_error 20;
BA_ "GenSigSendType" SG_ 261 MRR_RR_Socket_Init_Error 0;
BA_ "GenSigCycleTime" SG_ 261 MRR_RR_Socket_Init_Error 20;
BA_ "GenSigSendType" SG_ 261 MRR_RR_Signal_Wait_Error 0;
BA_ "GenSigCycleTime" SG_ 261 MRR_RR_Signal_Wait_Error 20;
BA_ "GenSigSendType" SG_ 261 MRR_RR_Signal_Send_Error 0;
BA_ "GenSigCycleTime" SG_ 261 MRR_RR_Signal_Send_Error 20;
BA_ "GenSigSendType" SG_ 261 MRR_RR_Signal_Create_Error 0;
BA_ "GenSigCycleTime" SG_ 261 MRR_RR_Signal_Create_Error 20;
BA_ "GenSigSendType" SG_ 261 MRR_RR_Shared_Mem_Write_Error 0;
BA_ "GenSigCycleTime" SG_ 261 MRR_RR_Shared_Mem_Write_Error 20;
BA_ "GenSigSendType" SG_ 261 MRR_RR_Shared_Mem_Read_Error 0;
BA_ "GenSigCycleTime" SG_ 261 MRR_RR_Shared_Mem_Read_Error 20;
BA_ "GenSigSendType" SG_ 261 MRR_RR_Shared_Mem_Config_Error 0;
BA_ "GenSigCycleTime" SG_ 261 MRR_RR_Shared_Mem_Config_Error 20;
BA_ "GenSigSendType" SG_ 261 MRR_RR_Share_Mem_Init_Error 0;
BA_ "GenSigCycleTime" SG_ 261 MRR_RR_Share_Mem_Init_Error 20;
BA_ "GenSigSendType" SG_ 261 MRR_RR_RAM_Test_Error 0;
BA_ "GenSigCycleTime" SG_ 261 MRR_RR_RAM_Test_Error 20;
BA_ "GenSigSendType" SG_ 261 MRR_RR_Num_Errors 0;
BA_ "GenSigCycleTime" SG_ 261 MRR_RR_Num_Errors 20;
BA_ "GenSigSendType" SG_ 261 MRR_RR_MMAP_Memory_Error 0;
BA_ "GenSigCycleTime" SG_ 261 MRR_RR_MMAP_Memory_Error 20;
BA_ "GenSigSendType" SG_ 261 MRR_RR_ISR_Attach_Error 0;
BA_ "GenSigCycleTime" SG_ 261 MRR_RR_ISR_Attach_Error 20;
BA_ "GenSigSendType" SG_ 261 MRR_RR_IPC_DRV_Write_Error 0;
BA_ "GenSigCycleTime" SG_ 261 MRR_RR_IPC_DRV_Write_Error 20;
BA_ "GenSigSendType" SG_ 261 MRR_RR_IPC_DRV_Trigger_Error 0;
BA_ "GenSigCycleTime" SG_ 261 MRR_RR_IPC_DRV_Trigger_Error 20;
BA_ "GenSigSendType" SG_ 261 MRR_RR_IPC_DRV_Sync_Error 0;
BA_ "GenSigCycleTime" SG_ 261 MRR_RR_IPC_DRV_Sync_Error 20;
BA_ "GenSigSendType" SG_ 261 MRR_RR_IPC_DRV_Read_Error 0;
BA_ "GenSigCycleTime" SG_ 261 MRR_RR_IPC_DRV_Read_Error 20;
BA_ "GenSigSendType" SG_ 261 MRR_RR_IPC_DRV_Init_Error 0;
BA_ "GenSigCycleTime" SG_ 261 MRR_RR_IPC_DRV_Init_Error 20;
BA_ "GenSigSendType" SG_ 261 MRR_RR_Interrupt_Enable_Error 0;
BA_ "GenSigCycleTime" SG_ 261 MRR_RR_Interrupt_Enable_Error 20;
BA_ "GenSigSendType" SG_ 261 MRR_RR_HIL_Format_Error 0;
BA_ "GenSigCycleTime" SG_ 261 MRR_RR_HIL_Format_Error 20;
BA_ "GenSigSendType" SG_ 261 MRR_RR_Flash_Filesystem_Error 0;
BA_ "GenSigCycleTime" SG_ 261 MRR_RR_Flash_Filesystem_Error 20;
BA_ "GenSigSendType" SG_ 261 MRR_RR_Error_none 0;
BA_ "GenSigCycleTime" SG_ 261 MRR_RR_Error_none 20;
BA_ "GenSigSendType" SG_ 261 MRR_RR_Dsp_Load_Read_Error 0;
BA_ "GenSigCycleTime" SG_ 261 MRR_RR_Dsp_Load_Read_Error 20;
BA_ "GenSigSendType" SG_ 261 MRR_RR_Dsp_Load_Open_Error 0;
BA_ "GenSigCycleTime" SG_ 261 MRR_RR_Dsp_Load_Open_Error 20;
BA_ "GenSigSendType" SG_ 261 MRR_RR_Dsp_Load_Address_Error 0;
BA_ "GenSigCycleTime" SG_ 261 MRR_RR_Dsp_Load_Address_Error 20;
BA_ "GenSigSendType" SG_ 261 MRR_RR_Dsp_ISP_Write_Error 0;
BA_ "GenSigCycleTime" SG_ 261 MRR_RR_Dsp_ISP_Write_Error 20;
BA_ "GenSigCycleTime" SG_ 261 MRR_RR_Dsp_IPC_Read_Error 20;
BA_ "GenSigSendType" SG_ 261 MRR_RR_Dsp_IPC_Read_Error 0;
BA_ "GenSigCycleTime" SG_ 261 MRR_RR_Dsp_IPC_Init 20;
BA_ "GenSigSendType" SG_ 261 MRR_RR_Dsp_IPC_Init 0;
BA_ "GenSigSendType" SG_ 261 MRR_RR_Dsp_Init_Error 0;
BA_ "GenSigCycleTime" SG_ 261 MRR_RR_Dsp_Init_Error 20;
BA_ "GenSigSendType" SG_ 261 MRR_RR_Dsp_DRV_Start_Error 0;
BA_ "GenSigCycleTime" SG_ 261 MRR_RR_Dsp_DRV_Start_Error 20;
BA_ "GenSigSendType" SG_ 261 MRR_RR_Dsp_DRV_Load_Error 0;
BA_ "GenSigCycleTime" SG_ 261 MRR_RR_Dsp_DRV_Load_Error 20;
BA_ "GenSigSendType" SG_ 261 MRR_RR_Dsp_DRV_Init_Error 0;
BA_ "GenSigCycleTime" SG_ 261 MRR_RR_Dsp_DRV_Init_Error 20;
BA_ "GenSigSendType" SG_ 261 MRR_RR_Dsp_DRV_Init2_error 0;
BA_ "GenSigCycleTime" SG_ 261 MRR_RR_Dsp_DRV_Init2_error 20;
BA_ "GenSigSendType" SG_ 261 MRR_RR_Dsp_DRV_Init1_error 0;
BA_ "GenSigCycleTime" SG_ 261 MRR_RR_Dsp_DRV_Init1_error 20;
BA_ "GenSigSendType" SG_ 261 MRR_RR_CAN_XMT_Error 0;
BA_ "GenSigCycleTime" SG_ 261 MRR_RR_CAN_XMT_Error 20;
BA_ "GenSigSendType" SG_ 261 MRR_RR_CAN_RCV_Error 0;
BA_ "GenSigCycleTime" SG_ 261 MRR_RR_CAN_RCV_Error 20;
BA_ "GenSigSendType" SG_ 261 MRR_RR_CAN_Hardware_Error 0;
BA_ "GenSigCycleTime" SG_ 261 MRR_RR_CAN_Hardware_Error 20;
BA_ "GenSigSendType" SG_ 261 MRR_RR_Always_True 0;
BA_ "GenSigCycleTime" SG_ 261 MRR_RR_Always_True 20;
BA_ "GenSigSendType" SG_ 264 MRR_CAN_RadarWaveform_RR 1;
BA_ "GenSigCmt" SG_ 264 MRR_RR_CAN_RANGE_COVERAGE "CAN range coverage";
BA_ "GenSigCmt" SG_ 264 MRR_RR_CAN_DOPPLER_COVERAGE "CAN range coverage";
BA_ "GenSigCmt" SG_ 264 MRR_RR_CAN_FOV_HOR "CAN range coverage";
BA_ "GenSigCmt" SG_ 264 MRR_RR_CAN_FOV_VER "CAN range coverage";
BA_ "GenSigCycleTime" SG_ 269 MRR_RR_CAN_Dolphin_AFC 100;
BA_ "GenSigSendType" SG_ 269 MRR_RR_CAN_Dolphin_AFC 0;
BA_ "GenSigSendType" SG_ 269 MRR_RR_CAN_Dolphin_Tx3 0;
BA_ "GenSigCycleTime" SG_ 269 MRR_RR_CAN_Dolphin_Tx3 100;
BA_ "GenSigSendType" SG_ 269 MRR_RR_CAN_Dolphin_Tx2 0;
BA_ "GenSigCycleTime" SG_ 269 MRR_RR_CAN_Dolphin_Tx2 100;
BA_ "GenSigSendType" SG_ 269 MRR_RR_CAN_1_8_V 0;
BA_ "GenSigCycleTime" SG_ 269 MRR_RR_CAN_1_8_V 100;
BA_ "GenSigSendType" SG_ 269 MRR_RR_CAN_BATT_VOLTS 0;
BA_ "GenSigCycleTime" SG_ 269 MRR_RR_CAN_BATT_VOLTS 100;
BA_ "GenSigSendType" SG_ 269 MRR_RR_CAN_1_25_V 0;
BA_ "GenSigCycleTime" SG_ 269 MRR_RR_CAN_1_25_V 100;
BA_ "GenSigSendType" SG_ 269 MRR_RR_CAN_5_V 0;
BA_ "GenSigCycleTime" SG_ 269 MRR_RR_CAN_5_V 100;
BA_ "GenSigSendType" SG_ 269 MRR_RR_CAN_1_1_V 0;
BA_ "GenSigCycleTime" SG_ 269 MRR_RR_CAN_1_1_V 100;
BA_ "GenSigSendType" SG_ 269 MRR_RR_CAN_2_3_V 0;
BA_ "GenSigCycleTime" SG_ 269 MRR_RR_CAN_2_3_V 100;
BA_ "GenSigSendType" SG_ 269 MRR_RR_CAN_Dolphin_Tx1 0;
BA_ "GenSigCycleTime" SG_ 269 MRR_RR_CAN_Dolphin_Tx1 100;
BA_ "GenSigSendType" SG_ 269 MRR_RR_CAN_RRU_Temp1 0;
BA_ "GenSigCycleTime" SG_ 269 MRR_RR_CAN_RRU_Temp1 100;
BA_ "SignalDescription" SG_ 1536 MRR_RR_CAN_DET_MID_TARGET_007 "MID_Target_Discrimination";
BA_ "GenSigSendType" SG_ 1536 MRR_RR_CAN_DET_MID_TARGET_007 1;
BA_ "SignalDescription" SG_ 1536 MRR_RR_CAN_DET_MID_TARGET_006 "MID_Target_Discrimination";
BA_ "SignalDescription" SG_ 1536 MRR_RR_CAN_DET_MID_TARGET_005 "MID_Target_Discrimination";
BA_ "SignalDescription" SG_ 1536 MRR_RR_CAN_DET_MID_TARGET_004 "MID_Target_Discrimination";
BA_ "SignalDescription" SG_ 1536 MRR_RR_CAN_DET_MID_TARGET_003 "MID_Target_Discrimination";
BA_ "SignalDescription" SG_ 1536 MRR_RR_CAN_DET_MID_TARGET_002 "MID_Target_Discrimination";
BA_ "SignalDescription" SG_ 1536 MRR_RR_CAN_DET_MID_TARGET_001 "MID_Target_Discrimination";
BA_ "SignalDescription" SG_ 1536 MRR_RR_CAN_DET_Near_TARGET_007 "Near_Target_Discrimination";
BA_ "SignalDescription" SG_ 1536 MRR_RR_CAN_DET_Near_TARGET_006 "Near_Target_Discrimination";
BA_ "SignalDescription" SG_ 1536 MRR_RR_CAN_DET_Near_TARGET_005 "Near_Target_Discrimination";
BA_ "SignalDescription" SG_ 1536 MRR_RR_CAN_DET_Near_TARGET_004 "Near_Target_Discrimination";
BA_ "SignalDescription" SG_ 1536 MRR_RR_CAN_DET_Near_TARGET_003 "Near_Target_Discrimination";
BA_ "SignalDescription" SG_ 1536 MRR_RR_CAN_DET_Near_TARGET_002 "Near_Target_Discrimination";
BA_ "SignalDescription" SG_ 1536 MRR_RR_CAN_DET_Near_TARGET_001 "Near_Target_Discrimination";
BA_ "GenSigStartValue" SG_ 1536 MRR_RR_CAN_DET_ELEVATION_007 63.8646288209607;
BA_ "GenSigCmt" SG_ 1536 MRR_RR_CAN_DET_ELEVATION_007 "Detected object elevation position";
BA_ "GenSigCmt" SG_ 1536 MRR_RR_CAN_DET_SUPER_RES_TARGET_ "Super resolution target";
BA_ "SystemSignalLongSymbol" SG_ 1536 MRR_RR_CAN_DET_SUPER_RES_TARGET_ "MRR_RR_CAN_DET_SUPER_RES_TARGET_007";
BA_ "GenSigCmt" SG_ 1536 MRR_RR_CAN_DET_AZIMUTH_007 "Detected object azimuth position";
BA_ "GenSigStartValue" SG_ 1536 MRR_RR_CAN_DET_AZIMUTH_007 8194.05320813772;
BA_ "GenSigCmt" SG_ 1536 MRR_RR_CAN_DET_CONFID_ELEVATION_ "Elevation Angle Confidence";
BA_ "SystemSignalLongSymbol" SG_ 1536 MRR_RR_CAN_DET_CONFID_ELEVATION_ "MRR_RR_CAN_DET_CONFID_ELEVATION_007";
BA_ "GenSigCmt" SG_ 1536 MRR_RR_CAN_DET_HOST_VEH_CLUTTER_ "Host vehicle clutter";
BA_ "SystemSignalLongSymbol" SG_ 1536 MRR_RR_CAN_DET_HOST_VEH_CLUTTER_ "MRR_RR_CAN_DET_HOST_VEH_CLUTTER_007";
BA_ "GenSigCmt" SG_ 1536 MRR_RR_CAN_DET_RANGE_007 "Detected object range";
BA_ "GenSigVtEn" SG_ 1536 MRR_RR_CAN_DET_CONFID_AZIMUTH_00 "TRUE";
BA_ "GenSigCmt" SG_ 1536 MRR_RR_CAN_DET_CONFID_AZIMUTH_00 "Signal to noise level";
BA_ "SystemSignalLongSymbol" SG_ 1536 MRR_RR_CAN_DET_CONFID_AZIMUTH_00 "MRR_RR_CAN_DET_CONFID_AZIMUTH_007";
BA_ "GenSigCmt" SG_ 1536 MRR_RR_CAN_DET_RANGE_RATE_007 "Detected object range rate";
BA_ "GenSigStartValue" SG_ 1536 MRR_RR_CAN_DET_RANGE_RATE_007 8192;
BA_ "GenSigCmt" SG_ 1536 MRR_RR_CAN_SCAN_INDEX_2LSB_007 "The two LSB of scan index";
BA_ "GenSigCmt" SG_ 1536 MRR_RR_CAN_DET_AMPLITUDE_007 "Detected object amplitude";
BA_ "GenSigStartValue" SG_ 1536 MRR_RR_CAN_DET_AMPLITUDE_007 64;
BA_ "GenSigCmt" SG_ 1536 MRR_RR_CAN_DET_VALID_LEVEL_007 "Detected object valid level";
BA_ "GenSigCmt" SG_ 1536 MRR_RR_CAN_DET_ELEVATION_006 "Detected object elevation position";
BA_ "GenSigStartValue" SG_ 1536 MRR_RR_CAN_DET_ELEVATION_006 63.8646288209607;
BA_ "GenSigCmt" SG_ 1536 MRR_RR_CAN_DET_SUPER_RES_TA_0000 "Super resolution target";
BA_ "SystemSignalLongSymbol" SG_ 1536 MRR_RR_CAN_DET_SUPER_RES_TA_0000 "MRR_RR_CAN_DET_SUPER_RES_TARGET_006";
BA_ "GenSigCmt" SG_ 1536 MRR_RR_CAN_DET_AZIMUTH_006 "Detected object azimuth position";
BA_ "GenSigStartValue" SG_ 1536 MRR_RR_CAN_DET_AZIMUTH_006 8194.05320813772;
BA_ "GenSigCmt" SG_ 1536 MRR_RR_CAN_DET_CONFID_ELEVA_0000 "Elevation Angle Confidence";
BA_ "SystemSignalLongSymbol" SG_ 1536 MRR_RR_CAN_DET_CONFID_ELEVA_0000 "MRR_RR_CAN_DET_CONFID_ELEVATION_006";
BA_ "GenSigCmt" SG_ 1536 MRR_RR_CAN_DET_HOST_VEH_CLU_0000 "Host vehicle clutter";
BA_ "SystemSignalLongSymbol" SG_ 1536 MRR_RR_CAN_DET_HOST_VEH_CLU_0000 "MRR_RR_CAN_DET_HOST_VEH_CLUTTER_006";
BA_ "GenSigCmt" SG_ 1536 MRR_RR_CAN_DET_RANGE_006 "Detected object range";
BA_ "GenSigVtEn" SG_ 1536 MRR_RR_CAN_DET_CONFID_AZIMU_0000 "TRUE";
BA_ "GenSigCmt" SG_ 1536 MRR_RR_CAN_DET_CONFID_AZIMU_0000 "Signal to noise level";
BA_ "SystemSignalLongSymbol" SG_ 1536 MRR_RR_CAN_DET_CONFID_AZIMU_0000 "MRR_RR_CAN_DET_CONFID_AZIMUTH_006";
BA_ "GenSigCmt" SG_ 1536 MRR_RR_CAN_DET_RANGE_RATE_006 "Detected object range rate";
BA_ "GenSigStartValue" SG_ 1536 MRR_RR_CAN_DET_RANGE_RATE_006 8192;
BA_ "GenSigCmt" SG_ 1536 MRR_RR_CAN_SCAN_INDEX_2LSB_006 "The two LSB of scan index";
BA_ "GenSigCmt" SG_ 1536 MRR_RR_CAN_DET_AMPLITUDE_006 "Detected object amplitude";
BA_ "GenSigStartValue" SG_ 1536 MRR_RR_CAN_DET_AMPLITUDE_006 64;
BA_ "GenSigCmt" SG_ 1536 MRR_RR_CAN_DET_VALID_LEVEL_006 "Detected object valid level";
BA_ "GenSigCmt" SG_ 1536 MRR_RR_CAN_DET_ELEVATION_005 "Detected object elevation position";
BA_ "GenSigStartValue" SG_ 1536 MRR_RR_CAN_DET_ELEVATION_005 63.8646288209607;
BA_ "GenSigCmt" SG_ 1536 MRR_RR_CAN_DET_SUPER_RES_TA_0001 "Super resolution target";
BA_ "SystemSignalLongSymbol" SG_ 1536 MRR_RR_CAN_DET_SUPER_RES_TA_0001 "MRR_RR_CAN_DET_SUPER_RES_TARGET_005";
BA_ "GenSigCmt" SG_ 1536 MRR_RR_CAN_DET_AZIMUTH_005 "Detected object azimuth position";
BA_ "GenSigStartValue" SG_ 1536 MRR_RR_CAN_DET_AZIMUTH_005 8194.05320813772;
BA_ "GenSigCmt" SG_ 1536 MRR_RR_CAN_DET_CONFID_ELEVA_0001 "Elevation Angle Confidence";
BA_ "SystemSignalLongSymbol" SG_ 1536 MRR_RR_CAN_DET_CONFID_ELEVA_0001 "MRR_RR_CAN_DET_CONFID_ELEVATION_005";
BA_ "GenSigCmt" SG_ 1536 MRR_RR_CAN_DET_HOST_VEH_CLU_0001 "Host vehicle clutter";
BA_ "SystemSignalLongSymbol" SG_ 1536 MRR_RR_CAN_DET_HOST_VEH_CLU_0001 "MRR_RR_CAN_DET_HOST_VEH_CLUTTER_005";
BA_ "GenSigCmt" SG_ 1536 MRR_RR_CAN_DET_RANGE_005 "Detected object range";
BA_ "GenSigVtEn" SG_ 1536 MRR_RR_CAN_DET_CONFID_AZIMU_0001 "TRUE";
BA_ "GenSigCmt" SG_ 1536 MRR_RR_CAN_DET_CONFID_AZIMU_0001 "Signal to noise level";
BA_ "SystemSignalLongSymbol" SG_ 1536 MRR_RR_CAN_DET_CONFID_AZIMU_0001 "MRR_RR_CAN_DET_CONFID_AZIMUTH_005";
BA_ "GenSigCmt" SG_ 1536 MRR_RR_CAN_DET_RANGE_RATE_005 "Detected object range rate";
BA_ "GenSigStartValue" SG_ 1536 MRR_RR_CAN_DET_RANGE_RATE_005 8192;
BA_ "GenSigCmt" SG_ 1536 MRR_RR_CAN_SCAN_INDEX_2LSB_005 "The two LSB of scan index";
BA_ "GenSigCmt" SG_ 1536 MRR_RR_CAN_DET_AMPLITUDE_005 "Detected object amplitude";
BA_ "GenSigStartValue" SG_ 1536 MRR_RR_CAN_DET_AMPLITUDE_005 64;
BA_ "GenSigCmt" SG_ 1536 MRR_RR_CAN_DET_VALID_LEVEL_005 "Detected object valid level";
BA_ "GenSigCmt" SG_ 1536 MRR_RR_CAN_DET_ELEVATION_004 "Detected object elevation position";
BA_ "GenSigStartValue" SG_ 1536 MRR_RR_CAN_DET_ELEVATION_004 63.8646288209607;
BA_ "GenSigCmt" SG_ 1536 MRR_RR_CAN_DET_SUPER_RES_TA_0002 "Super resolution target";
BA_ "SystemSignalLongSymbol" SG_ 1536 MRR_RR_CAN_DET_SUPER_RES_TA_0002 "MRR_RR_CAN_DET_SUPER_RES_TARGET_004";
BA_ "GenSigCmt" SG_ 1536 MRR_RR_CAN_DET_AZIMUTH_004 "Detected object azimuth position";
BA_ "GenSigStartValue" SG_ 1536 MRR_RR_CAN_DET_AZIMUTH_004 8194.05320813772;
BA_ "GenSigCmt" SG_ 1536 MRR_RR_CAN_DET_CONFID_ELEVA_0002 "Elevation Angle Confidence";
BA_ "SystemSignalLongSymbol" SG_ 1536 MRR_RR_CAN_DET_CONFID_ELEVA_0002 "MRR_RR_CAN_DET_CONFID_ELEVATION_004";
BA_ "GenSigCmt" SG_ 1536 MRR_RR_CAN_DET_HOST_VEH_CLU_0002 "Host vehicle clutter";
BA_ "SystemSignalLongSymbol" SG_ 1536 MRR_RR_CAN_DET_HOST_VEH_CLU_0002 "MRR_RR_CAN_DET_HOST_VEH_CLUTTER_004";
BA_ "GenSigCmt" SG_ 1536 MRR_RR_CAN_DET_RANGE_004 "Detected object range";
BA_ "GenSigCmt" SG_ 1536 MRR_RR_CAN_DET_CONFID_AZIMU_0002 "Signal to noise level";
BA_ "GenSigVtEn" SG_ 1536 MRR_RR_CAN_DET_CONFID_AZIMU_0002 "TRUE";
BA_ "SystemSignalLongSymbol" SG_ 1536 MRR_RR_CAN_DET_CONFID_AZIMU_0002 "MRR_RR_CAN_DET_CONFID_AZIMUTH_004";
BA_ "GenSigCmt" SG_ 1536 MRR_RR_CAN_DET_RANGE_RATE_004 "Detected object range rate";
BA_ "GenSigStartValue" SG_ 1536 MRR_RR_CAN_DET_RANGE_RATE_004 8192;
BA_ "GenSigCmt" SG_ 1536 MRR_RR_CAN_SCAN_INDEX_2LSB_004 "The two LSB of scan index";
BA_ "GenSigCmt" SG_ 1536 MRR_RR_CAN_DET_AMPLITUDE_004 "Detected object amplitude";
BA_ "GenSigStartValue" SG_ 1536 MRR_RR_CAN_DET_AMPLITUDE_004 64;
BA_ "GenSigCmt" SG_ 1536 MRR_RR_CAN_DET_VALID_LEVEL_004 "Detected object valid level";
BA_ "GenSigCmt" SG_ 1536 MRR_RR_CAN_DET_ELEVATION_003 "Detected object elevation position";
BA_ "GenSigStartValue" SG_ 1536 MRR_RR_CAN_DET_ELEVATION_003 63.8646288209607;
BA_ "GenSigCmt" SG_ 1536 MRR_RR_CAN_DET_SUPER_RES_TA_0003 "Super resolution target";
BA_ "SystemSignalLongSymbol" SG_ 1536 MRR_RR_CAN_DET_SUPER_RES_TA_0003 "MRR_RR_CAN_DET_SUPER_RES_TARGET_003";
BA_ "GenSigCmt" SG_ 1536 MRR_RR_CAN_DET_AZIMUTH_003 "Detected object azimuth position";
BA_ "GenSigStartValue" SG_ 1536 MRR_RR_CAN_DET_AZIMUTH_003 8194.05320813772;
BA_ "GenSigCmt" SG_ 1536 MRR_RR_CAN_DET_CONFID_ELEVA_0003 "Elevation Angle Confidence";
BA_ "SystemSignalLongSymbol" SG_ 1536 MRR_RR_CAN_DET_CONFID_ELEVA_0003 "MRR_RR_CAN_DET_CONFID_ELEVATION_003";
BA_ "GenSigCmt" SG_ 1536 MRR_RR_CAN_DET_HOST_VEH_CLU_0003 "Host vehicle clutter";
BA_ "SystemSignalLongSymbol" SG_ 1536 MRR_RR_CAN_DET_HOST_VEH_CLU_0003 "MRR_RR_CAN_DET_HOST_VEH_CLUTTER_003";
BA_ "GenSigCmt" SG_ 1536 MRR_RR_CAN_DET_RANGE_003 "Detected object range";
BA_ "GenSigCmt" SG_ 1536 MRR_RR_CAN_DET_CONFID_AZIMU_0003 "Signal to noise level";
BA_ "GenSigVtEn" SG_ 1536 MRR_RR_CAN_DET_CONFID_AZIMU_0003 "TRUE";
BA_ "SystemSignalLongSymbol" SG_ 1536 MRR_RR_CAN_DET_CONFID_AZIMU_0003 "MRR_RR_CAN_DET_CONFID_AZIMUTH_003";
BA_ "GenSigCmt" SG_ 1536 MRR_RR_CAN_DET_RANGE_RATE_003 "Detected object range rate";
BA_ "GenSigStartValue" SG_ 1536 MRR_RR_CAN_DET_RANGE_RATE_003 8192;
BA_ "GenSigCmt" SG_ 1536 MRR_RR_CAN_SCAN_INDEX_2LSB_003 "The two LSB of scan index";
BA_ "GenSigCmt" SG_ 1536 MRR_RR_CAN_DET_AMPLITUDE_003 "Detected object amplitude";
BA_ "GenSigStartValue" SG_ 1536 MRR_RR_CAN_DET_AMPLITUDE_003 64;
BA_ "GenSigCmt" SG_ 1536 MRR_RR_CAN_DET_VALID_LEVEL_003 "Detected object valid level";
BA_ "GenSigCmt" SG_ 1536 MRR_RR_CAN_DET_ELEVATION_002 "Detected object elevation position";
BA_ "GenSigStartValue" SG_ 1536 MRR_RR_CAN_DET_ELEVATION_002 63.8646288209607;
BA_ "GenSigCmt" SG_ 1536 MRR_RR_CAN_DET_SUPER_RES_TA_0004 "Super resolution target";
BA_ "SystemSignalLongSymbol" SG_ 1536 MRR_RR_CAN_DET_SUPER_RES_TA_0004 "MRR_RR_CAN_DET_SUPER_RES_TARGET_002";
BA_ "GenSigCmt" SG_ 1536 MRR_RR_CAN_DET_AZIMUTH_002 "Detected object azimuth position";
BA_ "GenSigStartValue" SG_ 1536 MRR_RR_CAN_DET_AZIMUTH_002 8194.05320813772;
BA_ "GenSigCmt" SG_ 1536 MRR_RR_CAN_DET_CONFID_ELEVA_0004 "Elevation Angle Confidence";
BA_ "SystemSignalLongSymbol" SG_ 1536 MRR_RR_CAN_DET_CONFID_ELEVA_0004 "MRR_RR_CAN_DET_CONFID_ELEVATION_002";
BA_ "GenSigCmt" SG_ 1536 MRR_RR_CAN_DET_HOST_VEH_CLU_0004 "Host vehicle clutter";
BA_ "SystemSignalLongSymbol" SG_ 1536 MRR_RR_CAN_DET_HOST_VEH_CLU_0004 "MRR_RR_CAN_DET_HOST_VEH_CLUTTER_002";
BA_ "GenSigCmt" SG_ 1536 MRR_RR_CAN_DET_RANGE_002 "Detected object range";
BA_ "GenSigCmt" SG_ 1536 MRR_RR_CAN_DET_CONFID_AZIMU_0004 "Signal to noise level";
BA_ "GenSigVtEn" SG_ 1536 MRR_RR_CAN_DET_CONFID_AZIMU_0004 "TRUE";
BA_ "SystemSignalLongSymbol" SG_ 1536 MRR_RR_CAN_DET_CONFID_AZIMU_0004 "MRR_RR_CAN_DET_CONFID_AZIMUTH_002";
BA_ "GenSigCmt" SG_ 1536 MRR_RR_CAN_DET_RANGE_RATE_002 "Detected object range rate";
BA_ "GenSigStartValue" SG_ 1536 MRR_RR_CAN_DET_RANGE_RATE_002 8192;
BA_ "GenSigCmt" SG_ 1536 MRR_RR_CAN_SCAN_INDEX_2LSB_002 "The two LSB of scan index";
BA_ "GenSigCmt" SG_ 1536 MRR_RR_CAN_DET_AMPLITUDE_002 "Detected object amplitude";
BA_ "GenSigStartValue" SG_ 1536 MRR_RR_CAN_DET_AMPLITUDE_002 64;
BA_ "GenSigCmt" SG_ 1536 MRR_RR_CAN_DET_VALID_LEVEL_002 "Detected object valid level";
BA_ "GenSigCmt" SG_ 1536 MRR_RR_CAN_DET_ELEVATION_001 "Detected object elevation position";
BA_ "GenSigStartValue" SG_ 1536 MRR_RR_CAN_DET_ELEVATION_001 63.8646288209607;
BA_ "GenSigCmt" SG_ 1536 MRR_RR_CAN_DET_CONFID_AZIMU_0005 "Signal to noise level";
BA_ "GenSigVtEn" SG_ 1536 MRR_RR_CAN_DET_CONFID_AZIMU_0005 "TRUE";
BA_ "SystemSignalLongSymbol" SG_ 1536 MRR_RR_CAN_DET_CONFID_AZIMU_0005 "MRR_RR_CAN_DET_CONFID_AZIMUTH_001";
BA_ "GenSigCmt" SG_ 1536 MRR_RR_CAN_DET_SUPER_RES_TA_0005 "Super resolution target";
BA_ "SystemSignalLongSymbol" SG_ 1536 MRR_RR_CAN_DET_SUPER_RES_TA_0005 "MRR_RR_CAN_DET_SUPER_RES_TARGET_001";
BA_ "GenSigCmt" SG_ 1536 MRR_RR_CAN_DET_CONFID_ELEVA_0005 "Elevation Angle Confidence";
BA_ "SystemSignalLongSymbol" SG_ 1536 MRR_RR_CAN_DET_CONFID_ELEVA_0005 "MRR_RR_CAN_DET_CONFID_ELEVATION_001";
BA_ "GenSigCmt" SG_ 1536 MRR_RR_CAN_DET_HOST_VEH_CLU_0005 "Host vehicle clutter";
BA_ "SystemSignalLongSymbol" SG_ 1536 MRR_RR_CAN_DET_HOST_VEH_CLU_0005 "MRR_RR_CAN_DET_HOST_VEH_CLUTTER_001";
BA_ "GenSigCmt" SG_ 1536 MRR_RR_CAN_DET_VALID_LEVEL_001 "Detected object valid level";
BA_ "GenSigCmt" SG_ 1536 MRR_RR_CAN_DET_AZIMUTH_001 "Detected object azimuth position";
BA_ "GenSigStartValue" SG_ 1536 MRR_RR_CAN_DET_AZIMUTH_001 8194.05320813772;
BA_ "GenSigCmt" SG_ 1536 MRR_RR_CAN_DET_RANGE_001 "Detected object range";
BA_ "GenSigCmt" SG_ 1536 MRR_RR_CAN_DET_RANGE_RATE_001 "Detected object range rate";
BA_ "GenSigStartValue" SG_ 1536 MRR_RR_CAN_DET_RANGE_RATE_001 8192;
BA_ "GenSigCmt" SG_ 1536 MRR_RR_CAN_DET_AMPLITUDE_001 "Detected object amplitude";
BA_ "GenSigStartValue" SG_ 1536 MRR_RR_CAN_DET_AMPLITUDE_001 64;
BA_ "GenSigCmt" SG_ 1536 MRR_RR_CAN_SCAN_INDEX_2LSB_001 "The two LSB of scan index";
BA_ "GenSigSendType" SG_ 1537 MRR_RR_CAN_DET_MID_TARGET_014 1;
BA_ "SignalDescription" SG_ 1537 MRR_RR_CAN_DET_MID_TARGET_014 "MID_Target_Discrimination";
BA_ "SignalDescription" SG_ 1537 MRR_RR_CAN_DET_MID_TARGET_013 "MID_Target_Discrimination";
BA_ "SignalDescription" SG_ 1537 MRR_RR_CAN_DET_MID_TARGET_012 "MID_Target_Discrimination";
BA_ "SignalDescription" SG_ 1537 MRR_RR_CAN_DET_MID_TARGET_011 "MID_Target_Discrimination";
BA_ "SignalDescription" SG_ 1537 MRR_RR_CAN_DET_MID_TARGET_010 "MID_Target_Discrimination";
BA_ "SignalDescription" SG_ 1537 MRR_RR_CAN_DET_MID_TARGET_009 "MID_Target_Discrimination";
BA_ "SignalDescription" SG_ 1537 MRR_RR_CAN_DET_MID_TARGET_008 "MID_Target_Discrimination";
BA_ "SignalDescription" SG_ 1537 MRR_RR_CAN_DET_Near_TARGET_008 "Near_Target_Discrimination";
BA_ "SignalDescription" SG_ 1537 MRR_RR_CAN_DET_Near_TARGET_009 "Near_Target_Discrimination";
BA_ "SignalDescription" SG_ 1537 MRR_RR_CAN_DET_Near_TARGET_010 "Near_Target_Discrimination";
BA_ "SignalDescription" SG_ 1537 MRR_RR_CAN_DET_Near_TARGET_011 "Near_Target_Discrimination";
BA_ "SignalDescription" SG_ 1537 MRR_RR_CAN_DET_Near_TARGET_012 "Near_Target_Discrimination";
BA_ "SignalDescription" SG_ 1537 MRR_RR_CAN_DET_Near_TARGET_013 "Near_Target_Discrimination";
BA_ "SignalDescription" SG_ 1537 MRR_RR_CAN_DET_Near_TARGET_014 "Near_Target_Discrimination";
BA_ "GenSigCmt" SG_ 1537 MRR_RR_CAN_DET_ELEVATION_008 "Detected object elevation position";
BA_ "GenSigStartValue" SG_ 1537 MRR_RR_CAN_DET_ELEVATION_008 63.8646288209607;
BA_ "GenSigVtEn" SG_ 1537 MRR_RR_CAN_DET_CONFID_AZIMU_0006 "TRUE";
BA_ "GenSigCmt" SG_ 1537 MRR_RR_CAN_DET_CONFID_AZIMU_0006 "Signal to noise level";
BA_ "SystemSignalLongSymbol" SG_ 1537 MRR_RR_CAN_DET_CONFID_AZIMU_0006 "MRR_RR_CAN_DET_CONFID_AZIMUTH_008";
BA_ "GenSigCmt" SG_ 1537 MRR_RR_CAN_DET_SUPER_RES_TA_0006 "Super resolution target";
BA_ "SystemSignalLongSymbol" SG_ 1537 MRR_RR_CAN_DET_SUPER_RES_TA_0006 "MRR_RR_CAN_DET_SUPER_RES_TARGET_008";
BA_ "GenSigCmt" SG_ 1537 MRR_RR_CAN_DET_CONFID_ELEVA_0006 "Elevation Angle Confidence";
BA_ "SystemSignalLongSymbol" SG_ 1537 MRR_RR_CAN_DET_CONFID_ELEVA_0006 "MRR_RR_CAN_DET_CONFID_ELEVATION_008";
BA_ "GenSigCmt" SG_ 1537 MRR_RR_CAN_DET_HOST_VEH_CLU_0006 "Host vehicle clutter";
BA_ "SystemSignalLongSymbol" SG_ 1537 MRR_RR_CAN_DET_HOST_VEH_CLU_0006 "MRR_RR_CAN_DET_HOST_VEH_CLUTTER_008";
BA_ "GenSigCmt" SG_ 1537 MRR_RR_CAN_DET_VALID_LEVEL_008 "Detected object valid level";
BA_ "GenSigCmt" SG_ 1537 MRR_RR_CAN_DET_AZIMUTH_008 "Detected object azimuth position";
BA_ "GenSigStartValue" SG_ 1537 MRR_RR_CAN_DET_AZIMUTH_008 8194.05320813772;
BA_ "GenSigCmt" SG_ 1537 MRR_RR_CAN_DET_RANGE_008 "Detected object range";
BA_ "GenSigCmt" SG_ 1537 MRR_RR_CAN_DET_RANGE_RATE_008 "Detected object range rate";
BA_ "GenSigStartValue" SG_ 1537 MRR_RR_CAN_DET_RANGE_RATE_008 8192;
BA_ "GenSigCmt" SG_ 1537 MRR_RR_CAN_DET_AMPLITUDE_008 "Detected object amplitude";
BA_ "GenSigStartValue" SG_ 1537 MRR_RR_CAN_DET_AMPLITUDE_008 64;
BA_ "GenSigCmt" SG_ 1537 MRR_RR_CAN_SCAN_INDEX_2LSB_008 "The two LSB of scan index";
BA_ "GenSigStartValue" SG_ 1537 MRR_RR_CAN_DET_ELEVATION_014 63.8646288209607;
BA_ "GenSigCmt" SG_ 1537 MRR_RR_CAN_DET_ELEVATION_014 "Detected object elevation position";
BA_ "GenSigCmt" SG_ 1537 MRR_RR_CAN_DET_SUPER_RES_TA_0007 "Super resolution target";
BA_ "SystemSignalLongSymbol" SG_ 1537 MRR_RR_CAN_DET_SUPER_RES_TA_0007 "MRR_RR_CAN_DET_SUPER_RES_TARGET_014";
BA_ "GenSigCmt" SG_ 1537 MRR_RR_CAN_DET_AZIMUTH_014 "Detected object azimuth position";
BA_ "GenSigStartValue" SG_ 1537 MRR_RR_CAN_DET_AZIMUTH_014 8194.05320813772;
BA_ "GenSigCmt" SG_ 1537 MRR_RR_CAN_DET_CONFID_ELEVA_0007 "Elevation Angle Confidence";
BA_ "SystemSignalLongSymbol" SG_ 1537 MRR_RR_CAN_DET_CONFID_ELEVA_0007 "MRR_RR_CAN_DET_CONFID_ELEVATION_014";
BA_ "GenSigCmt" SG_ 1537 MRR_RR_CAN_DET_HOST_VEH_CLU_0007 "Host vehicle clutter";
BA_ "SystemSignalLongSymbol" SG_ 1537 MRR_RR_CAN_DET_HOST_VEH_CLU_0007 "MRR_RR_CAN_DET_HOST_VEH_CLUTTER_014";
BA_ "GenSigCmt" SG_ 1537 MRR_RR_CAN_DET_RANGE_014 "Detected object range";
BA_ "GenSigVtEn" SG_ 1537 MRR_RR_CAN_DET_CONFID_AZIMUTH_01 "TRUE";
BA_ "GenSigCmt" SG_ 1537 MRR_RR_CAN_DET_CONFID_AZIMUTH_01 "Signal to noise level";
BA_ "SystemSignalLongSymbol" SG_ 1537 MRR_RR_CAN_DET_CONFID_AZIMUTH_01 "MRR_RR_CAN_DET_CONFID_AZIMUTH_014";
BA_ "GenSigCmt" SG_ 1537 MRR_RR_CAN_DET_RANGE_RATE_014 "Detected object range rate";
BA_ "GenSigStartValue" SG_ 1537 MRR_RR_CAN_DET_RANGE_RATE_014 8192;
BA_ "GenSigCmt" SG_ 1537 MRR_RR_CAN_SCAN_INDEX_2LSB_014 "The two LSB of scan index";
BA_ "GenSigCmt" SG_ 1537 MRR_RR_CAN_DET_AMPLITUDE_014 "Detected object amplitude";
BA_ "GenSigStartValue" SG_ 1537 MRR_RR_CAN_DET_AMPLITUDE_014 64;
BA_ "GenSigCmt" SG_ 1537 MRR_RR_CAN_DET_VALID_LEVEL_014 "Detected object valid level";
BA_ "GenSigCmt" SG_ 1537 MRR_RR_CAN_DET_ELEVATION_013 "Detected object elevation position";
BA_ "GenSigStartValue" SG_ 1537 MRR_RR_CAN_DET_ELEVATION_013 63.8646288209607;
BA_ "GenSigCmt" SG_ 1537 MRR_RR_CAN_DET_SUPER_RES_TA_0008 "Super resolution target";
BA_ "SystemSignalLongSymbol" SG_ 1537 MRR_RR_CAN_DET_SUPER_RES_TA_0008 "MRR_RR_CAN_DET_SUPER_RES_TARGET_013";
BA_ "GenSigCmt" SG_ 1537 MRR_RR_CAN_DET_AZIMUTH_013 "Detected object azimuth position";
BA_ "GenSigStartValue" SG_ 1537 MRR_RR_CAN_DET_AZIMUTH_013 8194.05320813772;
BA_ "GenSigCmt" SG_ 1537 MRR_RR_CAN_DET_CONFID_ELEVA_0008 "Elevation Angle Confidence";
BA_ "SystemSignalLongSymbol" SG_ 1537 MRR_RR_CAN_DET_CONFID_ELEVA_0008 "MRR_RR_CAN_DET_CONFID_ELEVATION_013";
BA_ "GenSigCmt" SG_ 1537 MRR_RR_CAN_DET_HOST_VEH_CLU_0008 "Host vehicle clutter";
BA_ "SystemSignalLongSymbol" SG_ 1537 MRR_RR_CAN_DET_HOST_VEH_CLU_0008 "MRR_RR_CAN_DET_HOST_VEH_CLUTTER_013";
BA_ "GenSigCmt" SG_ 1537 MRR_RR_CAN_DET_RANGE_013 "Detected object range";
BA_ "GenSigVtEn" SG_ 1537 MRR_RR_CAN_DET_CONFID_AZIMU_0007 "TRUE";
BA_ "GenSigCmt" SG_ 1537 MRR_RR_CAN_DET_CONFID_AZIMU_0007 "Signal to noise level";
BA_ "SystemSignalLongSymbol" SG_ 1537 MRR_RR_CAN_DET_CONFID_AZIMU_0007 "MRR_RR_CAN_DET_CONFID_AZIMUTH_013";
BA_ "GenSigCmt" SG_ 1537 MRR_RR_CAN_DET_RANGE_RATE_013 "Detected object range rate";
BA_ "GenSigStartValue" SG_ 1537 MRR_RR_CAN_DET_RANGE_RATE_013 8192;
BA_ "GenSigCmt" SG_ 1537 MRR_RR_CAN_SCAN_INDEX_2LSB_013 "The two LSB of scan index";
BA_ "GenSigCmt" SG_ 1537 MRR_RR_CAN_DET_AMPLITUDE_013 "Detected object amplitude";
BA_ "GenSigStartValue" SG_ 1537 MRR_RR_CAN_DET_AMPLITUDE_013 64;
BA_ "GenSigCmt" SG_ 1537 MRR_RR_CAN_DET_VALID_LEVEL_013 "Detected object valid level";
BA_ "GenSigCmt" SG_ 1537 MRR_RR_CAN_DET_ELEVATION_012 "Detected object elevation position";
BA_ "GenSigStartValue" SG_ 1537 MRR_RR_CAN_DET_ELEVATION_012 63.8646288209607;
BA_ "GenSigCmt" SG_ 1537 MRR_RR_CAN_DET_SUPER_RES_TA_0009 "Super resolution target";
BA_ "SystemSignalLongSymbol" SG_ 1537 MRR_RR_CAN_DET_SUPER_RES_TA_0009 "MRR_RR_CAN_DET_SUPER_RES_TARGET_012";
BA_ "GenSigCmt" SG_ 1537 MRR_RR_CAN_DET_AZIMUTH_012 "Detected object azimuth position";
BA_ "GenSigStartValue" SG_ 1537 MRR_RR_CAN_DET_AZIMUTH_012 8194.05320813772;
BA_ "GenSigCmt" SG_ 1537 MRR_RR_CAN_DET_CONFID_ELEVA_0009 "Elevation Angle Confidence";
BA_ "SystemSignalLongSymbol" SG_ 1537 MRR_RR_CAN_DET_CONFID_ELEVA_0009 "MRR_RR_CAN_DET_CONFID_ELEVATION_012";
BA_ "GenSigCmt" SG_ 1537 MRR_RR_CAN_DET_HOST_VEH_CLU_0009 "Host vehicle clutter";
BA_ "SystemSignalLongSymbol" SG_ 1537 MRR_RR_CAN_DET_HOST_VEH_CLU_0009 "MRR_RR_CAN_DET_HOST_VEH_CLUTTER_012";
BA_ "GenSigCmt" SG_ 1537 MRR_RR_CAN_DET_RANGE_012 "Detected object range";
BA_ "GenSigVtEn" SG_ 1537 MRR_RR_CAN_DET_CONFID_AZIMU_0008 "TRUE";
BA_ "GenSigCmt" SG_ 1537 MRR_RR_CAN_DET_CONFID_AZIMU_0008 "Signal to noise level";
BA_ "SystemSignalLongSymbol" SG_ 1537 MRR_RR_CAN_DET_CONFID_AZIMU_0008 "MRR_RR_CAN_DET_CONFID_AZIMUTH_012";
BA_ "GenSigCmt" SG_ 1537 MRR_RR_CAN_DET_RANGE_RATE_012 "Detected object range rate";
BA_ "GenSigStartValue" SG_ 1537 MRR_RR_CAN_DET_RANGE_RATE_012 8192;
BA_ "GenSigCmt" SG_ 1537 MRR_RR_CAN_SCAN_INDEX_2LSB_012 "The two LSB of scan index";
BA_ "GenSigCmt" SG_ 1537 MRR_RR_CAN_DET_AMPLITUDE_012 "Detected object amplitude";
BA_ "GenSigStartValue" SG_ 1537 MRR_RR_CAN_DET_AMPLITUDE_012 64;
BA_ "GenSigCmt" SG_ 1537 MRR_RR_CAN_DET_VALID_LEVEL_012 "Detected object valid level";
BA_ "GenSigCmt" SG_ 1537 MRR_RR_CAN_DET_ELEVATION_011 "Detected object elevation position";
BA_ "GenSigStartValue" SG_ 1537 MRR_RR_CAN_DET_ELEVATION_011 63.8646288209607;
BA_ "GenSigCmt" SG_ 1537 MRR_RR_CAN_DET_SUPER_RES_TA_0010 "Super resolution target";
BA_ "SystemSignalLongSymbol" SG_ 1537 MRR_RR_CAN_DET_SUPER_RES_TA_0010 "MRR_RR_CAN_DET_SUPER_RES_TARGET_011";
BA_ "GenSigCmt" SG_ 1537 MRR_RR_CAN_DET_AZIMUTH_011 "Detected object azimuth position";
BA_ "GenSigStartValue" SG_ 1537 MRR_RR_CAN_DET_AZIMUTH_011 8194.05320813772;
BA_ "GenSigCmt" SG_ 1537 MRR_RR_CAN_DET_CONFID_ELEVA_0010 "Elevation Angle Confidence";
BA_ "SystemSignalLongSymbol" SG_ 1537 MRR_RR_CAN_DET_CONFID_ELEVA_0010 "MRR_RR_CAN_DET_CONFID_ELEVATION_011";
BA_ "GenSigCmt" SG_ 1537 MRR_RR_CAN_DET_HOST_VEH_CLU_0010 "Host vehicle clutter";
BA_ "SystemSignalLongSymbol" SG_ 1537 MRR_RR_CAN_DET_HOST_VEH_CLU_0010 "MRR_RR_CAN_DET_HOST_VEH_CLUTTER_011";
BA_ "GenSigCmt" SG_ 1537 MRR_RR_CAN_DET_RANGE_011 "Detected object range";
BA_ "GenSigVtEn" SG_ 1537 MRR_RR_CAN_DET_CONFID_AZIMU_0009 "TRUE";
BA_ "GenSigCmt" SG_ 1537 MRR_RR_CAN_DET_CONFID_AZIMU_0009 "Signal to noise level";
BA_ "SystemSignalLongSymbol" SG_ 1537 MRR_RR_CAN_DET_CONFID_AZIMU_0009 "MRR_RR_CAN_DET_CONFID_AZIMUTH_011";
BA_ "GenSigCmt" SG_ 1537 MRR_RR_CAN_DET_RANGE_RATE_011 "Detected object range rate";
BA_ "GenSigStartValue" SG_ 1537 MRR_RR_CAN_DET_RANGE_RATE_011 8192;
BA_ "GenSigCmt" SG_ 1537 MRR_RR_CAN_SCAN_INDEX_2LSB_011 "The two LSB of scan index";
BA_ "GenSigCmt" SG_ 1537 MRR_RR_CAN_DET_AMPLITUDE_011 "Detected object amplitude";
BA_ "GenSigStartValue" SG_ 1537 MRR_RR_CAN_DET_AMPLITUDE_011 64;
BA_ "GenSigCmt" SG_ 1537 MRR_RR_CAN_DET_VALID_LEVEL_011 "Detected object valid level";
BA_ "GenSigCmt" SG_ 1537 MRR_RR_CAN_DET_ELEVATION_010 "Detected object elevation position";
BA_ "GenSigStartValue" SG_ 1537 MRR_RR_CAN_DET_ELEVATION_010 63.8646288209607;
BA_ "GenSigCmt" SG_ 1537 MRR_RR_CAN_DET_SUPER_RES_TA_0011 "Super resolution target";
BA_ "SystemSignalLongSymbol" SG_ 1537 MRR_RR_CAN_DET_SUPER_RES_TA_0011 "MRR_RR_CAN_DET_SUPER_RES_TARGET_010";
BA_ "GenSigCmt" SG_ 1537 MRR_RR_CAN_DET_AZIMUTH_010 "Detected object azimuth position";
BA_ "GenSigStartValue" SG_ 1537 MRR_RR_CAN_DET_AZIMUTH_010 8194.05320813772;
BA_ "GenSigCmt" SG_ 1537 MRR_RR_CAN_DET_CONFID_ELEVA_0011 "Elevation Angle Confidence";
BA_ "SystemSignalLongSymbol" SG_ 1537 MRR_RR_CAN_DET_CONFID_ELEVA_0011 "MRR_RR_CAN_DET_CONFID_ELEVATION_010";
BA_ "GenSigCmt" SG_ 1537 MRR_RR_CAN_DET_HOST_VEH_CLU_0011 "Host vehicle clutter";
BA_ "SystemSignalLongSymbol" SG_ 1537 MRR_RR_CAN_DET_HOST_VEH_CLU_0011 "MRR_RR_CAN_DET_HOST_VEH_CLUTTER_010";
BA_ "GenSigCmt" SG_ 1537 MRR_RR_CAN_DET_RANGE_010 "Detected object range";
BA_ "GenSigVtEn" SG_ 1537 MRR_RR_CAN_DET_CONFID_AZIMU_0010 "TRUE";
BA_ "GenSigCmt" SG_ 1537 MRR_RR_CAN_DET_CONFID_AZIMU_0010 "Signal to noise level";
BA_ "SystemSignalLongSymbol" SG_ 1537 MRR_RR_CAN_DET_CONFID_AZIMU_0010 "MRR_RR_CAN_DET_CONFID_AZIMUTH_010";
BA_ "GenSigCmt" SG_ 1537 MRR_RR_CAN_DET_RANGE_RATE_010 "Detected object range rate";
BA_ "GenSigStartValue" SG_ 1537 MRR_RR_CAN_DET_RANGE_RATE_010 8192;
BA_ "GenSigCmt" SG_ 1537 MRR_RR_CAN_SCAN_INDEX_2LSB_010 "The two LSB of scan index";
BA_ "GenSigCmt" SG_ 1537 MRR_RR_CAN_DET_AMPLITUDE_010 "Detected object amplitude";
BA_ "GenSigStartValue" SG_ 1537 MRR_RR_CAN_DET_AMPLITUDE_010 64;
BA_ "GenSigCmt" SG_ 1537 MRR_RR_CAN_DET_VALID_LEVEL_010 "Detected object valid level";
BA_ "GenSigCmt" SG_ 1537 MRR_RR_CAN_DET_ELEVATION_009 "Detected object elevation position";
BA_ "GenSigStartValue" SG_ 1537 MRR_RR_CAN_DET_ELEVATION_009 63.8646288209607;
BA_ "GenSigCmt" SG_ 1537 MRR_RR_CAN_DET_SUPER_RES_TA_0012 "Super resolution target";
BA_ "SystemSignalLongSymbol" SG_ 1537 MRR_RR_CAN_DET_SUPER_RES_TA_0012 "MRR_RR_CAN_DET_SUPER_RES_TARGET_009";
BA_ "GenSigCmt" SG_ 1537 MRR_RR_CAN_DET_AZIMUTH_009 "Detected object azimuth position";
BA_ "GenSigStartValue" SG_ 1537 MRR_RR_CAN_DET_AZIMUTH_009 8194.05320813772;
BA_ "GenSigCmt" SG_ 1537 MRR_RR_CAN_DET_CONFID_ELEVA_0012 "Elevation Angle Confidence";
BA_ "SystemSignalLongSymbol" SG_ 1537 MRR_RR_CAN_DET_CONFID_ELEVA_0012 "MRR_RR_CAN_DET_CONFID_ELEVATION_009";
BA_ "GenSigCmt" SG_ 1537 MRR_RR_CAN_DET_HOST_VEH_CLU_0012 "Host vehicle clutter";
BA_ "SystemSignalLongSymbol" SG_ 1537 MRR_RR_CAN_DET_HOST_VEH_CLU_0012 "MRR_RR_CAN_DET_HOST_VEH_CLUTTER_009";
BA_ "GenSigCmt" SG_ 1537 MRR_RR_CAN_DET_RANGE_009 "Detected object range";
BA_ "GenSigVtEn" SG_ 1537 MRR_RR_CAN_DET_CONFID_AZIMU_0011 "TRUE";
BA_ "GenSigCmt" SG_ 1537 MRR_RR_CAN_DET_CONFID_AZIMU_0011 "Signal to noise level";
BA_ "SystemSignalLongSymbol" SG_ 1537 MRR_RR_CAN_DET_CONFID_AZIMU_0011 "MRR_RR_CAN_DET_CONFID_AZIMUTH_009";
BA_ "GenSigCmt" SG_ 1537 MRR_RR_CAN_DET_RANGE_RATE_009 "Detected object range rate";
BA_ "GenSigStartValue" SG_ 1537 MRR_RR_CAN_DET_RANGE_RATE_009 8192;
BA_ "GenSigCmt" SG_ 1537 MRR_RR_CAN_SCAN_INDEX_2LSB_009 "The two LSB of scan index";
BA_ "GenSigCmt" SG_ 1537 MRR_RR_CAN_DET_AMPLITUDE_009 "Detected object amplitude";
BA_ "GenSigStartValue" SG_ 1537 MRR_RR_CAN_DET_AMPLITUDE_009 64;
BA_ "GenSigCmt" SG_ 1537 MRR_RR_CAN_DET_VALID_LEVEL_009 "Detected object valid level";
BA_ "GenSigSendType" SG_ 1538 MRR_RR_CAN_DET_MID_TARGET_021 1;
BA_ "SignalDescription" SG_ 1538 MRR_RR_CAN_DET_MID_TARGET_021 "MID_Target_Discrimination";
BA_ "SignalDescription" SG_ 1538 MRR_RR_CAN_DET_MID_TARGET_020 "MID_Target_Discrimination";
BA_ "SignalDescription" SG_ 1538 MRR_RR_CAN_DET_MID_TARGET_019 "MID_Target_Discrimination";
BA_ "SignalDescription" SG_ 1538 MRR_RR_CAN_DET_MID_TARGET_018 "MID_Target_Discrimination";
BA_ "SignalDescription" SG_ 1538 MRR_RR_CAN_DET_MID_TARGET_017 "MID_Target_Discrimination";
BA_ "SignalDescription" SG_ 1538 MRR_RR_CAN_DET_MID_TARGET_016 "MID_Target_Discrimination";
BA_ "SignalDescription" SG_ 1538 MRR_RR_CAN_DET_MID_TARGET_015 "MID_Target_Discrimination";
BA_ "SignalDescription" SG_ 1538 MRR_RR_CAN_DET_Near_TARGET_015 "Near_Target_Discrimination";
BA_ "SignalDescription" SG_ 1538 MRR_RR_CAN_DET_Near_TARGET_016 "Near_Target_Discrimination";
BA_ "SignalDescription" SG_ 1538 MRR_RR_CAN_DET_Near_TARGET_017 "Near_Target_Discrimination";
BA_ "SignalDescription" SG_ 1538 MRR_RR_CAN_DET_Near_TARGET_018 "Near_Target_Discrimination";
BA_ "SignalDescription" SG_ 1538 MRR_RR_CAN_DET_Near_TARGET_019 "Near_Target_Discrimination";
BA_ "SignalDescription" SG_ 1538 MRR_RR_CAN_DET_Near_TARGET_020 "Near_Target_Discrimination";
BA_ "SignalDescription" SG_ 1538 MRR_RR_CAN_DET_Near_TARGET_021 "Near_Target_Discrimination";
BA_ "GenSigCmt" SG_ 1538 MRR_RR_CAN_DET_ELEVATION_015 "Detected object elevation position";
BA_ "GenSigStartValue" SG_ 1538 MRR_RR_CAN_DET_ELEVATION_015 63.8646288209607;
BA_ "GenSigVtEn" SG_ 1538 MRR_RR_CAN_DET_CONFID_AZIMU_0012 "TRUE";
BA_ "GenSigCmt" SG_ 1538 MRR_RR_CAN_DET_CONFID_AZIMU_0012 "Signal to noise level";
BA_ "SystemSignalLongSymbol" SG_ 1538 MRR_RR_CAN_DET_CONFID_AZIMU_0012 "MRR_RR_CAN_DET_CONFID_AZIMUTH_015";
BA_ "GenSigCmt" SG_ 1538 MRR_RR_CAN_DET_SUPER_RES_TA_0013 "Super resolution target";
BA_ "SystemSignalLongSymbol" SG_ 1538 MRR_RR_CAN_DET_SUPER_RES_TA_0013 "MRR_RR_CAN_DET_SUPER_RES_TARGET_015";
BA_ "GenSigCmt" SG_ 1538 MRR_RR_CAN_DET_CONFID_ELEVA_0013 "Elevation Angle Confidence";
BA_ "SystemSignalLongSymbol" SG_ 1538 MRR_RR_CAN_DET_CONFID_ELEVA_0013 "MRR_RR_CAN_DET_CONFID_ELEVATION_015";
BA_ "GenSigCmt" SG_ 1538 MRR_RR_CAN_DET_HOST_VEH_CLU_0013 "Host vehicle clutter";
BA_ "SystemSignalLongSymbol" SG_ 1538 MRR_RR_CAN_DET_HOST_VEH_CLU_0013 "MRR_RR_CAN_DET_HOST_VEH_CLUTTER_015";
BA_ "GenSigCmt" SG_ 1538 MRR_RR_CAN_DET_VALID_LEVEL_015 "Detected object valid level";
BA_ "GenSigCmt" SG_ 1538 MRR_RR_CAN_DET_AZIMUTH_015 "Detected object azimuth position";
BA_ "GenSigStartValue" SG_ 1538 MRR_RR_CAN_DET_AZIMUTH_015 8194.05320813772;
BA_ "GenSigCmt" SG_ 1538 MRR_RR_CAN_DET_RANGE_015 "Detected object range";
BA_ "GenSigCmt" SG_ 1538 MRR_RR_CAN_DET_RANGE_RATE_015 "Detected object range rate";
BA_ "GenSigStartValue" SG_ 1538 MRR_RR_CAN_DET_RANGE_RATE_015 8192;
BA_ "GenSigCmt" SG_ 1538 MRR_RR_CAN_DET_AMPLITUDE_015 "Detected object amplitude";
BA_ "GenSigStartValue" SG_ 1538 MRR_RR_CAN_DET_AMPLITUDE_015 64;
BA_ "GenSigCmt" SG_ 1538 MRR_RR_CAN_SCAN_INDEX_2LSB_015 "The two LSB of scan index";
BA_ "GenSigStartValue" SG_ 1538 MRR_RR_CAN_DET_ELEVATION_021 63.8646288209607;
BA_ "GenSigCmt" SG_ 1538 MRR_RR_CAN_DET_ELEVATION_021 "Detected object elevation position";
BA_ "GenSigCmt" SG_ 1538 MRR_RR_CAN_DET_SUPER_RES_TA_0014 "Super resolution target";
BA_ "SystemSignalLongSymbol" SG_ 1538 MRR_RR_CAN_DET_SUPER_RES_TA_0014 "MRR_RR_CAN_DET_SUPER_RES_TARGET_021";
BA_ "GenSigCmt" SG_ 1538 MRR_RR_CAN_DET_AZIMUTH_021 "Detected object azimuth position";
BA_ "GenSigStartValue" SG_ 1538 MRR_RR_CAN_DET_AZIMUTH_021 8194.05320813772;
BA_ "GenSigCmt" SG_ 1538 MRR_RR_CAN_DET_CONFID_ELEVA_0014 "Elevation Angle Confidence";
BA_ "SystemSignalLongSymbol" SG_ 1538 MRR_RR_CAN_DET_CONFID_ELEVA_0014 "MRR_RR_CAN_DET_CONFID_ELEVATION_021";
BA_ "GenSigCmt" SG_ 1538 MRR_RR_CAN_DET_HOST_VEH_CLU_0014 "Host vehicle clutter";
BA_ "SystemSignalLongSymbol" SG_ 1538 MRR_RR_CAN_DET_HOST_VEH_CLU_0014 "MRR_RR_CAN_DET_HOST_VEH_CLUTTER_021";
BA_ "GenSigCmt" SG_ 1538 MRR_RR_CAN_DET_RANGE_021 "Detected object range";
BA_ "GenSigVtEn" SG_ 1538 MRR_RR_CAN_DET_CONFID_AZIMUTH_02 "TRUE";
BA_ "GenSigCmt" SG_ 1538 MRR_RR_CAN_DET_CONFID_AZIMUTH_02 "Signal to noise level";
BA_ "SystemSignalLongSymbol" SG_ 1538 MRR_RR_CAN_DET_CONFID_AZIMUTH_02 "MRR_RR_CAN_DET_CONFID_AZIMUTH_021";
BA_ "GenSigCmt" SG_ 1538 MRR_RR_CAN_DET_RANGE_RATE_021 "Detected object range rate";
BA_ "GenSigStartValue" SG_ 1538 MRR_RR_CAN_DET_RANGE_RATE_021 8192;
BA_ "GenSigCmt" SG_ 1538 MRR_RR_CAN_SCAN_INDEX_2LSB_021 "The two LSB of scan index";
BA_ "GenSigCmt" SG_ 1538 MRR_RR_CAN_DET_AMPLITUDE_021 "Detected object amplitude";
BA_ "GenSigStartValue" SG_ 1538 MRR_RR_CAN_DET_AMPLITUDE_021 64;
BA_ "GenSigCmt" SG_ 1538 MRR_RR_CAN_DET_VALID_LEVEL_021 "Detected object valid level";
BA_ "GenSigCmt" SG_ 1538 MRR_RR_CAN_DET_ELEVATION_020 "Detected object elevation position";
BA_ "GenSigStartValue" SG_ 1538 MRR_RR_CAN_DET_ELEVATION_020 63.8646288209607;
BA_ "GenSigCmt" SG_ 1538 MRR_RR_CAN_DET_SUPER_RES_TA_0015 "Super resolution target";
BA_ "SystemSignalLongSymbol" SG_ 1538 MRR_RR_CAN_DET_SUPER_RES_TA_0015 "MRR_RR_CAN_DET_SUPER_RES_TARGET_020";
BA_ "GenSigCmt" SG_ 1538 MRR_RR_CAN_DET_AZIMUTH_020 "Detected object azimuth position";
BA_ "GenSigStartValue" SG_ 1538 MRR_RR_CAN_DET_AZIMUTH_020 8194.05320813772;
BA_ "GenSigCmt" SG_ 1538 MRR_RR_CAN_DET_CONFID_ELEVA_0015 "Elevation Angle Confidence";
BA_ "SystemSignalLongSymbol" SG_ 1538 MRR_RR_CAN_DET_CONFID_ELEVA_0015 "MRR_RR_CAN_DET_CONFID_ELEVATION_020";
BA_ "GenSigCmt" SG_ 1538 MRR_RR_CAN_DET_HOST_VEH_CLU_0015 "Host vehicle clutter";
BA_ "SystemSignalLongSymbol" SG_ 1538 MRR_RR_CAN_DET_HOST_VEH_CLU_0015 "MRR_RR_CAN_DET_HOST_VEH_CLUTTER_020";
BA_ "GenSigCmt" SG_ 1538 MRR_RR_CAN_DET_RANGE_020 "Detected object range";
BA_ "GenSigVtEn" SG_ 1538 MRR_RR_CAN_DET_CONFID_AZIMU_0013 "TRUE";
BA_ "GenSigCmt" SG_ 1538 MRR_RR_CAN_DET_CONFID_AZIMU_0013 "Signal to noise level";
BA_ "SystemSignalLongSymbol" SG_ 1538 MRR_RR_CAN_DET_CONFID_AZIMU_0013 "MRR_RR_CAN_DET_CONFID_AZIMUTH_020";
BA_ "GenSigCmt" SG_ 1538 MRR_RR_CAN_DET_RANGE_RATE_020 "Detected object range rate";
BA_ "GenSigStartValue" SG_ 1538 MRR_RR_CAN_DET_RANGE_RATE_020 8192;
BA_ "GenSigCmt" SG_ 1538 MRR_RR_CAN_SCAN_INDEX_2LSB_020 "The two LSB of scan index";
BA_ "GenSigCmt" SG_ 1538 MRR_RR_CAN_DET_AMPLITUDE_020 "Detected object amplitude";
BA_ "GenSigStartValue" SG_ 1538 MRR_RR_CAN_DET_AMPLITUDE_020 64;
BA_ "GenSigCmt" SG_ 1538 MRR_RR_CAN_DET_VALID_LEVEL_020 "Detected object valid level";
BA_ "GenSigCmt" SG_ 1538 MRR_RR_CAN_DET_ELEVATION_019 "Detected object elevation position";
BA_ "GenSigStartValue" SG_ 1538 MRR_RR_CAN_DET_ELEVATION_019 63.8646288209607;
BA_ "GenSigCmt" SG_ 1538 MRR_RR_CAN_DET_SUPER_RES_TA_0016 "Super resolution target";
BA_ "SystemSignalLongSymbol" SG_ 1538 MRR_RR_CAN_DET_SUPER_RES_TA_0016 "MRR_RR_CAN_DET_SUPER_RES_TARGET_019";
BA_ "GenSigCmt" SG_ 1538 MRR_RR_CAN_DET_AZIMUTH_019 "Detected object azimuth position";
BA_ "GenSigStartValue" SG_ 1538 MRR_RR_CAN_DET_AZIMUTH_019 8194.05320813772;
BA_ "GenSigCmt" SG_ 1538 MRR_RR_CAN_DET_CONFID_ELEVA_0016 "Elevation Angle Confidence";
BA_ "SystemSignalLongSymbol" SG_ 1538 MRR_RR_CAN_DET_CONFID_ELEVA_0016 "MRR_RR_CAN_DET_CONFID_ELEVATION_019";
BA_ "GenSigCmt" SG_ 1538 MRR_RR_CAN_DET_HOST_VEH_CLU_0016 "Host vehicle clutter";
BA_ "SystemSignalLongSymbol" SG_ 1538 MRR_RR_CAN_DET_HOST_VEH_CLU_0016 "MRR_RR_CAN_DET_HOST_VEH_CLUTTER_019";
BA_ "GenSigCmt" SG_ 1538 MRR_RR_CAN_DET_RANGE_019 "Detected object range";
BA_ "GenSigVtEn" SG_ 1538 MRR_RR_CAN_DET_CONFID_AZIMU_0014 "TRUE";
BA_ "GenSigCmt" SG_ 1538 MRR_RR_CAN_DET_CONFID_AZIMU_0014 "Signal to noise level";
BA_ "SystemSignalLongSymbol" SG_ 1538 MRR_RR_CAN_DET_CONFID_AZIMU_0014 "MRR_RR_CAN_DET_CONFID_AZIMUTH_019";
BA_ "GenSigCmt" SG_ 1538 MRR_RR_CAN_DET_RANGE_RATE_019 "Detected object range rate";
BA_ "GenSigStartValue" SG_ 1538 MRR_RR_CAN_DET_RANGE_RATE_019 8192;
BA_ "GenSigCmt" SG_ 1538 MRR_RR_CAN_SCAN_INDEX_2LSB_019 "The two LSB of scan index";
BA_ "GenSigCmt" SG_ 1538 MRR_RR_CAN_DET_AMPLITUDE_019 "Detected object amplitude";
BA_ "GenSigStartValue" SG_ 1538 MRR_RR_CAN_DET_AMPLITUDE_019 64;
BA_ "GenSigCmt" SG_ 1538 MRR_RR_CAN_DET_VALID_LEVEL_019 "Detected object valid level";
BA_ "GenSigCmt" SG_ 1538 MRR_RR_CAN_DET_ELEVATION_018 "Detected object elevation position";
BA_ "GenSigStartValue" SG_ 1538 MRR_RR_CAN_DET_ELEVATION_018 63.8646288209607;
BA_ "GenSigCmt" SG_ 1538 MRR_RR_CAN_DET_SUPER_RES_TA_0017 "Super resolution target";
BA_ "SystemSignalLongSymbol" SG_ 1538 MRR_RR_CAN_DET_SUPER_RES_TA_0017 "MRR_RR_CAN_DET_SUPER_RES_TARGET_018";
BA_ "GenSigCmt" SG_ 1538 MRR_RR_CAN_DET_AZIMUTH_018 "Detected object azimuth position";
BA_ "GenSigStartValue" SG_ 1538 MRR_RR_CAN_DET_AZIMUTH_018 8194.05320813772;
BA_ "GenSigCmt" SG_ 1538 MRR_RR_CAN_DET_CONFID_ELEVA_0017 "Elevation Angle Confidence";
BA_ "SystemSignalLongSymbol" SG_ 1538 MRR_RR_CAN_DET_CONFID_ELEVA_0017 "MRR_RR_CAN_DET_CONFID_ELEVATION_018";
BA_ "GenSigCmt" SG_ 1538 MRR_RR_CAN_DET_HOST_VEH_CLU_0017 "Host vehicle clutter";
BA_ "SystemSignalLongSymbol" SG_ 1538 MRR_RR_CAN_DET_HOST_VEH_CLU_0017 "MRR_RR_CAN_DET_HOST_VEH_CLUTTER_018";
BA_ "GenSigCmt" SG_ 1538 MRR_RR_CAN_DET_RANGE_018 "Detected object range";
BA_ "GenSigVtEn" SG_ 1538 MRR_RR_CAN_DET_CONFID_AZIMU_0015 "TRUE";
BA_ "GenSigCmt" SG_ 1538 MRR_RR_CAN_DET_CONFID_AZIMU_0015 "Signal to noise level";
BA_ "SystemSignalLongSymbol" SG_ 1538 MRR_RR_CAN_DET_CONFID_AZIMU_0015 "MRR_RR_CAN_DET_CONFID_AZIMUTH_018";
BA_ "GenSigCmt" SG_ 1538 MRR_RR_CAN_DET_RANGE_RATE_018 "Detected object range rate";
BA_ "GenSigStartValue" SG_ 1538 MRR_RR_CAN_DET_RANGE_RATE_018 8192;
BA_ "GenSigCmt" SG_ 1538 MRR_RR_CAN_SCAN_INDEX_2LSB_018 "The two LSB of scan index";
BA_ "GenSigCmt" SG_ 1538 MRR_RR_CAN_DET_AMPLITUDE_018 "Detected object amplitude";
BA_ "GenSigStartValue" SG_ 1538 MRR_RR_CAN_DET_AMPLITUDE_018 64;
BA_ "GenSigCmt" SG_ 1538 MRR_RR_CAN_DET_VALID_LEVEL_018 "Detected object valid level";
BA_ "GenSigCmt" SG_ 1538 MRR_RR_CAN_DET_ELEVATION_017 "Detected object elevation position";
BA_ "GenSigStartValue" SG_ 1538 MRR_RR_CAN_DET_ELEVATION_017 63.8646288209607;
BA_ "GenSigCmt" SG_ 1538 MRR_RR_CAN_DET_SUPER_RES_TA_0018 "Super resolution target";
BA_ "SystemSignalLongSymbol" SG_ 1538 MRR_RR_CAN_DET_SUPER_RES_TA_0018 "MRR_RR_CAN_DET_SUPER_RES_TARGET_017";
BA_ "GenSigCmt" SG_ 1538 MRR_RR_CAN_DET_AZIMUTH_017 "Detected object azimuth position";
BA_ "GenSigStartValue" SG_ 1538 MRR_RR_CAN_DET_AZIMUTH_017 8194.05320813772;
BA_ "GenSigCmt" SG_ 1538 MRR_RR_CAN_DET_CONFID_ELEVA_0018 "Elevation Angle Confidence";
BA_ "SystemSignalLongSymbol" SG_ 1538 MRR_RR_CAN_DET_CONFID_ELEVA_0018 "MRR_RR_CAN_DET_CONFID_ELEVATION_017";
BA_ "GenSigCmt" SG_ 1538 MRR_RR_CAN_DET_HOST_VEH_CLU_0018 "Host vehicle clutter";
BA_ "SystemSignalLongSymbol" SG_ 1538 MRR_RR_CAN_DET_HOST_VEH_CLU_0018 "MRR_RR_CAN_DET_HOST_VEH_CLUTTER_017";
BA_ "GenSigCmt" SG_ 1538 MRR_RR_CAN_DET_RANGE_017 "Detected object range";
BA_ "GenSigVtEn" SG_ 1538 MRR_RR_CAN_DET_CONFID_AZIMU_0016 "TRUE";
BA_ "GenSigCmt" SG_ 1538 MRR_RR_CAN_DET_CONFID_AZIMU_0016 "Signal to noise level";
BA_ "SystemSignalLongSymbol" SG_ 1538 MRR_RR_CAN_DET_CONFID_AZIMU_0016 "MRR_RR_CAN_DET_CONFID_AZIMUTH_017";
BA_ "GenSigCmt" SG_ 1538 MRR_RR_CAN_DET_RANGE_RATE_017 "Detected object range rate";
BA_ "GenSigStartValue" SG_ 1538 MRR_RR_CAN_DET_RANGE_RATE_017 8192;
BA_ "GenSigCmt" SG_ 1538 MRR_RR_CAN_SCAN_INDEX_2LSB_017 "The two LSB of scan index";
BA_ "GenSigCmt" SG_ 1538 MRR_RR_CAN_DET_AMPLITUDE_017 "Detected object amplitude";
BA_ "GenSigStartValue" SG_ 1538 MRR_RR_CAN_DET_AMPLITUDE_017 64;
BA_ "GenSigCmt" SG_ 1538 MRR_RR_CAN_DET_VALID_LEVEL_017 "Detected object valid level";
BA_ "GenSigCmt" SG_ 1538 MRR_RR_CAN_DET_ELEVATION_016 "Detected object elevation position";
BA_ "GenSigStartValue" SG_ 1538 MRR_RR_CAN_DET_ELEVATION_016 63.8646288209607;
BA_ "GenSigCmt" SG_ 1538 MRR_RR_CAN_DET_SUPER_RES_TA_0019 "Super resolution target";
BA_ "SystemSignalLongSymbol" SG_ 1538 MRR_RR_CAN_DET_SUPER_RES_TA_0019 "MRR_RR_CAN_DET_SUPER_RES_TARGET_016";
BA_ "GenSigCmt" SG_ 1538 MRR_RR_CAN_DET_AZIMUTH_016 "Detected object azimuth position";
BA_ "GenSigStartValue" SG_ 1538 MRR_RR_CAN_DET_AZIMUTH_016 8194.05320813772;
BA_ "GenSigCmt" SG_ 1538 MRR_RR_CAN_DET_CONFID_ELEVA_0019 "Elevation Angle Confidence";
BA_ "SystemSignalLongSymbol" SG_ 1538 MRR_RR_CAN_DET_CONFID_ELEVA_0019 "MRR_RR_CAN_DET_CONFID_ELEVATION_016";
BA_ "GenSigCmt" SG_ 1538 MRR_RR_CAN_DET_HOST_VEH_CLU_0019 "Host vehicle clutter";
BA_ "SystemSignalLongSymbol" SG_ 1538 MRR_RR_CAN_DET_HOST_VEH_CLU_0019 "MRR_RR_CAN_DET_HOST_VEH_CLUTTER_016";
BA_ "GenSigCmt" SG_ 1538 MRR_RR_CAN_DET_RANGE_016 "Detected object range";
BA_ "GenSigVtEn" SG_ 1538 MRR_RR_CAN_DET_CONFID_AZIMU_0017 "TRUE";
BA_ "GenSigCmt" SG_ 1538 MRR_RR_CAN_DET_CONFID_AZIMU_0017 "Signal to noise level";
BA_ "SystemSignalLongSymbol" SG_ 1538 MRR_RR_CAN_DET_CONFID_AZIMU_0017 "MRR_RR_CAN_DET_CONFID_AZIMUTH_016";
BA_ "GenSigCmt" SG_ 1538 MRR_RR_CAN_DET_RANGE_RATE_016 "Detected object range rate";
BA_ "GenSigStartValue" SG_ 1538 MRR_RR_CAN_DET_RANGE_RATE_016 8192;
BA_ "GenSigCmt" SG_ 1538 MRR_RR_CAN_SCAN_INDEX_2LSB_016 "The two LSB of scan index";
BA_ "GenSigCmt" SG_ 1538 MRR_RR_CAN_DET_AMPLITUDE_016 "Detected object amplitude";
BA_ "GenSigStartValue" SG_ 1538 MRR_RR_CAN_DET_AMPLITUDE_016 64;
BA_ "GenSigCmt" SG_ 1538 MRR_RR_CAN_DET_VALID_LEVEL_016 "Detected object valid level";
VAL_ 75 LRRF1_CAN_DET_CONFID_AZIMUTH_08 3 "Low" 2 "Medium_Low" 1 "Medium_High" 0 "High" ;
VAL_ 75 LRRF1_CAN_DET_CONFID_AZIMUTH_14 3 "Low" 2 "Medium_Low" 1 "Medium_High" 0 "High" ;
VAL_ 75 LRRF1_CAN_DET_CONFID_AZIMUTH_13 3 "Low" 2 "Medium_Low" 1 "Medium_High" 0 "High" ;
VAL_ 75 LRRF1_CAN_DET_CONFID_AZIMUTH_12 3 "Low" 2 "Medium_Low" 1 "Medium_High" 0 "High" ;
VAL_ 75 LRRF1_CAN_DET_CONFID_AZIMUTH_11 3 "Low" 2 "Medium_Low" 1 "Medium_High" 0 "High" ;
VAL_ 75 LRRF1_CAN_DET_CONFID_AZIMUTH_10 3 "Low" 2 "Medium_Low" 1 "Medium_High" 0 "High" ;
VAL_ 75 LRRF1_CAN_DET_CONFID_AZIMUTH_09 3 "Low" 2 "Medium_Low" 1 "Medium_High" 0 "High" ;
VAL_ 74 LRRF1_CAN_DET_CONFID_AZIMUTH_01 3 "Low" 2 "Medium_Low" 1 "Medium_High" 0 "High" ;
VAL_ 74 LRRF1_CAN_DET_CONFID_AZIMUTH_07 3 "Low" 2 "Medium_Low" 1 "Medium_High" 0 "High" ;
VAL_ 74 LRRF1_CAN_DET_CONFID_AZIMUTH_06 3 "Low" 2 "Medium_Low" 1 "Medium_High" 0 "High" ;
VAL_ 74 LRRF1_CAN_DET_CONFID_AZIMUTH_05 3 "Low" 2 "Medium_Low" 1 "Medium_High" 0 "High" ;
VAL_ 74 LRRF1_CAN_DET_CONFID_AZIMUTH_04 3 "Low" 2 "Medium_Low" 1 "Medium_High" 0 "High" ;
VAL_ 74 LRRF1_CAN_DET_CONFID_AZIMUTH_03 3 "Low" 2 "Medium_Low" 1 "Medium_High" 0 "High" ;
VAL_ 74 LRRF1_CAN_DET_CONFID_AZIMUTH_02 3 "Low" 2 "Medium_Low" 1 "Medium_High" 0 "High" ;
VAL_ 65 LRRF1_System_Operation_Mode_Stat 2 "RADIATE_ON" 1 "RADIATE_OFF" 0 "INIT" ;
VAL_ 65 LRRF1_CAN_BLOCKAGE_COMPLETE 1 "Complete" 0 "Not Complete" ;
VAL_ 65 RadarAlignment_FA_SER_Incomplete 1 "Alignment Incomplete" 0 "Alignment Completed" ;
VAL_ 65 RadarBlockageSidelobe_LRRF 1 "Radar Blockage" 0 "No Radar Blockage" ;
VAL_ 65 LRRF1_CAN_BLOCKAGE_MNR 1 "Detected" 0 "Not Detected" ;
VAL_ 65 RadarExternalConditionsNotOK_LRR 1 "Too high temp or insufficient pw" 0 "External conditions OK" ;
VAL_ 65 RadarAlignment_FA_SER_OutOfRange 1 "Radar out of range" 0 "Radar within range" ;
VAL_ 65 RadarAlignment_FA_SER_NotStarted 1 "Radar align not started" 0 "Radar align started" ;
VAL_ 65 RadarSensorNotOperational_LRRF 1 "Radar not operational" 0 "Radar operational" ;
VAL_ 267 MRR_RR_Horizontal_Alignment_Stat 15 "Undefined" 14 "Undefined" 13 "Low Amplitude (Flat-plate only)" 12 "No Peak (Flat-plate only)" 11 "Fail Ver and Hor OutOfRange" 10 "Fail Vertical Align OutOfRange" 9 "Fail Horizontal Align OutOfRange" 8 "Fail Time Out" 7 "Fail Only SODR Target Found" 6 "Fail Only SODL Target Found" 5 "Fail Variance Too Large" 4 "Fail Deviation Too Large" 3 "Fail No Target" 2 "Success" 1 "Busy" 0 "Off" ;
VAL_ 267 MRR_RR_Vertical_Alignment_Status 15 "Undefined" 14 "Undefined" 13 "Low Amplitude (Flat-plate only)" 12 "No Peak (Flat-plate only)" 11 "Fail Ver and Hor OutOfRange" 10 "Fail Vertical Align OutOfRange" 9 "Fail Horizontal Align OutOfRange" 8 "Fail Time Out" 7 "Fail Only SODR Target Found" 6 "Fail Only SODL Target Found" 5 "Fail Variance Too Large" 4 "Fail Deviation Too Large" 3 "Fail No Target" 2 "Success" 1 "Busy" 0 "Off" ;
VAL_ 267 MRR_RR_Vertical_Alignment_State 6 "Static alignment flat-plate" 5 "Static alignment 2-target" 4 "Static alignment 1-target" 3 "Service alignment" 2 "Short track alignment" 1 "Auto alignment" 0 "Off" ;
VAL_ 267 MRR_RR_Horizontal_Alignment_0000 6 "Static alignment flat-plate" 5 "Static alignment 2-target" 4 "Static alignment 1-target" 3 "Service alignment" 2 "Short track alignment" 1 "Auto alignment" 0 "Off" ;
VAL_ 267 MRR_RR_Align_Vertical_QF 3 "Accurate" 2 "Innacurate" 1 "Temporarily undefined (Faulty)" 0 "Undefined" ;
VAL_ 267 MRR_RR_Align_Horizontal_QF 3 "Accurate" 2 "Innacurate" 1 "Temporarily undefined (Faulty)" 0 "Undefined" ;
VAL_ 258 MRR_RR_CAN_TX_SW_VERSION_DSP 71426 "2.23.1" 71170 "2.22.1" 5890 "2.23" ;
VAL_ 258 MRR_RR_CAN_TX_SW_VERSION_ARM 66827 "1.5.11" 66826 "1.5.10" ;
VAL_ 261 MRR_RR_Dolphin_Fault_Detection 2 "Dolphin Sensor Dead" 1 "Dolphin Start_up Error" 0 "No Faults" ;
VAL_ 264 MRR_CAN_RadarWaveform_RR 4 "Unused" 3 "AutoHitch" 2 "Standard_Rear" 1 "Standard_Front" 0 "Unknown" ;
VAL_ 1536 MRR_RR_CAN_DET_CONFID_AZIMUTH_00 3 "Low" 2 "MidLow" 1 "MidHigh" 0 "High" ;
VAL_ 1536 MRR_RR_CAN_DET_CONFID_AZIMU_0000 3 "Low" 2 "MidLow" 1 "MidHigh" 0 "High" ;
VAL_ 1536 MRR_RR_CAN_DET_CONFID_AZIMU_0001 3 "Low" 2 "MidLow" 1 "MidHigh" 0 "High" ;
VAL_ 1536 MRR_RR_CAN_DET_CONFID_AZIMU_0002 3 "Low" 2 "MidLow" 1 "MidHigh" 0 "High" ;
VAL_ 1536 MRR_RR_CAN_DET_CONFID_AZIMU_0003 3 "Low" 2 "MidLow" 1 "MidHigh" 0 "High" ;
VAL_ 1536 MRR_RR_CAN_DET_CONFID_AZIMU_0004 3 "Low" 2 "MidLow" 1 "MidHigh" 0 "High" ;
VAL_ 1536 MRR_RR_CAN_DET_CONFID_AZIMU_0005 3 "Low" 2 "MidLow" 1 "MidHigh" 0 "High" ;
VAL_ 1537 MRR_RR_CAN_DET_CONFID_AZIMU_0006 3 "Low" 2 "MidLow" 1 "MidHigh" 0 "High" ;
VAL_ 1537 MRR_RR_CAN_DET_CONFID_AZIMUTH_01 3 "Low" 2 "MidLow" 1 "MidHigh" 0 "High" ;
VAL_ 1537 MRR_RR_CAN_DET_CONFID_AZIMU_0007 3 "Low" 2 "MidLow" 1 "MidHigh" 0 "High" ;
VAL_ 1537 MRR_RR_CAN_DET_CONFID_AZIMU_0008 3 "Low" 2 "MidLow" 1 "MidHigh" 0 "High" ;
VAL_ 1537 MRR_RR_CAN_DET_CONFID_AZIMU_0009 3 "Low" 2 "MidLow" 1 "MidHigh" 0 "High" ;
VAL_ 1537 MRR_RR_CAN_DET_CONFID_AZIMU_0010 3 "Low" 2 "MidLow" 1 "MidHigh" 0 "High" ;
VAL_ 1537 MRR_RR_CAN_DET_CONFID_AZIMU_0011 3 "Low" 2 "MidLow" 1 "MidHigh" 0 "High" ;
VAL_ 1538 MRR_RR_CAN_DET_CONFID_AZIMU_0012 3 "Low" 2 "MidLow" 1 "MidHigh" 0 "High" ;
VAL_ 1538 MRR_RR_CAN_DET_CONFID_AZIMUTH_02 3 "Low" 2 "MidLow" 1 "MidHigh" 0 "High" ;
VAL_ 1538 MRR_RR_CAN_DET_CONFID_AZIMU_0013 3 "Low" 2 "MidLow" 1 "MidHigh" 0 "High" ;
VAL_ 1538 MRR_RR_CAN_DET_CONFID_AZIMU_0014 3 "Low" 2 "MidLow" 1 "MidHigh" 0 "High" ;
VAL_ 1538 MRR_RR_CAN_DET_CONFID_AZIMU_0015 3 "Low" 2 "MidLow" 1 "MidHigh" 0 "High" ;
VAL_ 1538 MRR_RR_CAN_DET_CONFID_AZIMU_0016 3 "Low" 2 "MidLow" 1 "MidHigh" 0 "High" ;
VAL_ 1538 MRR_RR_CAN_DET_CONFID_AZIMU_0017 3 "Low" 2 "MidLow" 1 "MidHigh" 0 "High" ;
SIG_GROUP_ 75 LRRF1_Detection_008_014 1 : LRRF1_CAN_DET_Near_TARGET_14 LRRF1_CAN_DET_Near_TARGET_13 LRRF1_CAN_DET_Near_TARGET_12 LRRF1_CAN_DET_Near_TARGET_11 LRRF1_CAN_DET_Near_TARGET_10 LRRF1_CAN_DET_Near_TARGET_09 LRRF1_CAN_DET_Near_TARGET_08 LRRF1_CAN_DET_ELEVATION_08 LRRF1_CAN_DET_CONFID_AZIMUTH_08 LRRF1_CAN_DET_SUPER_RES_TARGET_0 LRRF1_CAN_DET_AZIMUTH_08 LRRF1_CAN_DET_SUPER_RES_TAR_0108 LRRF1_CAN_DET_CONFID_ELEVATION_0 LRRF1_CAN_DET_VALID_LEVEL_10 LRRF1_CAN_DET_HOST_VEH_CLUTTER_0 LRRF1_CAN_DET_RANGE_08 LRRF1_CAN_DET_VALID_LEVEL_08 LRRF1_CAN_DET_VALID_LEVEL_09 LRRF1_CAN_DET_RANGE_RATE_08 LRRF1_Det_CRC_02 LRRF1_CAN_DET_VALID_LEVEL_11 LRRF1_CAN_DET_AMPLITUDE_08 LRRF1_CAN_DET_RANGE_RATE_13 LRRF1_CAN_DET_CONFID_AZIMUTH_14 LRRF1_CAN_DET_HOST_VEH_CLUT_0105 LRRF1_CAN_DET_CONFID_ELEVAT_0106 LRRF1_CAN_DET_VALID_LEVEL_14 LRRF1_CAN_DET_CONFID_ELEVAT_0108 LRRF1_CAN_DET_CONFID_ELEVAT_0110 LRRF1_CAN_DET_CONFID_ELEVAT_0105 LRRF1_CAN_DET_AMPLITUDE_12 LRRF1_CAN_DET_AZIMUTH_13 LRRF1_CAN_DET_AMPLITUDE_14 LRRF1_CAN_DET_AMPLITUDE_09 LRRF1_CAN_DET_AMPLITUDE_11 LRRF1_CAN_DET_VALID_LEVEL_13 LRRF1_CAN_DET_CONFID_AZIMUTH_10 LRRF1_CAN_DET_CONFID_AZIMUTH_09 LRRF1_CAN_DET_AMPLITUDE_13 LRRF1_CAN_DET_AZIMUTH_09 LRRF1_CAN_DET_AZIMUTH_10 LRRF1_CAN_DET_CONFID_AZIMUTH_12 LRRF1_CAN_DET_CONFID_AZIMUTH_11 LRRF1_CAN_DET_AMPLITUDE_10 LRRF1_CAN_DET_HOST_VEH_CLUT_0107 LRRF1_CAN_DET_ELEVATION_13 LRRF1_CAN_DET_HOST_VEH_CLUT_0106 LRRF1_CAN_SCAN_INDEX_2LSB_14 LRRF1_Det_MC_02 LRRF1_CAN_DET_CONFID_ELEVAT_0107 LRRF1_CAN_DET_ELEVATION_12 LRRF1_CAN_DET_ELEVATION_11 LRRF1_CAN_DET_ELEVATION_09 LRRF1_CAN_DET_ELEVATION_10 LRRF1_CAN_DET_ELEVATION_14 LRRF1_CAN_DET_HOST_VEH_CLUT_0110 LRRF1_CAN_DET_HOST_VEH_CLUT_0109 LRRF1_CAN_DET_CONFID_ELEVAT_0109 LRRF1_CAN_DET_SUPER_RES_TAR_0110 LRRF1_CAN_DET_AZIMUTH_12 LRRF1_CAN_DET_SUPER_RES_TAR_0109 LRRF1_CAN_DET_RANGE_14 LRRF1_CAN_DET_SUPER_RES_TAR_0107 LRRF1_CAN_DET_CONFID_AZIMUTH_13 LRRF1_CAN_SCAN_INDEX_2LSB_08 LRRF1_CAN_SCAN_INDEX_2LSB_13 LRRF1_CAN_SCAN_INDEX_2LSB_11 LRRF1_CAN_SCAN_INDEX_2LSB_12 LRRF1_CAN_SCAN_INDEX_2LSB_10 LRRF1_CAN_SCAN_INDEX_2LSB_09 LRRF1_CAN_DET_RANGE_RATE_14 LRRF1_CAN_DET_AZIMUTH_11 LRRF1_CAN_DET_SUPER_RES_TAR_0106 LRRF1_CAN_DET_RANGE_RATE_12 LRRF1_CAN_DET_RANGE_RATE_09 LRRF1_CAN_DET_AZIMUTH_14 LRRF1_CAN_DET_SUPER_RES_TAR_0105 LRRF1_CAN_DET_HOST_VEH_CLUT_0108 LRRF1_CAN_DET_RANGE_09 LRRF1_CAN_DET_RANGE_10 LRRF1_CAN_DET_RANGE_11 LRRF1_CAN_DET_RANGE_12 LRRF1_CAN_DET_RANGE_13 LRRF1_CAN_DET_RANGE_RATE_10 LRRF1_CAN_DET_RANGE_RATE_11 LRRF1_CAN_DET_VALID_LEVEL_12;
SIG_GROUP_ 74 LRRF1_Detection_001_007 1 : LRRF1_CAN_DET_Near_TARGET_07 LRRF1_CAN_DET_Near_TARGET_06 LRRF1_CAN_DET_Near_TARGET_05 LRRF1_CAN_DET_Near_TARGET_04 LRRF1_CAN_DET_Near_TARGET_03 LRRF1_CAN_DET_Near_TARGET_02 LRRF1_CAN_DET_Near_TARGET_01 LRRF1_CAN_SCAN_INDEX_2LSB_07 LRRF1_CAN_DET_VALID_LEVEL_07 LRRF1_CAN_DET_SUPER_RES_TAR_0112 LRRF1_CAN_DET_RANGE_RATE_07 LRRF1_CAN_DET_RANGE_07 LRRF1_CAN_DET_HOST_VEH_CLUT_0112 LRRF1_CAN_DET_ELEVATION_07 LRRF1_CAN_DET_CONFID_ELEVAT_0112 LRRF1_CAN_DET_CONFID_AZIMUTH_07 LRRF1_CAN_DET_AZIMUTH_07 LRRF1_CAN_DET_AMPLITUDE_07 LRRF1_CAN_SCAN_INDEX_2LSB_06 LRRF1_CAN_DET_VALID_LEVEL_06 LRRF1_CAN_DET_SUPER_RES_TAR_0113 LRRF1_CAN_DET_RANGE_RATE_06 LRRF1_CAN_DET_RANGE_06 LRRF1_CAN_DET_HOST_VEH_CLUT_0113 LRRF1_CAN_DET_ELEVATION_06 LRRF1_CAN_DET_CONFID_ELEVAT_0113 LRRF1_CAN_DET_CONFID_AZIMUTH_06 LRRF1_CAN_DET_AZIMUTH_06 LRRF1_CAN_DET_AMPLITUDE_06 LRRF1_CAN_SCAN_INDEX_2LSB_05 LRRF1_CAN_DET_VALID_LEVEL_05 LRRF1_CAN_DET_SUPER_RES_TAR_0114 LRRF1_CAN_DET_RANGE_RATE_05 LRRF1_CAN_DET_RANGE_05 LRRF1_CAN_DET_HOST_VEH_CLUT_0114 LRRF1_CAN_DET_ELEVATION_05 LRRF1_CAN_DET_CONFID_ELEVAT_0114 LRRF1_CAN_DET_CONFID_AZIMUTH_05 LRRF1_CAN_DET_AZIMUTH_05 LRRF1_CAN_DET_AMPLITUDE_05 LRRF1_CAN_SCAN_INDEX_2LSB_04 LRRF1_CAN_DET_VALID_LEVEL_04 LRRF1_CAN_DET_SUPER_RES_TAR_0115 LRRF1_CAN_DET_RANGE_RATE_04 LRRF1_CAN_DET_RANGE_04 LRRF1_CAN_DET_HOST_VEH_CLUT_0115 LRRF1_CAN_DET_ELEVATION_04 LRRF1_CAN_DET_CONFID_ELEVAT_0115 LRRF1_CAN_DET_CONFID_AZIMUTH_04 LRRF1_CAN_DET_AZIMUTH_04 LRRF1_CAN_DET_AMPLITUDE_04 LRRF1_CAN_SCAN_INDEX_2LSB_03 LRRF1_CAN_DET_VALID_LEVEL_03 LRRF1_CAN_DET_SUPER_RES_TAR_0116 LRRF1_CAN_DET_RANGE_RATE_03 LRRF1_CAN_DET_RANGE_03 LRRF1_CAN_DET_HOST_VEH_CLUT_0116 LRRF1_CAN_DET_ELEVATION_03 LRRF1_CAN_DET_CONFID_ELEVAT_0116 LRRF1_CAN_DET_CONFID_AZIMUTH_03 LRRF1_CAN_DET_AZIMUTH_03 LRRF1_CAN_DET_AMPLITUDE_03 LRRF1_CAN_SCAN_INDEX_2LSB_02 LRRF1_CAN_DET_VALID_LEVEL_02 LRRF1_CAN_DET_SUPER_RES_TAR_0117 LRRF1_CAN_DET_RANGE_RATE_02 LRRF1_CAN_DET_RANGE_02 LRRF1_CAN_DET_HOST_VEH_CLUT_0117 LRRF1_CAN_DET_ELEVATION_02 LRRF1_CAN_DET_CONFID_ELEVAT_0117 LRRF1_CAN_DET_CONFID_AZIMUTH_02 LRRF1_CAN_DET_AZIMUTH_02 LRRF1_CAN_DET_AMPLITUDE_02 LRRF1_Det_CRC_01 LRRF1_Det_MC_01 LRRF1_CAN_DET_ELEVATION_01 LRRF1_CAN_DET_CONFID_AZIMUTH_01 LRRF1_CAN_DET_SUPER_RES_TAR_0111 LRRF1_CAN_DET_CONFID_ELEVAT_0111 LRRF1_CAN_DET_HOST_VEH_CLUT_0111 LRRF1_CAN_DET_VALID_LEVEL_01 LRRF1_CAN_DET_AZIMUTH_01 LRRF1_CAN_DET_RANGE_01 LRRF1_CAN_DET_RANGE_RATE_01 LRRF1_CAN_DET_AMPLITUDE_01 LRRF1_CAN_SCAN_INDEX_2LSB_01;
SIG_GROUP_ 65 LRRF1_Status_Radar 1 : LRRF1_System_Operation_Mode_Stat LRRF1_Status_Radar_CRC LRRF1_Status_Radar_MC LRRF1_CAN_Core1_Cpu_Load LRRF1_CAN_Core2_Cpu_Load LRRF1_CAN_Core0_Cpu_Load RadarBlockageSidelobe_LRRF RadarAlignment_FA_SER_Incomplete LRRF1_CAN_RECOMMEND_UNCONVERGE LRRF1_CAN_BLOCKAGE_COMPLETE LRRF1_CAN_RADAR_CommonModeFailur LRRF1_CAN_INTERFERENCE_TYPE LRRF1_CAN_BLKG_SIDELOBE_FILTER_V RadarAlignment_FA_SER_OutOfRange RadarExternalConditionsNotOK_LRR LRRF1_CAN_BLOCKAGE_MNR RadarAlignment_FA_SER_NotStarted LRRF1_CAN_RADAR_OVERHEAT_ERROR RadarSensorNotOperational_LRRF LRRF1_CAN_XCVR_OPERATIONAL;
SIG_GROUP_ 267 MRR_RR_Header_AlignmentState 1 : MRR_RR_CAN_HRZNTL_ALIGN_UPDATES_ MRR_RR_CAN_VRTCL_ALIGN_UPDATES_N MRR_RR_Header_AlignmentState_CRC MRR_RR_Header_AlignmentState_MC MRR_RR_Horizontal_Alignment_Stat MRR_RR_Vertical_Alignment_Status MRR_RR_Vertical_Alignment_State MRR_RR_Horizontal_Alignment_0000 MRR_RR_Align_Vertical_Ref MRR_RR_Align_Vertical_QF MRR_RR_Align_Vertical_Angle MRR_RR_Align_Horizontal_Angle MRR_RR_Align_Horizontal_Ref MRR_RR_Align_Horizontal_QF;
SIG_GROUP_ 260 MRR_RR_Active_Fault_Status 1 : MRR_RR_TO_SystemTDBlockage_Flt MRR_RR_TO_CADMSWVersion_Flt MRR_RR_TO_RADARCfgParameter_Flt MRR_RR_TO_SATCADMVIN_Flt MRR_RR_TO_CADMTracksChange_Flt MRR_RR_Active_Fault_Status_CRC MRR_RR_Active_Fault_Status_MC MRR_RR_Core1_To_Core0_IPC_Flt MRR_RR_Core2_To_Core0_IPC_Flt MRR_RR_v1p1_SupplyOutOfRange_Flt MRR_RR_PCANBusOff_Flt MRR_RR_StackOverflow_Flt MRR_RR_Watchdog_Flt MRR_RR_PLLLock_Flt MRR_RR_RAMMemoryTest_Flt MRR_RR_USCValidation_Flt MRR_RR_v2p3_SupplyOutOfRange_Flt MRR_RR_SMCChecksum_Flt MRR_RR_KeepAliveChecksum_Flt MRR_RR_TransmitterID_Flt MRR_RR_RRUCore_Flt MRR_RR_Dolphin_Flt MRR_RR_ApplicationFlashChksum_Fl MRR_RR_InstructionSetCheck_Flt MRR_RR_MNRBlockage_Flt MRR_RR_DSPLoopOverrun_Flt MRR_RR_Core0_To_Core2_IPC_Flt MRR_RR_XCVRDeviceSPI_Flt MRR_RR_HAlignOutofRange_Flt MRR_RR_AlignRoutineFailed_Flt MRR_RR_TransmitterPower_Flt MRR_RR_TransmitterTempHigh_Flt MRR_RR_v1p25_SupplyOutOfRange_Fl MRR_RR_v1p8_SupplyOutOfRange_Flt MRR_RR_MicroTempHigh_Flt MRR_RR_v_5_SupplyOutOfRange_Flt MRR_RR_CRC_CADMSgnlActlVal_Flt MRR_RR_VINSignalCompare_Flt MRR_RR_CRC_AngleAdjTable_Flt MRR_RR_PINPosition_Flt MRR_RR_RRUBIST_Flt MRR_RR_TO_CADMSgnlActlVal_Flt MRR_RR_PCANDataRangeChk_Flt MRR_RR_TO_TrigControl_Flt MRR_RR_TO_VehicleState_Flt MRR_RR_BatteryHigh_Flt MRR_RR_BatteryLow_Flt MRR_RR_Core0_To_Core1_IPC_Flt MRR_RR_Core1Halted_Flt MRR_RR_Core2Halted_Flt MRR_RR_Core2_To_Core1_IPC_Flt MRR_RR_Core1_To_Core2_IPC_Flt MRR_RR_LocalOscPower_Flt MRR_RR_MC_CADMSgnlActlVal_Flt MRR_RR_MC_AngleAdjTable_Flt MRR_RR_CRC_TrigControl_Flt MRR_RR_CRC_VehicleState_Flt MRR_RR_CRC_RadarCfgParameter_Flt MRR_RR_MC_TrigControl_Flt MRR_RR_MC_VehicleState_Flt MRR_RR_TO_AngleAdjustmentTable_F;
SIG_GROUP_ 259 MRR_RR_Alignment_Status 1 : MRR_RR_Alignment_Status_CRC MRR_RR_Alignment_Status_MC MRR_RR_CAN_TX_DRIVING_ENVIRONMEN MRR_RR_CAN_TX_Temperature MRR_RR_CAN_TX_ROLLING_COUNT_1 MRR_RR_CAN_TX_YAW_RATE_BIAS MRR_RR_CAN_TX_VEH_SPD_COMP_FACTO MRR_RR_CAN_TX_AUTO_ALIGN_QUA_FAC MRR_RR_CAN_TX_Alignment_MODE MRR_RR_CAN_TX_CURRENT_MISALIGN_A MRR_RR_CAN_TX_SAVED_MISALIGN_ANG;
SIG_GROUP_ 264 MRR_RR_Header_SensorCoverage 1 : MRR_RR_Radar_Spec_Status_CRC MRR_RR_Radar_Spec_Status_MC MRR_CAN_RadarWaveform_RR MRR_RR_CAN_RANGE_COVERAGE MRR_RR_CAN_DOPPLER_COVERAGE MRR_RR_CAN_FOV_HOR MRR_RR_CAN_FOV_VER;
SIG_GROUP_ 1536 MRR_RR_Detection_001_007 1 : MRR_RR_CAN_DET_Near_TARGET_001 MRR_RR_CAN_DET_Near_TARGET_002 MRR_RR_CAN_DET_Near_TARGET_003 MRR_RR_CAN_DET_Near_TARGET_004 MRR_RR_CAN_DET_Near_TARGET_005 MRR_RR_CAN_DET_Near_TARGET_006 MRR_RR_CAN_DET_Near_TARGET_007 MRR_RR_CAN_DET_MID_TARGET_001 MRR_RR_CAN_DET_MID_TARGET_002 MRR_RR_CAN_DET_MID_TARGET_003 MRR_RR_CAN_DET_MID_TARGET_004 MRR_RR_CAN_DET_MID_TARGET_005 MRR_RR_CAN_DET_MID_TARGET_006 MRR_RR_CAN_DET_MID_TARGET_007 MRR_RR_DET_MC_001 MRR_RR_DET_CRC_001 MRR_RR_CAN_DET_ELEVATION_007 MRR_RR_CAN_DET_AZIMUTH_001 MRR_RR_CAN_SCAN_INDEX_2LSB_001 MRR_RR_CAN_DET_SUPER_RES_TARGET_ MRR_RR_CAN_DET_AMPLITUDE_001 MRR_RR_CAN_DET_AZIMUTH_007 MRR_RR_CAN_DET_CONFID_ELEVATION_ MRR_RR_CAN_DET_ELEVATION_005 MRR_RR_CAN_DET_HOST_VEH_CLUTTER_ MRR_RR_CAN_DET_RANGE_007 MRR_RR_CAN_DET_CONFID_AZIMU_0005 MRR_RR_CAN_DET_AMPLITUDE_007 MRR_RR_CAN_DET_RANGE_RATE_001 MRR_RR_CAN_DET_RANGE_001 MRR_RR_CAN_DET_VALID_LEVEL_001 MRR_RR_CAN_DET_HOST_VEH_CLU_0005 MRR_RR_CAN_DET_RANGE_RATE_005 MRR_RR_CAN_DET_AZIMUTH_005 MRR_RR_CAN_DET_AMPLITUDE_002 MRR_RR_CAN_DET_CONFID_ELEVA_0003 MRR_RR_CAN_DET_SUPER_RES_TA_0005 MRR_RR_CAN_DET_HOST_VEH_CLU_0003 MRR_RR_CAN_DET_VALID_LEVEL_002 MRR_RR_CAN_DET_AMPLITUDE_005 MRR_RR_CAN_DET_CONFID_ELEVA_0004 MRR_RR_CAN_DET_CONFID_AZIMU_0004 MRR_RR_CAN_SCAN_INDEX_2LSB_002 MRR_RR_CAN_DET_RANGE_RATE_002 MRR_RR_CAN_DET_RANGE_002 MRR_RR_CAN_DET_ELEVATION_002 MRR_RR_CAN_DET_AZIMUTH_002 MRR_RR_CAN_DET_HOST_VEH_CLU_0004 MRR_RR_CAN_DET_RANGE_RATE_003 MRR_RR_CAN_SCAN_INDEX_2LSB_005 MRR_RR_CAN_DET_CONFID_AZIMU_0003 MRR_RR_CAN_DET_RANGE_003 MRR_RR_CAN_DET_RANGE_005 MRR_RR_CAN_DET_VALID_LEVEL_005 MRR_RR_CAN_DET_AZIMUTH_003 MRR_RR_CAN_DET_AMPLITUDE_004 MRR_RR_CAN_DET_CONFID_AZIMU_0001 MRR_RR_CAN_DET_CONFID_ELEVA_0005 MRR_RR_CAN_DET_ELEVATION_003 MRR_RR_CAN_DET_RANGE_RATE_004 MRR_RR_CAN_SCAN_INDEX_2LSB_004 MRR_RR_CAN_SCAN_INDEX_2LSB_003 MRR_RR_CAN_DET_RANGE_004 MRR_RR_CAN_DET_AZIMUTH_004 MRR_RR_CAN_DET_ELEVATION_004 MRR_RR_CAN_DET_VALID_LEVEL_003 MRR_RR_CAN_DET_HOST_VEH_CLU_0002 MRR_RR_CAN_DET_AMPLITUDE_003 MRR_RR_CAN_DET_CONFID_AZIMU_0002 MRR_RR_CAN_DET_CONFID_AZIMUTH_00 MRR_RR_CAN_DET_RANGE_RATE_007 MRR_RR_CAN_DET_VALID_LEVEL_007 MRR_RR_CAN_DET_CONFID_ELEVA_0000 MRR_RR_CAN_DET_ELEVATION_006 MRR_RR_CAN_DET_SUPER_RES_TA_0004 MRR_RR_CAN_DET_SUPER_RES_TA_0003 MRR_RR_CAN_DET_VALID_LEVEL_006 MRR_RR_CAN_DET_HOST_VEH_CLU_0001 MRR_RR_CAN_DET_SUPER_RES_TA_0001 MRR_RR_CAN_DET_CONFID_ELEVA_0001 MRR_RR_CAN_DET_ELEVATION_001 MRR_RR_CAN_DET_CONFID_ELEVA_0002 MRR_RR_CAN_DET_SUPER_RES_TA_0002 MRR_RR_CAN_DET_VALID_LEVEL_004 MRR_RR_CAN_DET_AZIMUTH_006 MRR_RR_CAN_DET_AMPLITUDE_006 MRR_RR_CAN_SCAN_INDEX_2LSB_006 MRR_RR_CAN_DET_RANGE_RATE_006 MRR_RR_CAN_DET_CONFID_AZIMU_0000 MRR_RR_CAN_DET_RANGE_006 MRR_RR_CAN_DET_HOST_VEH_CLU_0000 MRR_RR_CAN_DET_SUPER_RES_TA_0000 MRR_RR_CAN_SCAN_INDEX_2LSB_007;
SIG_GROUP_ 1537 MRR_RR_Detection_008_014 1 : MRR_RR_CAN_DET_Near_TARGET_014 MRR_RR_CAN_DET_Near_TARGET_013 MRR_RR_CAN_DET_Near_TARGET_012 MRR_RR_CAN_DET_Near_TARGET_011 MRR_RR_CAN_DET_Near_TARGET_010 MRR_RR_CAN_DET_Near_TARGET_009 MRR_RR_CAN_DET_Near_TARGET_008 MRR_RR_CAN_DET_MID_TARGET_008 MRR_RR_CAN_DET_MID_TARGET_009 MRR_RR_CAN_DET_MID_TARGET_010 MRR_RR_CAN_DET_MID_TARGET_011 MRR_RR_CAN_DET_MID_TARGET_012 MRR_RR_CAN_DET_MID_TARGET_013 MRR_RR_CAN_DET_MID_TARGET_014 MRR_RR_CAN_DET_ELEVATION_008 MRR_RR_CAN_DET_CONFID_AZIMU_0006 MRR_RR_CAN_DET_CONFID_ELEVA_0006 MRR_RR_CAN_DET_HOST_VEH_CLU_0006 MRR_RR_CAN_DET_VALID_LEVEL_008 MRR_RR_CAN_DET_AZIMUTH_008 MRR_RR_DET_MC_002 MRR_RR_DET_CRC_002 MRR_RR_CAN_DET_AZIMUTH_014 MRR_RR_CAN_DET_RANGE_013 MRR_RR_CAN_DET_VALID_LEVEL_013 MRR_RR_CAN_DET_ELEVATION_012 MRR_RR_CAN_SCAN_INDEX_2LSB_012 MRR_RR_CAN_SCAN_INDEX_2LSB_010 MRR_RR_CAN_DET_VALID_LEVEL_010 MRR_RR_CAN_DET_RANGE_RATE_009 MRR_RR_CAN_SCAN_INDEX_2LSB_009 MRR_RR_CAN_DET_AMPLITUDE_009 MRR_RR_CAN_DET_VALID_LEVEL_009 MRR_RR_CAN_DET_RANGE_009 MRR_RR_CAN_DET_AZIMUTH_009 MRR_RR_CAN_DET_CONFID_AZIMU_0011 MRR_RR_CAN_DET_CONFID_AZIMU_0009 MRR_RR_CAN_DET_ELEVATION_009 MRR_RR_CAN_DET_SUPER_RES_TA_0012 MRR_RR_CAN_DET_CONFID_ELEVA_0009 MRR_RR_CAN_DET_AMPLITUDE_012 MRR_RR_CAN_DET_CONFID_ELEVA_0012 MRR_RR_CAN_DET_VALID_LEVEL_012 MRR_RR_CAN_DET_CONFID_AZIMU_0010 MRR_RR_CAN_DET_RANGE_RATE_010 MRR_RR_CAN_DET_AMPLITUDE_010 MRR_RR_CAN_SCAN_INDEX_2LSB_011 MRR_RR_CAN_DET_SUPER_RES_TA_0011 MRR_RR_CAN_DET_RANGE_010 MRR_RR_CAN_DET_HOST_VEH_CLU_0011 MRR_RR_CAN_DET_CONFID_AZIMU_0008 MRR_RR_CAN_DET_RANGE_RATE_011 MRR_RR_CAN_DET_CONFID_ELEVA_0011 MRR_RR_CAN_DET_ELEVATION_010 MRR_RR_CAN_DET_HOST_VEH_CLU_0009 MRR_RR_CAN_DET_HOST_VEH_CLU_0010 MRR_RR_CAN_DET_AZIMUTH_012 MRR_RR_CAN_DET_RANGE_012 MRR_RR_CAN_DET_SUPER_RES_TA_0006 MRR_RR_CAN_DET_RANGE_008 MRR_RR_CAN_DET_AMPLITUDE_008 MRR_RR_CAN_DET_RANGE_RATE_008 MRR_RR_CAN_DET_HOST_VEH_CLU_0012 MRR_RR_CAN_DET_VALID_LEVEL_011 MRR_RR_CAN_DET_AZIMUTH_011 MRR_RR_CAN_SCAN_INDEX_2LSB_008 MRR_RR_CAN_DET_ELEVATION_014 MRR_RR_CAN_DET_RANGE_RATE_014 MRR_RR_CAN_DET_AMPLITUDE_011 MRR_RR_CAN_SCAN_INDEX_2LSB_014 MRR_RR_CAN_DET_CONFID_ELEVA_0010 MRR_RR_CAN_DET_CONFID_AZIMUTH_01 MRR_RR_CAN_DET_ELEVATION_011 MRR_RR_CAN_DET_RANGE_011 MRR_RR_CAN_DET_AZIMUTH_010 MRR_RR_CAN_DET_VALID_LEVEL_014 MRR_RR_CAN_DET_AMPLITUDE_014 MRR_RR_CAN_DET_ELEVATION_013 MRR_RR_CAN_DET_SUPER_RES_TA_0010 MRR_RR_CAN_SCAN_INDEX_2LSB_013 MRR_RR_CAN_DET_AMPLITUDE_013 MRR_RR_CAN_DET_SUPER_RES_TA_0008 MRR_RR_CAN_DET_SUPER_RES_TA_0009 MRR_RR_CAN_DET_AZIMUTH_013 MRR_RR_CAN_DET_CONFID_AZIMU_0007 MRR_RR_CAN_DET_HOST_VEH_CLU_0008 MRR_RR_CAN_DET_CONFID_ELEVA_0008 MRR_RR_CAN_DET_RANGE_RATE_012 MRR_RR_CAN_DET_RANGE_RATE_013 MRR_RR_CAN_DET_RANGE_014 MRR_RR_CAN_DET_HOST_VEH_CLU_0007 MRR_RR_CAN_DET_CONFID_ELEVA_0007 MRR_RR_CAN_DET_SUPER_RES_TA_0007;
SIG_GROUP_ 1538 MRR_RR_Detection_015_021 1 : MRR_RR_CAN_DET_Near_TARGET_021 MRR_RR_CAN_DET_Near_TARGET_020 MRR_RR_CAN_DET_Near_TARGET_019 MRR_RR_CAN_DET_Near_TARGET_018 MRR_RR_CAN_DET_Near_TARGET_017 MRR_RR_CAN_DET_Near_TARGET_016 MRR_RR_CAN_DET_Near_TARGET_015 MRR_RR_CAN_DET_MID_TARGET_015 MRR_RR_CAN_DET_MID_TARGET_016 MRR_RR_CAN_DET_MID_TARGET_017 MRR_RR_CAN_DET_MID_TARGET_018 MRR_RR_CAN_DET_MID_TARGET_019 MRR_RR_CAN_DET_MID_TARGET_020 MRR_RR_CAN_DET_MID_TARGET_021 MRR_RR_CAN_DET_ELEVATION_015 MRR_RR_CAN_DET_CONFID_AZIMU_0012 MRR_RR_CAN_DET_RANGE_017 MRR_RR_CAN_DET_RANGE_RATE_016 MRR_RR_CAN_DET_AMPLITUDE_016 MRR_RR_CAN_DET_SUPER_RES_TA_0013 MRR_RR_CAN_SCAN_INDEX_2LSB_016 MRR_RR_CAN_DET_VALID_LEVEL_015 MRR_RR_CAN_DET_RANGE_015 MRR_RR_CAN_DET_RANGE_018 MRR_RR_CAN_DET_CONFID_ELEVA_0013 MRR_RR_CAN_DET_AZIMUTH_015 MRR_RR_CAN_DET_HOST_VEH_CLU_0013 MRR_RR_CAN_DET_VALID_LEVEL_016 MRR_RR_CAN_DET_CONFID_AZIMU_0017 MRR_RR_CAN_DET_RANGE_016 MRR_RR_CAN_DET_AZIMUTH_016 MRR_RR_CAN_DET_ELEVATION_016 MRR_RR_CAN_DET_RANGE_RATE_015 MRR_RR_CAN_DET_HOST_VEH_CLU_0018 MRR_RR_CAN_DET_AMPLITUDE_017 MRR_RR_CAN_DET_RANGE_RATE_017 MRR_RR_CAN_DET_CONFID_ELEVA_0019 MRR_RR_CAN_DET_HOST_VEH_CLU_0019 MRR_RR_CAN_DET_CONFID_AZIMU_0016 MRR_RR_CAN_DET_AMPLITUDE_015 MRR_RR_CAN_DET_SUPER_RES_TA_0018 MRR_RR_CAN_SCAN_INDEX_2LSB_015 MRR_RR_CAN_DET_CONFID_ELEVA_0018 MRR_RR_DET_MC_003 MRR_RR_CAN_DET_ELEVATION_020 MRR_RR_CAN_DET_VALID_LEVEL_018 MRR_RR_CAN_DET_AMPLITUDE_018 MRR_RR_CAN_DET_ELEVATION_021 MRR_RR_CAN_DET_CONFID_AZIMU_0015 MRR_RR_CAN_DET_RANGE_RATE_018 MRR_RR_CAN_DET_RANGE_019 MRR_RR_CAN_DET_AMPLITUDE_019 MRR_RR_CAN_DET_AZIMUTH_020 MRR_RR_CAN_DET_HOST_VEH_CLU_0017 MRR_RR_CAN_DET_AZIMUTH_018 MRR_RR_CAN_DET_VALID_LEVEL_019 MRR_RR_CAN_DET_ELEVATION_018 MRR_RR_CAN_SCAN_INDEX_2LSB_017 MRR_RR_DET_CRC_003 MRR_RR_CAN_SCAN_INDEX_2LSB_019 MRR_RR_CAN_DET_AZIMUTH_017 MRR_RR_CAN_DET_RANGE_RATE_019 MRR_RR_CAN_DET_CONFID_AZIMU_0014 MRR_RR_CAN_DET_ELEVATION_017 MRR_RR_CAN_SCAN_INDEX_2LSB_018 MRR_RR_CAN_DET_SUPER_RES_TA_0017 MRR_RR_CAN_DET_AZIMUTH_019 MRR_RR_CAN_DET_RANGE_020 MRR_RR_CAN_DET_SUPER_RES_TA_0014 MRR_RR_CAN_DET_AZIMUTH_021 MRR_RR_CAN_DET_RANGE_RATE_021 MRR_RR_CAN_DET_RANGE_021 MRR_RR_CAN_DET_VALID_LEVEL_017 MRR_RR_CAN_DET_HOST_VEH_CLU_0016 MRR_RR_CAN_DET_CONFID_ELEVA_0016 MRR_RR_CAN_SCAN_INDEX_2LSB_020 MRR_RR_CAN_DET_CONFID_AZIMU_0013 MRR_RR_CAN_DET_HOST_VEH_CLU_0015 MRR_RR_CAN_DET_CONFID_ELEVA_0015 MRR_RR_CAN_DET_SUPER_RES_TA_0015 MRR_RR_CAN_DET_SUPER_RES_TA_0019 MRR_RR_CAN_DET_RANGE_RATE_020 MRR_RR_CAN_DET_SUPER_RES_TA_0016 MRR_RR_CAN_DET_ELEVATION_019 MRR_RR_CAN_DET_VALID_LEVEL_020 MRR_RR_CAN_DET_AMPLITUDE_020 MRR_RR_CAN_DET_CONFID_ELEVA_0017 MRR_RR_CAN_DET_VALID_LEVEL_021 MRR_RR_CAN_DET_AMPLITUDE_021 MRR_RR_CAN_SCAN_INDEX_2LSB_021 MRR_RR_CAN_DET_CONFID_AZIMUTH_02 MRR_RR_CAN_DET_CONFID_ELEVA_0014 MRR_RR_CAN_DET_HOST_VEH_CLU_0014;
